VERSION ""

NS_ :

BS_:

BU_: TCM_Diesel ECM_Diesel BECMB_EPM TCM ECM Generic_BCM GWM _delete APIM BCM DCDC_VQM PAM TSTR PCM

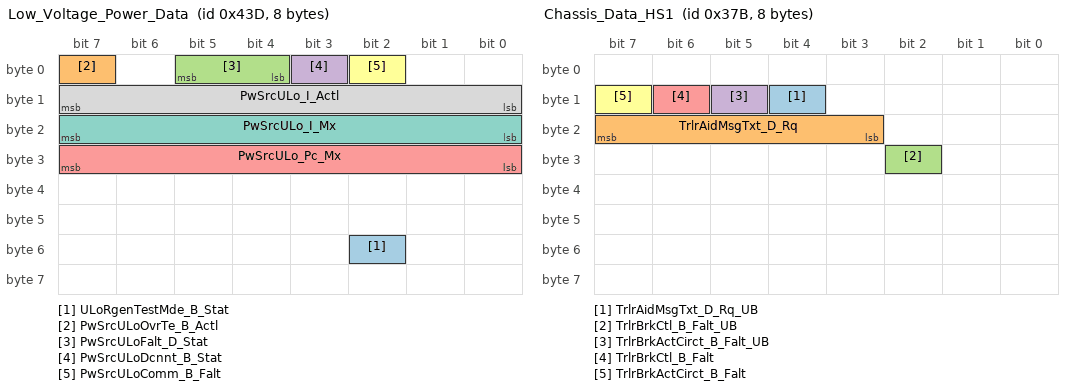
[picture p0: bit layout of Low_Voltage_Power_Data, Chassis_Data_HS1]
BO_ 1085 Low_Voltage_Power_Data: 8 PCM
 SG_ ULoRgenTestMde_B_Stat : 50|1@0+ (1,0) [0|1] "SED"  BCM
 SG_ PwSrcULoOvrTe_B_Actl : 7|1@0+ (1,0) [0|1] "SED"  BCM
 SG_ PwSrcULoFalt_D_Stat : 5|2@0+ (1,0) [0|3] "SED"  GWM,BCM
 SG_ PwSrcULoDcnnt_B_Stat : 3|1@0+ (1,0) [0|1] "SED"  BCM
 SG_ PwSrcULo_Pc_Mx : 31|8@0+ (0.4,0) [0|101.6] "%"  GWM,BCM
 SG_ PwSrcULoComm_B_Falt : 2|1@0+ (1,0) [0|1] "SED"  BCM
 SG_ PwSrcULo_I_Mx : 23|8@0+ (1,0) [0|254] "ampere"  GWM,BCM
 SG_ PwSrcULo_I_Actl : 15|8@0+ (1,0) [0|254] "ampere"  GWM,BCM

BO_ 891 Chassis_Data_HS1: 8 GWM
 SG_ TrlrAidMsgTxt_D_Rq_UB : 12|1@0+ (1,0) [0|1] "SED"  PAM
 SG_ TrlrAidMsgTxt_D_Rq : 23|5@0+ (1,0) [0|31] "SED"  PAM
 SG_ TrlrBrkCtl_B_Falt_UB : 26|1@0+ (1,0) [0|1] "SED"  PAM
 SG_ TrlrBrkActCirct_B_Falt_UB : 13|1@0+ (1,0) [0|1] "SED"  PAM
 SG_ TrlrBrkCtl_B_Falt : 14|1@0+ (1,0) [0|1] "SED"  PAM
 SG_ TrlrBrkActCirct_B_Falt : 15|1@0+ (1,0) [0|1] "SED"  PAM

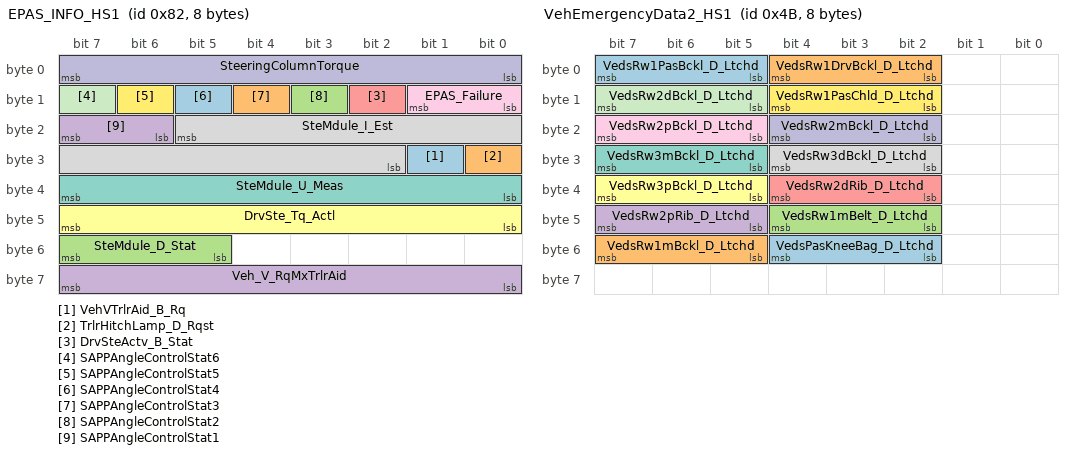
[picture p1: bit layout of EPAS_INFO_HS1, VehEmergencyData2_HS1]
BO_ 130 EPAS_INFO_HS1: 8 GWM
 SG_ VehVTrlrAid_B_Rq : 25|1@0+ (1,0) [0|1] "SED"  ECM_Diesel,ECM,PCM
 SG_ TrlrHitchLamp_D_Rqst : 24|1@0+ (1,0) [0|1] "SED"  BCM
 SG_ SteMdule_D_Stat : 55|3@0+ (1,0) [0|7] "SED" Vector__XXX
 SG_ Veh_V_RqMxTrlrAid : 63|8@0+ (0.1,0) [0|25.5] "km/h"  ECM_Diesel,ECM,PCM
 SG_ DrvSteActv_B_Stat : 10|1@0+ (1,0) [0|1] "SED" Vector__XXX
 SG_ DrvSte_Tq_Actl : 47|8@0+ (0.0625,-8) [-8|7.8125] "Nm" Vector__XXX
 SG_ SteMdule_U_Meas : 39|8@0+ (0.05,6) [6|18.7] "Volts"  BCM
 SG_ SteMdule_I_Est : 21|12@0+ (0.05,-64) [-64|140.7] "Amps"  BCM
 SG_ EPAS_Failure : 9|2@0+ (1,0) [0|3] "SED"  PAM
 SG_ SteeringColumnTorque : 7|8@0+ (0.0625,-8) [-8|7.8125] "Nm"  PAM
 SG_ SAPPAngleControlStat6 : 15|1@0+ (1,0) [0|1] "SED"  PAM
 SG_ SAPPAngleControlStat5 : 14|1@0+ (1,0) [0|1] "SED"  PAM
 SG_ SAPPAngleControlStat4 : 13|1@0+ (1,0) [0|1] "SED"  PAM
 SG_ SAPPAngleControlStat3 : 12|1@0+ (1,0) [0|1] "SED"  PAM
 SG_ SAPPAngleControlStat2 : 11|1@0+ (1,0) [0|1] "SED"  PAM
 SG_ SAPPAngleControlStat1 : 23|2@0+ (1,0) [0|3] "SED"  PAM

BO_ 75 VehEmergencyData2_HS1: 8 GWM
 SG_ VedsPasKneeBag_D_Ltchd : 52|3@0+ (1,0) [0|7] "SED"  APIM
 SG_ VedsRw1mBckl_D_Ltchd : 55|3@0+ (1,0) [0|7] "SED"  APIM
 SG_ VedsRw1mBelt_D_Ltchd : 44|3@0+ (1,0) [0|7] "SED"  APIM
 SG_ VedsRw2pRib_D_Ltchd : 47|3@0+ (1,0) [0|7] "SED"  APIM
 SG_ VedsRw2dRib_D_Ltchd : 36|3@0+ (1,0) [0|7] "SED"  APIM
 SG_ VedsRw3pBckl_D_Ltchd : 39|3@0+ (1,0) [0|7] "SED"  APIM
 SG_ VedsRw3mBckl_D_Ltchd : 31|3@0+ (1,0) [0|7] "SED"  APIM
 SG_ VedsRw3dBckl_D_Ltchd : 28|3@0+ (1,0) [0|7] "SED"  APIM
 SG_ VedsRw2pBckl_D_Ltchd : 23|3@0+ (1,0) [0|7] "SED"  APIM
 SG_ VedsRw2mBckl_D_Ltchd : 20|3@0+ (1,0) [0|7] "SED"  APIM
 SG_ VedsRw2dBckl_D_Ltchd : 15|3@0+ (1,0) [0|7] "SED"  APIM
 SG_ VedsRw1PasChld_D_Ltchd : 12|3@0+ (1,0) [0|7] "SED"  APIM
 SG_ VedsRw1PasBckl_D_Ltchd : 7|3@0+ (1,0) [0|7] "SED"  APIM
 SG_ VedsRw1DrvBckl_D_Ltchd : 4|3@0+ (1,0) [0|7] "SED"  APIM

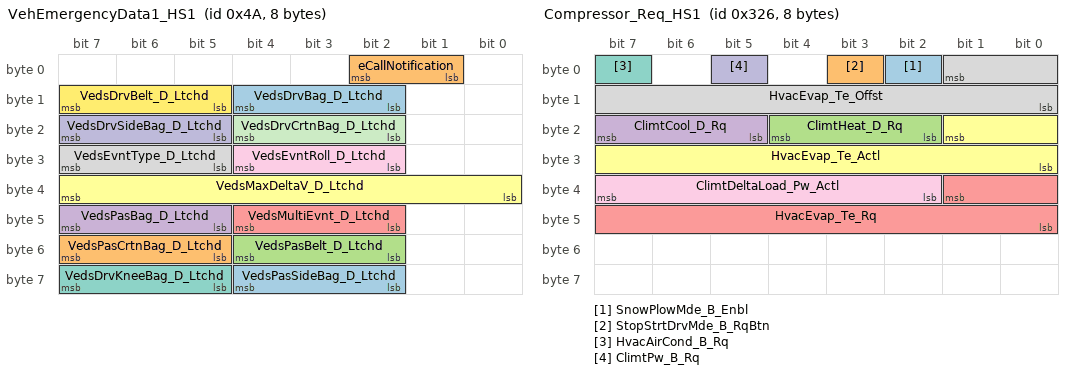
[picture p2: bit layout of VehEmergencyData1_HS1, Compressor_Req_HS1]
BO_ 74 VehEmergencyData1_HS1: 8 GWM
 SG_ VedsPasSideBag_D_Ltchd : 60|3@0+ (1,0) [0|7] "SED"  APIM
 SG_ VedsPasCrtnBag_D_Ltchd : 55|3@0+ (1,0) [0|7] "SED"  APIM
 SG_ VedsPasBelt_D_Ltchd : 52|3@0+ (1,0) [0|7] "SED"  APIM
 SG_ VedsPasBag_D_Ltchd : 47|3@0+ (1,0) [0|7] "SED"  APIM
 SG_ VedsMultiEvnt_D_Ltchd : 44|3@0+ (1,0) [0|7] "SED"  APIM
 SG_ VedsMaxDeltaV_D_Ltchd : 39|8@0+ (1,0) [0|255] "kph"  APIM
 SG_ VedsDrvKneeBag_D_Ltchd : 63|3@0+ (1,0) [0|7] "SED"  APIM
 SG_ VedsEvntType_D_Ltchd : 31|3@0+ (1,0) [0|7] "SED"  APIM
 SG_ VedsEvntRoll_D_Ltchd : 28|3@0+ (1,0) [0|7] "SED"  APIM
 SG_ VedsDrvSideBag_D_Ltchd : 23|3@0+ (1,0) [0|7] "SED"  APIM
 SG_ VedsDrvCrtnBag_D_Ltchd : 20|3@0+ (1,0) [0|7] "SED"  APIM
 SG_ VedsDrvBelt_D_Ltchd : 15|3@0+ (1,0) [0|7] "SED"  APIM
 SG_ VedsDrvBag_D_Ltchd : 12|3@0+ (1,0) [0|7] "SED"  APIM
 SG_ eCallNotification : 2|2@0+ (1,0) [0|3] "SED"  APIM

BO_ 1076 Cluster_Info3_HS1: 8 GWM
 SG_ CenterStackRing_D_Actl : 60|2@0+ (1,0) [0|3] "SED" Vector__XXX
 SG_ CenterStackRing_D_Actl_UB : 58|1@0+ (1,0) [0|1] "SED" Vector__XXX
 SG_ EngIdlShutDown_B_RqDrv_UB : 61|1@0+ (1,0) [0|1] "SED" Vector__XXX
 SG_ EngIdlShutDown_B_RqDrv : 62|1@0+ (1,0) [0|1] "SED"  ECM_Diesel,ECM,PCM
 SG_ OdoTripRx_B_Actl : 63|1@0+ (1,0) [0|1] "SED"  ECM_Diesel,ECM,PCM
 SG_ FuelLvlWarn_D_Actl : 49|2@0+ (1,0) [0|3] "SED" Vector__XXX
 SG_ TirePReset_B_Rq_UB : 18|1@0+ (1,0) [0|1] "SED"  BCM
 SG_ DrTGate_D_Rq : 51|2@0+ (1,0) [0|3] "SED"  BCM
 SG_ DrTGate_D_Rq_UB : 36|1@0+ (1,0) [0|1] "SED"  BCM
 SG_ Veh_V_CompLimMx : 35|12@0+ (0.1,0) [0|409.5] "km/h"  ECM_Diesel,ECM,PCM
 SG_ DieslFuelBio_B_ActlDrv : 3|1@0+ (1,0) [0|1] "SED"  ECM_Diesel
 SG_ FuelSecndActv_B_Actl : 7|1@0+ (1,0) [0|1] "SED"  ECM_Diesel
 SG_ FuelLvlPssvSide_No_Raw : 17|10@0+ (1,0) [0|1023] "Unitless"  ECM_Diesel,ECM,PCM
 SG_ FUEL_SENSOR_NUM : 2|1@0+ (1,0) [0|1] "SED"  ECM_Diesel,ECM,PCM
 SG_ FuelLvlActvSide_No_Raw : 1|10@0+ (1,0) [0|1023] "Unitless"  ECM_Diesel,ECM,PCM
 SG_ WndwPsngrSide_D_Stat : 53|2@0+ (1,0) [0|3] "SED"  ECM_Diesel,ECM,PCM
 SG_ WndwDrvSide_D_Stat : 55|2@0+ (1,0) [0|3] "SED"  ECM_Diesel,ECM,PCM
 SG_ WndwPsngrSide_D_Stat_UB : 56|1@0+ (1,0) [0|1] "SED"  ECM_Diesel,ECM,PCM
 SG_ DISPLAY_SPEED_SCALING : 23|4@0+ (0.5,100) [100|107.5] "%"  ECM_Diesel,ECM,PCM
 SG_ DISPLAY_SPEED_OFFSET : 6|3@0+ (0.5,0) [0|3.5] "kph"  ECM_Diesel,ECM,PCM
 SG_ WndwDrvSide_D_Stat_UB : 57|1@0+ (1,0) [0|1] "SED"  ECM_Diesel,ECM,PCM
 SG_ TirePReset_B_Rq : 19|1@0+ (1,0) [0|1] "Discrete"  BCM

BO_ 1072 Cluster_Info1_HS1: 8 GWM
 SG_ DrvPerfMde_D_Rq_UB : 56|1@0+ (1,0) [0|1] "SED" Vector__XXX
 SG_ DrvPerfMde_D_Rq : 55|2@0+ (1,0) [0|3] "SED" Vector__XXX
 SG_ ePRNDL_MODE_UB : 63|1@0+ (1,0) [0|1] "SED"  TCM_Diesel,TCM,ECM,PCM,BCM
 SG_ NtrlTowMdeEnbl_B_RqDrv_UB : 48|1@0+ (1,0) [0|1] "SED" Vector__XXX
 SG_ NtrlTowMdeEnbl_B_RqDrv : 6|1@0+ (1,0) [0|1] "SED" Vector__XXX
 SG_ Remote_Start_QuietMode_UB : 50|1@0+ (1,0) [0|1] "SED"  BCM
 SG_ Remote_Start_QuietMode : 51|1@0+ (1,0) [0|1] "SED"  BCM
 SG_ ParkDetect_Stat_UB : 52|1@0+ (1,0) [0|1] "SED"  BCM
 SG_ ParkDetect_Stat : 53|1@0+ (1,0) [0|1] "SED"  BCM
 SG_ TrlrLampCnnct_B_Actl_UB : 42|1@0+ (1,0) [0|1] "SED"  ECM_Diesel,ECM,PCM,BCM,PAM
 SG_ StopLamp_B_RqTrlrBrk_UB : 46|1@0+ (1,0) [0|1] "SED"  BCM
 SG_ StopLamp_B_RqTrlrBrk : 47|1@0+ (1,0) [0|1] "SED"  BCM
 SG_ OdometerMasterValue_UB : 1|1@0+ (1,0) [0|1] "SED"  BCM
 SG_ OdometerMasterValue : 15|24@0+ (1,0) [0|16777214] "km"  TCM_Diesel,ECM_Diesel,TCM,ECM,BCM,PCM
 SG_ MetricActv_B_Actl : 7|1@0+ (1,0) [0|1] "SED"  ECM_Diesel,ECM,PCM
 SG_ FrostWarn_D_Stat : 5|2@0+ (1,0) [0|3] "SED"  ECM_Diesel,ECM,PCM
 SG_ ReducedGuard_D_Rq_UB : 49|1@0+ (1,0) [0|1] "SED"  BCM
 SG_ ReducedGuard_D_Rq : 41|2@0+ (1,0) [0|3] "SED"  BCM
 SG_ ePRNDL_MODE : 0|1@0+ (1,0) [0|1] "SED"  TCM_Diesel,TCM,ECM,BCM,PCM
 SG_ EngOilLife_B_RqReset : 43|1@0+ (1,0) [0|1] "SED"  ECM_Diesel,ECM,PCM
 SG_ Outside_Air_Temp_Stat_UB : 2|1@0+ (1,0) [0|1] "SED"  PAM
 SG_ Outside_Air_Temp_Stat : 39|8@0+ (0.5,-40) [-40|86.5] "Degrees C"  ECM_Diesel,ECM,PCM,PAM
 SG_ KeyTypeChngMykey_D_Rq_UB : 60|1@0+ (1,0) [0|1] "SED"  BCM
 SG_ KeyTypeChngMykey_D_Rq : 62|2@0+ (1,0) [0|3] "SED"  BCM
 SG_ TrlrLampCnnct_B_Actl : 3|1@0+ (1,0) [0|1] "SED"  ECM_Diesel,ECM,BCM,PAM,PCM
 SG_ ManRgen_D_Rq : 45|2@0+ (1,0) [0|3] "SED"  ECM_Diesel

BO_ 1438 GWM_AutoSar_NetMgmt_HS1: 8 GWM
 SG_ GWM_AutoSar_NetworkMgmt_H1 : 7|64@0+ (1,0) [0|1.844674407371E+019] "unitless"  TCM_Diesel,ECM_Diesel,BECMB_EPM,TCM,ECM,BCM,PCM

BO_ 1814 TesterPhysicalReqGWM_H1: 8 TSTR
 SG_ TesterPhysicalReqGWM_H1 : 7|64@0+ (1,0) [0|1.84467E+019] "unitless"  GWM

BO_ 1822 TesterPhysicalResGWM_HS1: 8 GWM
 SG_ TesterPhysicalResGWM_H1 : 7|64@0+ (1,0) [0|1.84467E+019] "unitless"  TSTR

BO_ 806 Compressor_Req_HS1: 8 GWM
 SG_ SnowPlowMde_B_Enbl : 2|1@0+ (1,0) [0|1] "SED"  BCM
 SG_ StopStrtDrvMde_B_RqBtn : 3|1@0+ (1,0) [0|1] "SED"  ECM_Diesel,ECM,PCM
 SG_ ClimtHeat_D_Rq : 20|3@0+ (1,0) [0|7] "SED"  ECM_Diesel,ECM,PCM
 SG_ ClimtCool_D_Rq : 23|3@0+ (1,0) [0|7] "SED"  ECM_Diesel,ECM,PCM
 SG_ HvacEvap_Te_Rq : 33|10@0+ (0.125,-50) [-50|77.875] "Degrees C"  ECM_Diesel,ECM,PCM
 SG_ HvacEvap_Te_Actl : 17|10@0+ (0.125,-50) [-50|77.75] "Degrees C"  ECM_Diesel,ECM,PCM
 SG_ HvacAirCond_B_Rq : 7|1@0+ (1,0) [0|1] "SED"  ECM_Diesel,ECM,PCM
 SG_ HvacEvap_Te_Offst : 1|10@0+ (0.125,-50) [-50|77.875] "Degrees C"  ECM_Diesel,ECM,PCM
 SG_ ClimtDeltaLoad_Pw_Actl : 39|6@0+ (50,-1600) [-1600|1450] "watts" Vector__XXX
 SG_ ClimtPw_B_Rq : 5|1@0+ (1,0) [0|1] "SED"  ECM_Diesel,ECM,PCM

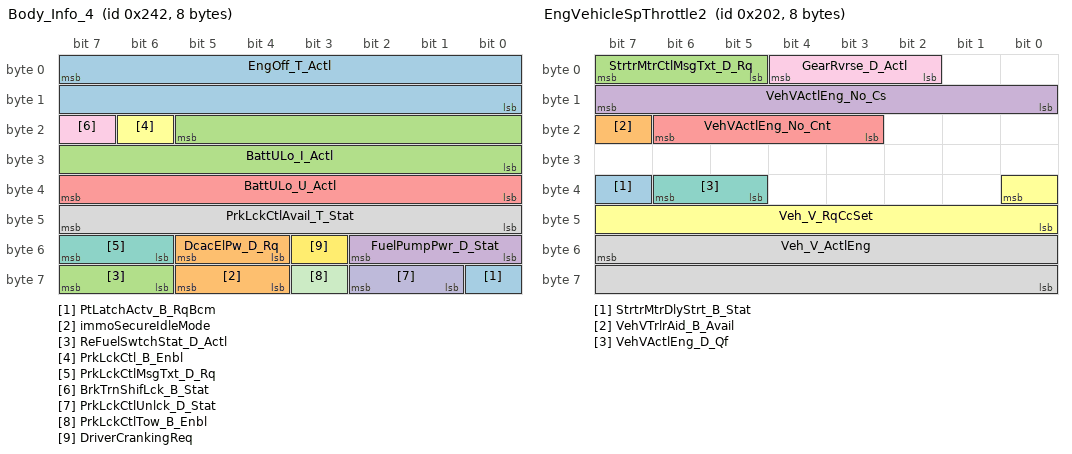
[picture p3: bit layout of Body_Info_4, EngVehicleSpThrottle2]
BO_ 578 Body_Info_4: 8 BCM
 SG_ PtLatchActv_B_RqBcm : 56|1@0+ (1,0) [0|1] "SED"  TCM_Diesel,ECM_Diesel,TCM,ECM,PCM,GWM
 SG_ immoSecureIdleMode : 61|2@0+ (1,0) [0|3] "SED"  ECM_Diesel,ECM,PCM,GWM
 SG_ ReFuelSwtchStat_D_Actl : 63|2@0+ (1,0) [0|3] "SED"  GWM
 SG_ FuelPumpPwr_D_Stat : 50|3@0+ (1,0) [0|7] "SED"  ECM_Diesel,ECM,PCM,GWM
 SG_ BattULo_U_Actl : 39|8@0+ (0.0625,0) [0|15.875] "volt"  ECM_Diesel,ECM,PCM,GWM
 SG_ PrkLckCtl_B_Enbl : 22|1@0+ (1,0) [0|1] "SED"  TCM_Diesel,TCM,GWM
 SG_ PrkLckCtlMsgTxt_D_Rq : 55|2@0+ (1,0) [0|3] "SED"  GWM
 SG_ PrkLckCtlAvail_T_Stat : 47|8@0+ (1,0) [0|255] "second"  GWM
 SG_ BrkTrnShifLck_B_Stat : 23|1@0+ (1,0) [0|1] "SED"  TCM,TCM_Diesel,GWM
 SG_ PrkLckCtlUnlck_D_Stat : 58|2@0+ (1,0) [0|3] "SED"  GWM
 SG_ PrkLckCtlTow_B_Enbl : 59|1@0+ (1,0) [0|1] "SED"  GWM
 SG_ DriverCrankingReq : 51|1@0+ (1,0) [0|1] "SED"  ECM_Diesel,ECM,GWM,PCM
 SG_ EngOff_T_Actl : 7|16@0+ (1,0) [0|65534] "second^0.5"  TCM_Diesel,ECM_Diesel,TCM,ECM,PCM,GWM
 SG_ DcacElPw_D_Rq : 53|2@0+ (1,0) [0|3] "SED"  ECM_Diesel,ECM,GWM,PCM
 SG_ BattULo_I_Actl : 21|14@0+ (0.0625,-512) [-512|511.875] "ampere"  ECM_Diesel,ECM,GWM,PCM

BO_ 514 EngVehicleSpThrottle2: 8 PCM
 SG_ StrtrMtrDlyStrt_B_Stat : 39|1@0+ (1,0) [0|1] "SED"  BCM
 SG_ VehVTrlrAid_B_Avail : 23|1@0+ (1,0) [0|1] "SED"  GWM
 SG_ StrtrMtrCtlMsgTxt_D_Rq : 7|3@0+ (1,0) [0|7] "SED"  GWM
 SG_ VehVActlEng_No_Cs : 15|8@0+ (1,0) [0|255] "Unitless"  GWM
 SG_ VehVActlEng_No_Cnt : 22|4@0+ (1,0) [0|15] "Unitless"  GWM
 SG_ Veh_V_RqCcSet : 32|9@0+ (0.5,0) [0|255.5] "kph"  TCM_Diesel,TCM,GWM
 SG_ VehVActlEng_D_Qf : 38|2@0+ (1,0) [0|3] "SED"  TCM_Diesel,TCM,PAM,BCM,GWM
 SG_ Veh_V_ActlEng : 55|16@0+ (0.01,0) [0|655.35] "kph"  TCM_Diesel,BECMB_EPM,TCM,PAM,BCM,GWM
 SG_ GearRvrse_D_Actl : 4|3@0+ (1,0) [0|7] "SED"  GWM,BCM,PAM

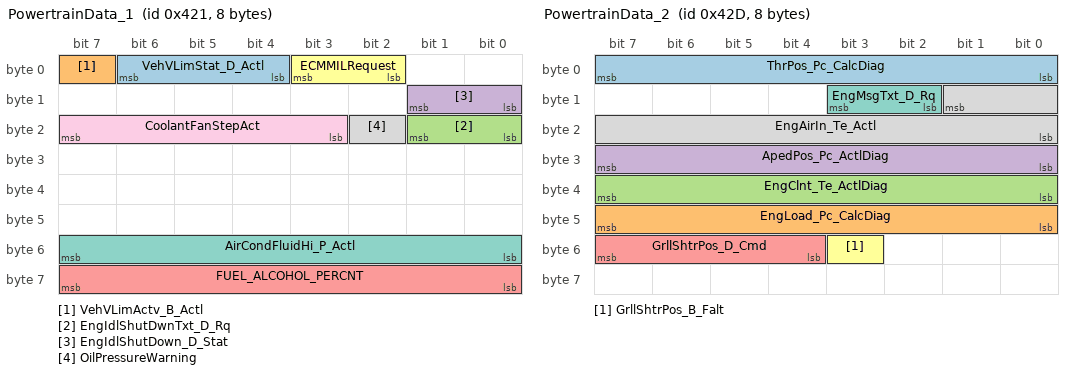
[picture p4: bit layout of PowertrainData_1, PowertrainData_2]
BO_ 1057 PowertrainData_1: 8 PCM
 SG_ VehVLimStat_D_Actl : 6|3@0+ (1,0) [0|7] "SED"  TCM_Diesel,GWM,TCM
 SG_ VehVLimActv_B_Actl : 7|1@0+ (1,0) [0|1] "SED"  TCM_Diesel,GWM,TCM
 SG_ EngIdlShutDwnTxt_D_Rq : 17|2@0+ (1,0) [0|3] "SED"  GWM
 SG_ EngIdlShutDown_D_Stat : 9|2@0+ (1,0) [0|3] "SED"  BCM,GWM
 SG_ FUEL_ALCOHOL_PERCNT : 63|8@0+ (0.393700787,0) [0|99.999899898] "Percent"  GWM
 SG_ ECMMILRequest : 3|2@0+ (1,0) [0|3] "SED"  BCM,GWM
 SG_ AirCondFluidHi_P_Actl : 55|8@0+ (0.125,0) [0|31.625] "bar"  GWM
 SG_ OilPressureWarning : 18|1@0+ (1,0) [0|1] "SED"  GWM
 SG_ CoolantFanStepAct : 23|5@0+ (1,0) [0|31] "Steps"  BCM,GWM

BO_ 1069 PowertrainData_2: 8 PCM
 SG_ ThrPos_Pc_CalcDiag : 7|8@0+ (0.392157,0) [0|100.000035] "%"  GWM
 SG_ EngLoad_Pc_CalcDiag : 47|8@0+ (0.392157,0) [0|100.000035] "%"  TCM_Diesel,GWM,TCM
 SG_ EngClnt_Te_ActlDiag : 39|8@0+ (1,-40) [-40|215] "degC"  TCM_Diesel,GWM,TCM
 SG_ ApedPos_Pc_ActlDiag : 31|8@0+ (0.392157,0) [0|100.000035] "%"  TCM_Diesel,GWM,TCM
 SG_ GrllShtrPos_D_Cmd : 55|4@0+ (1,0) [0|15] "SED"  GWM,BCM
 SG_ GrllShtrPos_B_Falt : 51|1@0+ (1,0) [0|1] "SED"  GWM,BCM
 SG_ EngMsgTxt_D_Rq : 11|2@0+ (1,0) [0|3] "SED"  GWM
 SG_ EngAirIn_Te_Actl : 9|10@0+ (0.25,-128) [-128|127.25] "degC"  TCM_Diesel,TCM,GWM,BCM

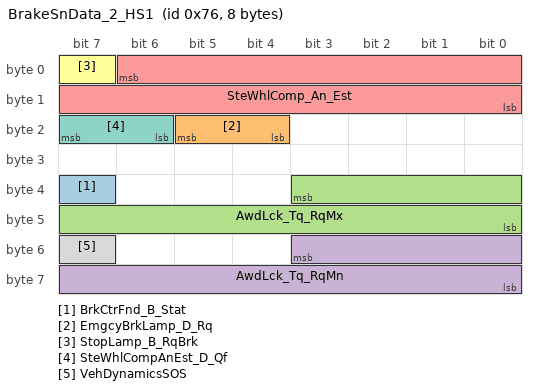
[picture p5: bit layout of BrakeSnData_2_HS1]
BO_ 118 BrakeSnData_2_HS1: 8 GWM
 SG_ BrkCtrFnd_B_Stat : 39|1@0+ (1,0) [0|1] "SED" Vector__XXX
 SG_ EmgcyBrkLamp_D_Rq : 21|2@0+ (1,0) [0|3] "SED"  BCM
 SG_ AwdLck_Tq_RqMx : 35|12@0+ (1,0) [0|4095] "Nm" Vector__XXX
 SG_ AwdLck_Tq_RqMn : 51|12@0+ (1,0) [0|4095] "Nm" Vector__XXX
 SG_ SteWhlComp_An_Est : 6|15@0+ (0.1,-1600) [-1600|1676.7] "deg"  TCM_Diesel,ECM_Diesel,TCM,ECM,BCM,PAM,PCM
 SG_ StopLamp_B_RqBrk : 7|1@0+ (1,0) [0|1] "SED"  BCM
 SG_ SteWhlCompAnEst_D_Qf : 23|2@0+ (1,0) [0|3] "SED"  TCM_Diesel,ECM_Diesel,TCM,ECM,BCM,PAM,PCM
 SG_ VehDynamicsSOS : 55|1@0+ (1,0) [0|1] "SED"  BCM

BO_TX_BU_ 1085 : ECM_Diesel,ECM,PCM;
BO_TX_BU_ 514 : ECM_Diesel,ECM,PCM;
BO_TX_BU_ 1057 : ECM_Diesel,ECM,PCM;
BO_TX_BU_ 1069 : ECM_Diesel,ECM,PCM;
CM_ SG_ 1085 ULoRgenTestMde_B_Stat "Signal not transmitted on HEV variants.";
CM_ SG_ 1085 PwSrcULoComm_B_Falt "Signal not transmitted on HEV variants.";
CM_ BO_ 130 "Added 5/13/05 for Mazda J61A/2007MY, T.Yamashita.";
CM_ SG_ 130 VehVTrlrAid_B_Rq "VR session start- req. limit blower speed no more than X volts.  CC restriction on time msg. will be honored.Double Event msg1st event to request limit, 2nd event to release limit, No msg. CC Grammar v7.xls";
CM_ BO_ 74 "Reserve eCallNotification message";
CM_ SG_ 1076 CenterStackRing_D_Actl "The Center Stack sends the CPLR a signal to turn On or Off the light Ring, This is a customer selectable preference switch";
CM_ SG_ 1072 StopLamp_B_RqTrlrBrk "Signal not transmitted on all variants.";
CM_ SG_ 1072 MetricActv_B_Actl "0 =Inactive(English), 1=Active(Metric)";
CM_ SG_ 1072 Outside_Air_Temp_Stat "Filtered value, i.e. same as disply for customer";
CM_ SG_ 1072 TrlrLampCnnct_B_Actl "Not supported on CD4 M1";
CM_ SG_ 514 GearRvrse_D_Actl "Do not implement GearRvrse_D_Actl  until eTracker 8804151 is approved, 11/24/09";
CM_ SG_ 1057 VehVLimStat_D_Actl "ECM_D and ECM_G Tx only on P552";
CM_ SG_ 1057 VehVLimActv_B_Actl "ECM_G and ECM_D Tx only on P552";
CM_ SG_ 1057 EngIdlShutDown_D_Stat "Signal not transmitted on diesel variants.";
CM_ SG_ 1057 FUEL_ALCOHOL_PERCNT "signal not transmitted on diesel and HEV variants.";
CM_ SG_ 1069 ThrPos_Pc_CalcDiag "ECM_D Tx only on P552";
CM_ SG_ 1069 EngLoad_Pc_CalcDiag "Tx by ECM_G and ECM_D";
CM_ SG_ 1069 EngClnt_Te_ActlDiag "Signal transmitted by ECM_D and ECM_G on P552 not PCM
";
CM_ SG_ 1069 ApedPos_Pc_ActlDiag "Signal not transmitted on gas variants.";
CM_ SG_ 1069 EngMsgTxt_D_Rq "Signal not transmitted on diesel variants.";
BA_DEF_ SG_  "U_U55x_MY18_Gas_Rx" ENUM  "No","Yes";
BA_DEF_ SG_  "U_U55x_MY18_Gas_Tx" ENUM  "No","Yes";
BA_DEF_ BO_  "FrameGatewayNetwork" STRING ;
BA_DEF_ SG_  "U_C489_MY17_Gas_Rx" ENUM  "No","Yes";
BA_DEF_ SG_  "U_CD43_MY17_Gas_Rx" ENUM  "No","Yes";
BA_DEF_ SG_  "U_P552_MY17_Gas_Rx" ENUM  "No","Yes";
BA_DEF_ SG_  "U_B515_MCA_MY17_Diesel_Rx" ENUM  "No","Yes";
BA_DEF_ SG_  "U_B515_MCA_MY17_Gas_Rx" ENUM  "No","Yes";
BA_DEF_ SG_  "U_C489_MY17_Gas_Tx" ENUM  "No","Yes";
BA_DEF_ SG_  "U_CD43_MY17_Gas_Tx" ENUM  "No","Yes";
BA_DEF_ SG_  "U_P552_MY17_Gas_Tx" ENUM  "No","Yes";
BA_DEF_ SG_  "U_B515_MCA_MY17_Diesel_Tx" ENUM  "No","Yes";
BA_DEF_ SG_  "U_B515_MCA_MY17_Gas_Tx" ENUM  "No","Yes";
BA_DEF_ SG_  "U_CD4_MY17_Diesel_Rx" ENUM  "No","Yes";
BA_DEF_ SG_  "U_CD4_MY17_Gas_Rx" ENUM  "No","Yes";
BA_DEF_ SG_  "U_CD4_MY17_Hev_Rx" ENUM  "No","Yes";
BA_DEF_ SG_  "U_CD4_MY17_Phev_Rx" ENUM  "No","Yes";
BA_DEF_ SG_  "U_CD42_MY16_Diesel_Rx" ENUM  "No","Yes";
BA_DEF_ SG_  "U_CD42_MY16_Gas_Rx" ENUM  "No","Yes";
BA_DEF_ SG_  "U_CD4_MY17_Diesel_Tx" ENUM  "No","Yes";
BA_DEF_ SG_  "U_CD4_MY17_Gas_Tx" ENUM  "No","Yes";
BA_DEF_ SG_  "U_CD4_MY17_Hev_Tx" ENUM  "No","Yes";
BA_DEF_ SG_  "U_CD4_MY17_Phev_Tx" ENUM  "No","Yes";
BA_DEF_ SG_  "U_CD42_MY16_Diesel_Tx" ENUM  "No","Yes";
BA_DEF_ SG_  "U_CD42_MY16_Gas_Tx" ENUM  "No","Yes";
BA_DEF_ SG_  "U_CD42_MY15_Diesel_Rx" ENUM  "No","Yes";
BA_DEF_ SG_  "U_CD42_MY15_Gas_Rx" ENUM  "No","Yes";
BA_DEF_ SG_  "U_U502_MY16_Gas_Rx" ENUM  "No","Yes";
BA_DEF_ SG_  "U_P558_MY17_Gas_Rx" ENUM  "No","Yes";
BA_DEF_ SG_  "U_P558_MY17_Diesel_Rx" ENUM  "No","Yes";
BA_DEF_ SG_  "U_V36X_MY16_5_Diesel_Rx" ENUM  "No","Yes";
BA_DEF_ SG_  "U_U502_MY16_Gas_Tx" ENUM  "No","Yes";
BA_DEF_ SG_  "U_P558_MY17_Gas_Tx" ENUM  "No","Yes";
BA_DEF_ SG_  "U_P558_MY17_Diesel_Tx" ENUM  "No","Yes";
BA_DEF_ SG_  "U_V36X_MY16_5_Diesel_Tx" ENUM  "No","Yes";
BA_DEF_ SG_  "GenSigTimeoutTime_TCM" INT 0 100000;
BA_DEF_ SG_  "Gateway_ID" INT 0 0;
BA_DEF_ BO_  "FrameGatewayMS1" HEX 0 1407;
BA_DEF_ BO_  "FrameGatewayHS2" HEX 0 1407;
BA_DEF_ BO_  "NetworkInitialization" ENUM  "No","Yes";
BA_DEF_ BO_  "FrameGatewayId" HEX 0 1407;
BA_DEF_ BO_  "GenMsgDelayTime" INT 0 1000;
BA_DEF_ BO_  "GenMsgCycleTime" INT 0 100000;
BA_DEF_ BO_  "GenMsgSendType" ENUM  "FixedPeriodic","Event","EnabledPeriodic","NotUsed","NotUsed","EventPeriodic","NotUsed","NotUsed","NoMsgSendType";
BA_DEF_ SG_  "U_CD4_MY14_Phev_Tx" ENUM  "No","Yes";
BA_DEF_ SG_  "U_CD4_MY14_Hev_Tx" ENUM  "No","Yes";
BA_DEF_ SG_  "U_CD4_MY14_Gas_Tx" ENUM  "No","Yes";
BA_DEF_ SG_  "U_CD4_MY14_Diesel_Tx" ENUM  "No","Yes";
BA_DEF_ SG_  "U_CD43_MY16_Gas_Tx" ENUM  "No","Yes";
BA_DEF_ SG_  "U_UP375_MY15_Diesel_Tx" ENUM  "No","Yes";
BA_DEF_ SG_  "U_UP375_MY15_Gas_Tx" ENUM  "No","Yes";
BA_DEF_ SG_  "U_U502_MY15_Gas_Tx" ENUM  "No","Yes";
BA_DEF_ SG_  "U_C489_MY14_Gas_Tx" ENUM  "No","Yes";
BA_DEF_ SG_  "U_S550_MY15_Gas_Tx" ENUM  "No","Yes";
BA_DEF_ SG_  "U_P552_MY15_Gas_Tx" ENUM  "No","Yes";
BA_DEF_ SG_  "U_CD42_MY14_Gas_Tx" ENUM  "No","Yes";
BA_DEF_ SG_  "U_CD42_MY14_Diesel_Tx" ENUM  "No","Yes";
BA_DEF_ SG_  "U_CD4_MY13_Phev_Tx" ENUM  "No","Yes";
BA_DEF_ SG_  "U_CD4_MY13_Hev_Tx" ENUM  "No","Yes";
BA_DEF_ SG_  "U_CD4_MY13_Gas_Tx" ENUM  "No","Yes";
BA_DEF_ SG_  "U_CD4_MY13_Diesel_Tx" ENUM  "No","Yes";
BA_DEF_ SG_  "U_CD4_MY14_Phev_Rx" ENUM  "No","Yes";
BA_DEF_ SG_  "U_CD4_MY14_Hev_Rx" ENUM  "No","Yes";
BA_DEF_ SG_  "U_CD4_MY14_Gas_Rx" ENUM  "No","Yes";
BA_DEF_ SG_  "U_CD4_MY14_Diesel_Rx" ENUM  "No","Yes";
BA_DEF_ SG_  "U_CD43_MY16_Gas_Rx" ENUM  "No","Yes";
BA_DEF_ SG_  "U_UP375_MY15_Diesel_Rx" ENUM  "No","Yes";
BA_DEF_ SG_  "U_UP375_MY15_Gas_Rx" ENUM  "No","Yes";
BA_DEF_ SG_  "U_B479_MY15_Gas_Rx" ENUM  "No","Yes";
BA_DEF_ SG_  "U_U502_MY15_Gas_Rx" ENUM  "No","Yes";
BA_DEF_ SG_  "U_C489_MY14_Gas_Rx" ENUM  "No","Yes";
BA_DEF_ SG_  "U_S550_MY15_Gas_Rx" ENUM  "No","Yes";
BA_DEF_ SG_  "U_P552_MY15_Gas_Rx" ENUM  "No","Yes";
BA_DEF_ SG_  "U_CD42_MY14_Gas_Rx" ENUM  "No","Yes";
BA_DEF_ SG_  "U_CD42_MY14_Diesel_Rx" ENUM  "No","Yes";
BA_DEF_ SG_  "U_CD4_MY13_Phev_Rx" ENUM  "No","Yes";
BA_DEF_ SG_  "U_CD4_MY13_Hev_Rx" ENUM  "No","Yes";
BA_DEF_ SG_  "U_CD4_MY13_Gas_Rx" ENUM  "No","Yes";
BA_DEF_ SG_  "U_CD4_MY13_Diesel_Rx" ENUM  "No","Yes";
BA_DEF_ SG_  "ContentDependant" ENUM  "No","Yes";
BA_DEF_ SG_  "GenSigStartValue" INT 0 1000000000;
BA_DEF_ SG_  "CrossOver_LIN" ENUM  "No","Yes";
BA_DEF_ SG_  "CrossOver_InfoCAN" ENUM  "No","Yes";
BA_DEF_ SG_  "WakeupSignal" ENUM  "No","Yes";
BA_DEF_ SG_  "GenSigMissingSourceValue" INT 0 1000000000;
BA_DEF_ SG_  "GenSigSendType" ENUM  "Cyclic","OnWrite","vector_leerstring","OnChange","vector_leerstring","IfActive","vector_leerstring","NoSigSendType";
BA_DEF_ BO_  "NmAsrMessage" ENUM  "No","Yes";
BA_DEF_ BO_  "DiagRequest" ENUM  "No","Yes";
BA_DEF_ BO_  "DiagResponse" ENUM  "No","Yes";
BA_DEF_ BO_  "GenMsgILSupport" ENUM  "No","Yes";
BA_DEF_DEF_  "U_U55x_MY18_Gas_Rx" "No";
BA_DEF_DEF_  "U_U55x_MY18_Gas_Tx" "No";
BA_DEF_DEF_  "FrameGatewayNetwork" "NONE";
BA_DEF_DEF_  "U_C489_MY17_Gas_Rx" "No";
BA_DEF_DEF_  "U_CD43_MY17_Gas_Rx" "No";
BA_DEF_DEF_  "U_P552_MY17_Gas_Rx" "No";
BA_DEF_DEF_  "U_B515_MCA_MY17_Diesel_Rx" "No";
BA_DEF_DEF_  "U_B515_MCA_MY17_Gas_Rx" "No";
BA_DEF_DEF_  "U_C489_MY17_Gas_Tx" "No";
BA_DEF_DEF_  "U_CD43_MY17_Gas_Tx" "No";
BA_DEF_DEF_  "U_P552_MY17_Gas_Tx" "No";
BA_DEF_DEF_  "U_B515_MCA_MY17_Diesel_Tx" "No";
BA_DEF_DEF_  "U_B515_MCA_MY17_Gas_Tx" "No";
BA_DEF_DEF_  "U_CD4_MY17_Diesel_Rx" "No";
BA_DEF_DEF_  "U_CD4_MY17_Gas_Rx" "No";
BA_DEF_DEF_  "U_CD4_MY17_Hev_Rx" "No";
BA_DEF_DEF_  "U_CD4_MY17_Phev_Rx" "No";
BA_DEF_DEF_  "U_CD42_MY16_Diesel_Rx" "No";
BA_DEF_DEF_  "U_CD42_MY16_Gas_Rx" "No";
BA_DEF_DEF_  "U_CD4_MY17_Diesel_Tx" "No";
BA_DEF_DEF_  "U_CD4_MY17_Gas_Tx" "No";
BA_DEF_DEF_  "U_CD4_MY17_Hev_Tx" "No";
BA_DEF_DEF_  "U_CD4_MY17_Phev_Tx" "No";
BA_DEF_DEF_  "U_CD42_MY16_Diesel_Tx" "No";
BA_DEF_DEF_  "U_CD42_MY16_Gas_Tx" "No";
BA_DEF_DEF_  "U_CD42_MY15_Diesel_Rx" "No";
BA_DEF_DEF_  "U_CD42_MY15_Gas_Rx" "No";
BA_DEF_DEF_  "U_U502_MY16_Gas_Rx" "No";
BA_DEF_DEF_  "U_P558_MY17_Gas_Rx" "No";
BA_DEF_DEF_  "U_P558_MY17_Diesel_Rx" "No";
BA_DEF_DEF_  "U_V36X_MY16_5_Diesel_Rx" "No";
BA_DEF_DEF_  "U_U502_MY16_Gas_Tx" "No";
BA_DEF_DEF_  "U_P558_MY17_Gas_Tx" "No";
BA_DEF_DEF_  "U_P558_MY17_Diesel_Tx" "No";
BA_DEF_DEF_  "U_V36X_MY16_5_Diesel_Tx" "No";
BA_DEF_DEF_  "GenSigTimeoutTime_TCM" 5000;
BA_DEF_DEF_  "Gateway_ID" 0;
BA_DEF_DEF_  "FrameGatewayMS1" 0;
BA_DEF_DEF_  "FrameGatewayHS2" 0;
BA_DEF_DEF_  "NetworkInitialization" "No";
BA_DEF_DEF_  "FrameGatewayId" 0;
BA_DEF_DEF_  "GenMsgDelayTime" 20;
BA_DEF_DEF_  "GenMsgCycleTime" 0;
BA_DEF_DEF_  "GenMsgSendType" "NoMsgSendType";
BA_DEF_DEF_  "U_CD4_MY14_Phev_Tx" "No";
BA_DEF_DEF_  "U_CD4_MY14_Hev_Tx" "No";
BA_DEF_DEF_  "U_CD4_MY14_Gas_Tx" "No";
BA_DEF_DEF_  "U_CD4_MY14_Diesel_Tx" "No";
BA_DEF_DEF_  "U_CD43_MY16_Gas_Tx" "No";
BA_DEF_DEF_  "U_UP375_MY15_Diesel_Tx" "No";
BA_DEF_DEF_  "U_UP375_MY15_Gas_Tx" "No";
BA_DEF_DEF_  "U_U502_MY15_Gas_Tx" "No";
BA_DEF_DEF_  "U_C489_MY14_Gas_Tx" "No";
BA_DEF_DEF_  "U_S550_MY15_Gas_Tx" "No";
BA_DEF_DEF_  "U_P552_MY15_Gas_Tx" "No";
BA_DEF_DEF_  "U_CD42_MY14_Gas_Tx" "No";
BA_DEF_DEF_  "U_CD42_MY14_Diesel_Tx" "No";
BA_DEF_DEF_  "U_CD4_MY13_Phev_Tx" "No";
BA_DEF_DEF_  "U_CD4_MY13_Hev_Tx" "No";
BA_DEF_DEF_  "U_CD4_MY13_Gas_Tx" "No";
BA_DEF_DEF_  "U_CD4_MY13_Diesel_Tx" "No";
BA_DEF_DEF_  "U_CD4_MY14_Phev_Rx" "No";
BA_DEF_DEF_  "U_CD4_MY14_Hev_Rx" "No";
BA_DEF_DEF_  "U_CD4_MY14_Gas_Rx" "No";
BA_DEF_DEF_  "U_CD4_MY14_Diesel_Rx" "No";
BA_DEF_DEF_  "U_CD43_MY16_Gas_Rx" "No";
BA_DEF_DEF_  "U_UP375_MY15_Diesel_Rx" "No";
BA_DEF_DEF_  "U_UP375_MY15_Gas_Rx" "No";
BA_DEF_DEF_  "U_B479_MY15_Gas_Rx" "No";
BA_DEF_DEF_  "U_U502_MY15_Gas_Rx" "No";
BA_DEF_DEF_  "U_C489_MY14_Gas_Rx" "No";
BA_DEF_DEF_  "U_S550_MY15_Gas_Rx" "No";
BA_DEF_DEF_  "U_P552_MY15_Gas_Rx" "No";
BA_DEF_DEF_  "U_CD42_MY14_Gas_Rx" "No";
BA_DEF_DEF_  "U_CD42_MY14_Diesel_Rx" "No";
BA_DEF_DEF_  "U_CD4_MY13_Phev_Rx" "No";
BA_DEF_DEF_  "U_CD4_MY13_Hev_Rx" "No";
BA_DEF_DEF_  "U_CD4_MY13_Gas_Rx" "No";
BA_DEF_DEF_  "U_CD4_MY13_Diesel_Rx" "No";
BA_DEF_DEF_  "ContentDependant" "No";
BA_DEF_DEF_  "GenSigStartValue" 0;
BA_DEF_DEF_  "CrossOver_LIN" "No";
BA_DEF_DEF_  "CrossOver_InfoCAN" "No";
BA_DEF_DEF_  "WakeupSignal" "No";
BA_DEF_DEF_  "GenSigMissingSourceValue" 0;
BA_DEF_DEF_  "GenSigSendType" "NoSigSendType";
BA_DEF_DEF_  "NmAsrMessage" "No";
BA_DEF_DEF_  "DiagRequest" "No";
BA_DEF_DEF_  "DiagResponse" "No";
BA_DEF_DEF_  "GenMsgILSupport" "Yes";
BA_ "GenMsgSendType" BO_ 1085 0;
BA_ "GenMsgCycleTime" BO_ 1085 50;
BA_ "GenMsgSendType" BO_ 891 0;
BA_ "GenMsgCycleTime" BO_ 891 100;
BA_ "FrameGatewayNetwork" BO_ 130 "HS2_CAN";
BA_ "GenMsgDelayTime" BO_ 130 10;
BA_ "FrameGatewayId" BO_ 130 130;
BA_ "FrameGatewayHS2" BO_ 130 130;
BA_ "FrameGatewayNetwork" BO_ 75 "HS2_CAN";
BA_ "FrameGatewayId" BO_ 75 75;
BA_ "FrameGatewayHS2" BO_ 75 75;
BA_ "FrameGatewayNetwork" BO_ 74 "HS2_CAN";
BA_ "FrameGatewayId" BO_ 74 74;
BA_ "FrameGatewayHS2" BO_ 74 74;
BA_ "GenMsgSendType" BO_ 1076 5;
BA_ "GenMsgCycleTime" BO_ 1076 100;
BA_ "GenMsgSendType" BO_ 1072 5;
BA_ "GenMsgCycleTime" BO_ 1072 100;
BA_ "GenMsgILSupport" BO_ 1438 0;
BA_ "NmAsrMessage" BO_ 1438 1;
BA_ "GenMsgSendType" BO_ 1438 1;
BA_ "GenMsgILSupport" BO_ 1814 0;
BA_ "DiagRequest" BO_ 1814 1;
BA_ "GenMsgSendType" BO_ 1814 1;
BA_ "GenMsgDelayTime" BO_ 1814 0;
BA_ "GenMsgILSupport" BO_ 1822 0;
BA_ "DiagResponse" BO_ 1822 1;
BA_ "GenMsgSendType" BO_ 1822 1;
BA_ "GenMsgDelayTime" BO_ 1822 0;
BA_ "FrameGatewayNetwork" BO_ 806 "MS1_CAN";
BA_ "FrameGatewayId" BO_ 806 806;
BA_ "FrameGatewayMS1" BO_ 806 806;
BA_ "GenMsgSendType" BO_ 578 0;
BA_ "GenMsgCycleTime" BO_ 578 40;
BA_ "GenMsgSendType" BO_ 514 0;
BA_ "GenMsgCycleTime" BO_ 514 20;
BA_ "GenMsgDelayTime" BO_ 514 10;
BA_ "GenMsgSendType" BO_ 1057 0;
BA_ "GenMsgCycleTime" BO_ 1057 100;
BA_ "NetworkInitialization" BO_ 1057 1;
BA_ "GenMsgSendType" BO_ 1069 0;
BA_ "GenMsgCycleTime" BO_ 1069 100;
BA_ "NetworkInitialization" BO_ 1069 1;
BA_ "FrameGatewayNetwork" BO_ 118 "HS2_CAN";
BA_ "GenMsgDelayTime" BO_ 118 10;
BA_ "FrameGatewayId" BO_ 118 118;
BA_ "FrameGatewayHS2" BO_ 118 118;
BA_ "NetworkInitialization" BO_ 118 1;
BA_ "ContentDependant" SG_ 1085 ULoRgenTestMde_B_Stat 1;
BA_ "U_CD4_MY13_Diesel_Rx" SG_ 1085 ULoRgenTestMde_B_Stat 1;
BA_ "U_CD4_MY13_Gas_Rx" SG_ 1085 ULoRgenTestMde_B_Stat 1;
BA_ "U_CD4_MY13_Hev_Rx" SG_ 1085 ULoRgenTestMde_B_Stat 1;
BA_ "U_CD4_MY13_Phev_Rx" SG_ 1085 ULoRgenTestMde_B_Stat 1;
BA_ "U_CD42_MY14_Diesel_Rx" SG_ 1085 ULoRgenTestMde_B_Stat 1;
BA_ "U_CD42_MY14_Gas_Rx" SG_ 1085 ULoRgenTestMde_B_Stat 1;
BA_ "U_P552_MY15_Gas_Rx" SG_ 1085 ULoRgenTestMde_B_Stat 1;
BA_ "U_S550_MY15_Gas_Rx" SG_ 1085 ULoRgenTestMde_B_Stat 1;
BA_ "U_C489_MY14_Gas_Rx" SG_ 1085 ULoRgenTestMde_B_Stat 1;
BA_ "U_U502_MY15_Gas_Rx" SG_ 1085 ULoRgenTestMde_B_Stat 1;
BA_ "U_UP375_MY15_Gas_Rx" SG_ 1085 ULoRgenTestMde_B_Stat 1;
BA_ "U_UP375_MY15_Diesel_Rx" SG_ 1085 ULoRgenTestMde_B_Stat 1;
BA_ "U_CD43_MY16_Gas_Rx" SG_ 1085 ULoRgenTestMde_B_Stat 1;
BA_ "U_CD4_MY14_Diesel_Rx" SG_ 1085 ULoRgenTestMde_B_Stat 1;
BA_ "U_CD4_MY14_Gas_Rx" SG_ 1085 ULoRgenTestMde_B_Stat 1;
BA_ "U_CD4_MY14_Hev_Rx" SG_ 1085 ULoRgenTestMde_B_Stat 1;
BA_ "U_CD4_MY14_Phev_Rx" SG_ 1085 ULoRgenTestMde_B_Stat 1;
BA_ "U_CD4_MY13_Gas_Tx" SG_ 1085 ULoRgenTestMde_B_Stat 1;
BA_ "U_CD42_MY14_Gas_Tx" SG_ 1085 ULoRgenTestMde_B_Stat 1;
BA_ "U_P552_MY15_Gas_Tx" SG_ 1085 ULoRgenTestMde_B_Stat 1;
BA_ "U_S550_MY15_Gas_Tx" SG_ 1085 ULoRgenTestMde_B_Stat 1;
BA_ "U_C489_MY14_Gas_Tx" SG_ 1085 ULoRgenTestMde_B_Stat 1;
BA_ "U_U502_MY15_Gas_Tx" SG_ 1085 ULoRgenTestMde_B_Stat 1;
BA_ "U_UP375_MY15_Gas_Tx" SG_ 1085 ULoRgenTestMde_B_Stat 1;
BA_ "U_CD43_MY16_Gas_Tx" SG_ 1085 ULoRgenTestMde_B_Stat 1;
BA_ "U_CD4_MY14_Gas_Tx" SG_ 1085 ULoRgenTestMde_B_Stat 1;
BA_ "U_CD4_MY13_Diesel_Rx" SG_ 1085 PwSrcULoOvrTe_B_Actl 1;
BA_ "U_CD4_MY13_Gas_Rx" SG_ 1085 PwSrcULoOvrTe_B_Actl 1;
BA_ "U_CD4_MY13_Hev_Rx" SG_ 1085 PwSrcULoOvrTe_B_Actl 1;
BA_ "U_CD4_MY13_Phev_Rx" SG_ 1085 PwSrcULoOvrTe_B_Actl 1;
BA_ "U_CD42_MY14_Diesel_Rx" SG_ 1085 PwSrcULoOvrTe_B_Actl 1;
BA_ "U_CD42_MY14_Gas_Rx" SG_ 1085 PwSrcULoOvrTe_B_Actl 1;
BA_ "U_P552_MY15_Gas_Rx" SG_ 1085 PwSrcULoOvrTe_B_Actl 1;
BA_ "U_S550_MY15_Gas_Rx" SG_ 1085 PwSrcULoOvrTe_B_Actl 1;
BA_ "U_C489_MY14_Gas_Rx" SG_ 1085 PwSrcULoOvrTe_B_Actl 1;
BA_ "U_U502_MY15_Gas_Rx" SG_ 1085 PwSrcULoOvrTe_B_Actl 1;
BA_ "U_UP375_MY15_Gas_Rx" SG_ 1085 PwSrcULoOvrTe_B_Actl 1;
BA_ "U_UP375_MY15_Diesel_Rx" SG_ 1085 PwSrcULoOvrTe_B_Actl 1;
BA_ "U_CD43_MY16_Gas_Rx" SG_ 1085 PwSrcULoOvrTe_B_Actl 1;
BA_ "U_CD4_MY14_Diesel_Rx" SG_ 1085 PwSrcULoOvrTe_B_Actl 1;
BA_ "U_CD4_MY14_Gas_Rx" SG_ 1085 PwSrcULoOvrTe_B_Actl 1;
BA_ "U_CD4_MY14_Hev_Rx" SG_ 1085 PwSrcULoOvrTe_B_Actl 1;
BA_ "U_CD4_MY14_Phev_Rx" SG_ 1085 PwSrcULoOvrTe_B_Actl 1;
BA_ "U_CD4_MY13_Gas_Tx" SG_ 1085 PwSrcULoOvrTe_B_Actl 1;
BA_ "U_CD42_MY14_Gas_Tx" SG_ 1085 PwSrcULoOvrTe_B_Actl 1;
BA_ "U_P552_MY15_Gas_Tx" SG_ 1085 PwSrcULoOvrTe_B_Actl 1;
BA_ "U_S550_MY15_Gas_Tx" SG_ 1085 PwSrcULoOvrTe_B_Actl 1;
BA_ "U_C489_MY14_Gas_Tx" SG_ 1085 PwSrcULoOvrTe_B_Actl 1;
BA_ "U_U502_MY15_Gas_Tx" SG_ 1085 PwSrcULoOvrTe_B_Actl 1;
BA_ "U_UP375_MY15_Gas_Tx" SG_ 1085 PwSrcULoOvrTe_B_Actl 1;
BA_ "U_CD43_MY16_Gas_Tx" SG_ 1085 PwSrcULoOvrTe_B_Actl 1;
BA_ "U_CD4_MY14_Gas_Tx" SG_ 1085 PwSrcULoOvrTe_B_Actl 1;
BA_ "U_CD4_MY13_Phev_Rx" SG_ 1085 PwSrcULoFalt_D_Stat 1;
BA_ "U_CD42_MY14_Diesel_Rx" SG_ 1085 PwSrcULoFalt_D_Stat 1;
BA_ "U_CD42_MY14_Gas_Rx" SG_ 1085 PwSrcULoFalt_D_Stat 1;
BA_ "U_P552_MY15_Gas_Rx" SG_ 1085 PwSrcULoFalt_D_Stat 1;
BA_ "U_S550_MY15_Gas_Rx" SG_ 1085 PwSrcULoFalt_D_Stat 1;
BA_ "U_C489_MY14_Gas_Rx" SG_ 1085 PwSrcULoFalt_D_Stat 1;
BA_ "U_U502_MY15_Gas_Rx" SG_ 1085 PwSrcULoFalt_D_Stat 1;
BA_ "U_UP375_MY15_Gas_Rx" SG_ 1085 PwSrcULoFalt_D_Stat 1;
BA_ "U_UP375_MY15_Diesel_Rx" SG_ 1085 PwSrcULoFalt_D_Stat 1;
BA_ "U_CD43_MY16_Gas_Rx" SG_ 1085 PwSrcULoFalt_D_Stat 1;
BA_ "U_CD4_MY14_Diesel_Rx" SG_ 1085 PwSrcULoFalt_D_Stat 1;
BA_ "U_CD4_MY14_Gas_Rx" SG_ 1085 PwSrcULoFalt_D_Stat 1;
BA_ "U_CD4_MY14_Hev_Rx" SG_ 1085 PwSrcULoFalt_D_Stat 1;
BA_ "U_CD4_MY14_Phev_Rx" SG_ 1085 PwSrcULoFalt_D_Stat 1;
BA_ "U_CD4_MY13_Gas_Tx" SG_ 1085 PwSrcULoFalt_D_Stat 1;
BA_ "U_CD42_MY14_Gas_Tx" SG_ 1085 PwSrcULoFalt_D_Stat 1;
BA_ "U_P552_MY15_Gas_Tx" SG_ 1085 PwSrcULoFalt_D_Stat 1;
BA_ "U_S550_MY15_Gas_Tx" SG_ 1085 PwSrcULoFalt_D_Stat 1;
BA_ "U_C489_MY14_Gas_Tx" SG_ 1085 PwSrcULoFalt_D_Stat 1;
BA_ "U_U502_MY15_Gas_Tx" SG_ 1085 PwSrcULoFalt_D_Stat 1;
BA_ "U_UP375_MY15_Gas_Tx" SG_ 1085 PwSrcULoFalt_D_Stat 1;
BA_ "U_CD43_MY16_Gas_Tx" SG_ 1085 PwSrcULoFalt_D_Stat 1;
BA_ "U_CD4_MY14_Gas_Tx" SG_ 1085 PwSrcULoFalt_D_Stat 1;
BA_ "U_CD4_MY13_Diesel_Rx" SG_ 1085 PwSrcULoDcnnt_B_Stat 1;
BA_ "U_CD4_MY13_Gas_Rx" SG_ 1085 PwSrcULoDcnnt_B_Stat 1;
BA_ "U_CD4_MY13_Hev_Rx" SG_ 1085 PwSrcULoDcnnt_B_Stat 1;
BA_ "U_CD4_MY13_Phev_Rx" SG_ 1085 PwSrcULoDcnnt_B_Stat 1;
BA_ "U_CD42_MY14_Diesel_Rx" SG_ 1085 PwSrcULoDcnnt_B_Stat 1;
BA_ "U_CD42_MY14_Gas_Rx" SG_ 1085 PwSrcULoDcnnt_B_Stat 1;
BA_ "U_P552_MY15_Gas_Rx" SG_ 1085 PwSrcULoDcnnt_B_Stat 1;
BA_ "U_S550_MY15_Gas_Rx" SG_ 1085 PwSrcULoDcnnt_B_Stat 1;
BA_ "U_C489_MY14_Gas_Rx" SG_ 1085 PwSrcULoDcnnt_B_Stat 1;
BA_ "U_U502_MY15_Gas_Rx" SG_ 1085 PwSrcULoDcnnt_B_Stat 1;
BA_ "U_UP375_MY15_Gas_Rx" SG_ 1085 PwSrcULoDcnnt_B_Stat 1;
BA_ "U_UP375_MY15_Diesel_Rx" SG_ 1085 PwSrcULoDcnnt_B_Stat 1;
BA_ "U_CD43_MY16_Gas_Rx" SG_ 1085 PwSrcULoDcnnt_B_Stat 1;
BA_ "U_CD4_MY14_Diesel_Rx" SG_ 1085 PwSrcULoDcnnt_B_Stat 1;
BA_ "U_CD4_MY14_Gas_Rx" SG_ 1085 PwSrcULoDcnnt_B_Stat 1;
BA_ "U_CD4_MY14_Hev_Rx" SG_ 1085 PwSrcULoDcnnt_B_Stat 1;
BA_ "U_CD4_MY14_Phev_Rx" SG_ 1085 PwSrcULoDcnnt_B_Stat 1;
BA_ "U_CD4_MY13_Gas_Tx" SG_ 1085 PwSrcULoDcnnt_B_Stat 1;
BA_ "U_CD42_MY14_Gas_Tx" SG_ 1085 PwSrcULoDcnnt_B_Stat 1;
BA_ "U_P552_MY15_Gas_Tx" SG_ 1085 PwSrcULoDcnnt_B_Stat 1;
BA_ "U_S550_MY15_Gas_Tx" SG_ 1085 PwSrcULoDcnnt_B_Stat 1;
BA_ "U_C489_MY14_Gas_Tx" SG_ 1085 PwSrcULoDcnnt_B_Stat 1;
BA_ "U_U502_MY15_Gas_Tx" SG_ 1085 PwSrcULoDcnnt_B_Stat 1;
BA_ "U_UP375_MY15_Gas_Tx" SG_ 1085 PwSrcULoDcnnt_B_Stat 1;
BA_ "U_CD43_MY16_Gas_Tx" SG_ 1085 PwSrcULoDcnnt_B_Stat 1;
BA_ "U_CD4_MY14_Gas_Tx" SG_ 1085 PwSrcULoDcnnt_B_Stat 1;
BA_ "U_CD4_MY13_Phev_Rx" SG_ 1085 PwSrcULo_Pc_Mx 1;
BA_ "U_CD42_MY14_Diesel_Rx" SG_ 1085 PwSrcULo_Pc_Mx 1;
BA_ "U_CD42_MY14_Gas_Rx" SG_ 1085 PwSrcULo_Pc_Mx 1;
BA_ "U_P552_MY15_Gas_Rx" SG_ 1085 PwSrcULo_Pc_Mx 1;
BA_ "U_S550_MY15_Gas_Rx" SG_ 1085 PwSrcULo_Pc_Mx 1;
BA_ "U_C489_MY14_Gas_Rx" SG_ 1085 PwSrcULo_Pc_Mx 1;
BA_ "U_U502_MY15_Gas_Rx" SG_ 1085 PwSrcULo_Pc_Mx 1;
BA_ "U_UP375_MY15_Gas_Rx" SG_ 1085 PwSrcULo_Pc_Mx 1;
BA_ "U_UP375_MY15_Diesel_Rx" SG_ 1085 PwSrcULo_Pc_Mx 1;
BA_ "U_CD43_MY16_Gas_Rx" SG_ 1085 PwSrcULo_Pc_Mx 1;
BA_ "U_CD4_MY14_Diesel_Rx" SG_ 1085 PwSrcULo_Pc_Mx 1;
BA_ "U_CD4_MY14_Gas_Rx" SG_ 1085 PwSrcULo_Pc_Mx 1;
BA_ "U_CD4_MY14_Hev_Rx" SG_ 1085 PwSrcULo_Pc_Mx 1;
BA_ "U_CD4_MY14_Phev_Rx" SG_ 1085 PwSrcULo_Pc_Mx 1;
BA_ "U_CD4_MY13_Gas_Tx" SG_ 1085 PwSrcULo_Pc_Mx 1;
BA_ "U_CD42_MY14_Gas_Tx" SG_ 1085 PwSrcULo_Pc_Mx 1;
BA_ "U_P552_MY15_Gas_Tx" SG_ 1085 PwSrcULo_Pc_Mx 1;
BA_ "U_S550_MY15_Gas_Tx" SG_ 1085 PwSrcULo_Pc_Mx 1;
BA_ "U_C489_MY14_Gas_Tx" SG_ 1085 PwSrcULo_Pc_Mx 1;
BA_ "U_U502_MY15_Gas_Tx" SG_ 1085 PwSrcULo_Pc_Mx 1;
BA_ "U_UP375_MY15_Gas_Tx" SG_ 1085 PwSrcULo_Pc_Mx 1;
BA_ "U_CD43_MY16_Gas_Tx" SG_ 1085 PwSrcULo_Pc_Mx 1;
BA_ "U_CD4_MY14_Gas_Tx" SG_ 1085 PwSrcULo_Pc_Mx 1;
BA_ "ContentDependant" SG_ 1085 PwSrcULoComm_B_Falt 1;
BA_ "U_CD4_MY13_Diesel_Rx" SG_ 1085 PwSrcULoComm_B_Falt 1;
BA_ "U_CD4_MY13_Gas_Rx" SG_ 1085 PwSrcULoComm_B_Falt 1;
BA_ "U_CD4_MY13_Hev_Rx" SG_ 1085 PwSrcULoComm_B_Falt 1;
BA_ "U_CD4_MY13_Phev_Rx" SG_ 1085 PwSrcULoComm_B_Falt 1;
BA_ "U_CD42_MY14_Diesel_Rx" SG_ 1085 PwSrcULoComm_B_Falt 1;
BA_ "U_CD42_MY14_Gas_Rx" SG_ 1085 PwSrcULoComm_B_Falt 1;
BA_ "U_P552_MY15_Gas_Rx" SG_ 1085 PwSrcULoComm_B_Falt 1;
BA_ "U_S550_MY15_Gas_Rx" SG_ 1085 PwSrcULoComm_B_Falt 1;
BA_ "U_C489_MY14_Gas_Rx" SG_ 1085 PwSrcULoComm_B_Falt 1;
BA_ "U_U502_MY15_Gas_Rx" SG_ 1085 PwSrcULoComm_B_Falt 1;
BA_ "U_UP375_MY15_Gas_Rx" SG_ 1085 PwSrcULoComm_B_Falt 1;
BA_ "U_UP375_MY15_Diesel_Rx" SG_ 1085 PwSrcULoComm_B_Falt 1;
BA_ "U_CD43_MY16_Gas_Rx" SG_ 1085 PwSrcULoComm_B_Falt 1;
BA_ "U_CD4_MY14_Diesel_Rx" SG_ 1085 PwSrcULoComm_B_Falt 1;
BA_ "U_CD4_MY14_Gas_Rx" SG_ 1085 PwSrcULoComm_B_Falt 1;
BA_ "U_CD4_MY14_Hev_Rx" SG_ 1085 PwSrcULoComm_B_Falt 1;
BA_ "U_CD4_MY14_Phev_Rx" SG_ 1085 PwSrcULoComm_B_Falt 1;
BA_ "U_CD4_MY13_Gas_Tx" SG_ 1085 PwSrcULoComm_B_Falt 1;
BA_ "U_CD42_MY14_Gas_Tx" SG_ 1085 PwSrcULoComm_B_Falt 1;
BA_ "U_P552_MY15_Gas_Tx" SG_ 1085 PwSrcULoComm_B_Falt 1;
BA_ "U_S550_MY15_Gas_Tx" SG_ 1085 PwSrcULoComm_B_Falt 1;
BA_ "U_C489_MY14_Gas_Tx" SG_ 1085 PwSrcULoComm_B_Falt 1;
BA_ "U_U502_MY15_Gas_Tx" SG_ 1085 PwSrcULoComm_B_Falt 1;
BA_ "U_UP375_MY15_Gas_Tx" SG_ 1085 PwSrcULoComm_B_Falt 1;
BA_ "U_CD43_MY16_Gas_Tx" SG_ 1085 PwSrcULoComm_B_Falt 1;
BA_ "U_CD4_MY14_Gas_Tx" SG_ 1085 PwSrcULoComm_B_Falt 1;
BA_ "U_CD4_MY13_Diesel_Rx" SG_ 1085 PwSrcULo_I_Mx 1;
BA_ "U_CD4_MY13_Gas_Rx" SG_ 1085 PwSrcULo_I_Mx 1;
BA_ "U_CD4_MY13_Hev_Rx" SG_ 1085 PwSrcULo_I_Mx 1;
BA_ "U_CD4_MY13_Phev_Rx" SG_ 1085 PwSrcULo_I_Mx 1;
BA_ "U_CD42_MY14_Diesel_Rx" SG_ 1085 PwSrcULo_I_Mx 1;
BA_ "U_CD42_MY14_Gas_Rx" SG_ 1085 PwSrcULo_I_Mx 1;
BA_ "U_P552_MY15_Gas_Rx" SG_ 1085 PwSrcULo_I_Mx 1;
BA_ "U_S550_MY15_Gas_Rx" SG_ 1085 PwSrcULo_I_Mx 1;
BA_ "U_C489_MY14_Gas_Rx" SG_ 1085 PwSrcULo_I_Mx 1;
BA_ "U_U502_MY15_Gas_Rx" SG_ 1085 PwSrcULo_I_Mx 1;
BA_ "U_UP375_MY15_Gas_Rx" SG_ 1085 PwSrcULo_I_Mx 1;
BA_ "U_UP375_MY15_Diesel_Rx" SG_ 1085 PwSrcULo_I_Mx 1;
BA_ "U_CD43_MY16_Gas_Rx" SG_ 1085 PwSrcULo_I_Mx 1;
BA_ "U_CD4_MY14_Diesel_Rx" SG_ 1085 PwSrcULo_I_Mx 1;
BA_ "U_CD4_MY14_Gas_Rx" SG_ 1085 PwSrcULo_I_Mx 1;
BA_ "U_CD4_MY14_Hev_Rx" SG_ 1085 PwSrcULo_I_Mx 1;
BA_ "U_CD4_MY14_Phev_Rx" SG_ 1085 PwSrcULo_I_Mx 1;
BA_ "U_CD4_MY13_Gas_Tx" SG_ 1085 PwSrcULo_I_Mx 1;
BA_ "U_CD42_MY14_Gas_Tx" SG_ 1085 PwSrcULo_I_Mx 1;
BA_ "U_P552_MY15_Gas_Tx" SG_ 1085 PwSrcULo_I_Mx 1;
BA_ "U_S550_MY15_Gas_Tx" SG_ 1085 PwSrcULo_I_Mx 1;
BA_ "U_C489_MY14_Gas_Tx" SG_ 1085 PwSrcULo_I_Mx 1;
BA_ "U_U502_MY15_Gas_Tx" SG_ 1085 PwSrcULo_I_Mx 1;
BA_ "U_UP375_MY15_Gas_Tx" SG_ 1085 PwSrcULo_I_Mx 1;
BA_ "U_CD43_MY16_Gas_Tx" SG_ 1085 PwSrcULo_I_Mx 1;
BA_ "U_CD4_MY14_Gas_Tx" SG_ 1085 PwSrcULo_I_Mx 1;
BA_ "U_CD4_MY13_Diesel_Rx" SG_ 1085 PwSrcULo_I_Actl 1;
BA_ "U_CD4_MY13_Gas_Rx" SG_ 1085 PwSrcULo_I_Actl 1;
BA_ "U_CD4_MY13_Hev_Rx" SG_ 1085 PwSrcULo_I_Actl 1;
BA_ "U_CD4_MY13_Phev_Rx" SG_ 1085 PwSrcULo_I_Actl 1;
BA_ "U_CD42_MY14_Diesel_Rx" SG_ 1085 PwSrcULo_I_Actl 1;
BA_ "U_CD42_MY14_Gas_Rx" SG_ 1085 PwSrcULo_I_Actl 1;
BA_ "U_P552_MY15_Gas_Rx" SG_ 1085 PwSrcULo_I_Actl 1;
BA_ "U_S550_MY15_Gas_Rx" SG_ 1085 PwSrcULo_I_Actl 1;
BA_ "U_C489_MY14_Gas_Rx" SG_ 1085 PwSrcULo_I_Actl 1;
BA_ "U_U502_MY15_Gas_Rx" SG_ 1085 PwSrcULo_I_Actl 1;
BA_ "U_UP375_MY15_Gas_Rx" SG_ 1085 PwSrcULo_I_Actl 1;
BA_ "U_UP375_MY15_Diesel_Rx" SG_ 1085 PwSrcULo_I_Actl 1;
BA_ "U_CD43_MY16_Gas_Rx" SG_ 1085 PwSrcULo_I_Actl 1;
BA_ "U_CD4_MY14_Diesel_Rx" SG_ 1085 PwSrcULo_I_Actl 1;
BA_ "U_CD4_MY14_Gas_Rx" SG_ 1085 PwSrcULo_I_Actl 1;
BA_ "U_CD4_MY14_Hev_Rx" SG_ 1085 PwSrcULo_I_Actl 1;
BA_ "U_CD4_MY14_Phev_Rx" SG_ 1085 PwSrcULo_I_Actl 1;
BA_ "U_CD4_MY13_Gas_Tx" SG_ 1085 PwSrcULo_I_Actl 1;
BA_ "U_CD42_MY14_Gas_Tx" SG_ 1085 PwSrcULo_I_Actl 1;
BA_ "U_P552_MY15_Gas_Tx" SG_ 1085 PwSrcULo_I_Actl 1;
BA_ "U_S550_MY15_Gas_Tx" SG_ 1085 PwSrcULo_I_Actl 1;
BA_ "U_C489_MY14_Gas_Tx" SG_ 1085 PwSrcULo_I_Actl 1;
BA_ "U_U502_MY15_Gas_Tx" SG_ 1085 PwSrcULo_I_Actl 1;
BA_ "U_UP375_MY15_Gas_Tx" SG_ 1085 PwSrcULo_I_Actl 1;
BA_ "U_CD43_MY16_Gas_Tx" SG_ 1085 PwSrcULo_I_Actl 1;
BA_ "U_CD4_MY14_Gas_Tx" SG_ 1085 PwSrcULo_I_Actl 1;
BA_ "U_P552_MY15_Gas_Rx" SG_ 891 TrlrBrkCtl_B_Falt_UB 1;
BA_ "U_P552_MY15_Gas_Rx" SG_ 891 TrlrBrkActCirct_B_Falt_UB 1;
BA_ "U_P552_MY15_Gas_Rx" SG_ 891 TrlrBrkCtl_B_Falt 1;
BA_ "U_P552_MY15_Gas_Rx" SG_ 891 TrlrBrkActCirct_B_Falt 1;
BA_ "Gateway_ID" SG_ 130 VehVTrlrAid_B_Rq 27629;
BA_ "CrossOver_InfoCAN" SG_ 130 VehVTrlrAid_B_Rq 1;
BA_ "Gateway_ID" SG_ 130 TrlrHitchLamp_D_Rqst 27642;
BA_ "U_UP375_MY15_Diesel_Rx" SG_ 130 TrlrHitchLamp_D_Rqst 1;
BA_ "U_UP375_MY15_Gas_Rx" SG_ 130 TrlrHitchLamp_D_Rqst 1;
BA_ "CrossOver_LIN" SG_ 130 TrlrHitchLamp_D_Rqst 1;
BA_ "CrossOver_InfoCAN" SG_ 130 TrlrHitchLamp_D_Rqst 1;
BA_ "GenSigStartValue" SG_ 130 Veh_V_RqMxTrlrAid 255;
BA_ "U_P552_MY15_Gas_Rx" SG_ 130 Veh_V_RqMxTrlrAid 1;
BA_ "GenSigStartValue" SG_ 130 DrvSte_Tq_Actl 128;
BA_ "GenSigStartValue" SG_ 130 SteMdule_U_Meas 255;
BA_ "U_CD4_MY13_Diesel_Rx" SG_ 130 SteMdule_U_Meas 1;
BA_ "U_CD4_MY13_Gas_Rx" SG_ 130 SteMdule_U_Meas 1;
BA_ "U_CD4_MY13_Hev_Rx" SG_ 130 SteMdule_U_Meas 1;
BA_ "U_CD4_MY13_Phev_Rx" SG_ 130 SteMdule_U_Meas 1;
BA_ "U_CD42_MY14_Diesel_Rx" SG_ 130 SteMdule_U_Meas 1;
BA_ "U_CD42_MY14_Gas_Rx" SG_ 130 SteMdule_U_Meas 1;
BA_ "U_P552_MY15_Gas_Rx" SG_ 130 SteMdule_U_Meas 1;
BA_ "U_S550_MY15_Gas_Rx" SG_ 130 SteMdule_U_Meas 1;
BA_ "U_C489_MY14_Gas_Rx" SG_ 130 SteMdule_U_Meas 1;
BA_ "U_U502_MY15_Gas_Rx" SG_ 130 SteMdule_U_Meas 1;
BA_ "U_UP375_MY15_Gas_Rx" SG_ 130 SteMdule_U_Meas 1;
BA_ "U_UP375_MY15_Diesel_Rx" SG_ 130 SteMdule_U_Meas 1;
BA_ "U_CD43_MY16_Gas_Rx" SG_ 130 SteMdule_U_Meas 1;
BA_ "U_CD4_MY14_Diesel_Rx" SG_ 130 SteMdule_U_Meas 1;
BA_ "U_CD4_MY14_Gas_Rx" SG_ 130 SteMdule_U_Meas 1;
BA_ "U_CD4_MY14_Hev_Rx" SG_ 130 SteMdule_U_Meas 1;
BA_ "U_CD4_MY14_Phev_Rx" SG_ 130 SteMdule_U_Meas 1;
BA_ "GenSigStartValue" SG_ 130 SteMdule_I_Est 4095;
BA_ "U_CD4_MY13_Diesel_Rx" SG_ 130 SteMdule_I_Est 1;
BA_ "U_CD4_MY13_Gas_Rx" SG_ 130 SteMdule_I_Est 1;
BA_ "U_CD4_MY13_Hev_Rx" SG_ 130 SteMdule_I_Est 1;
BA_ "U_CD4_MY13_Phev_Rx" SG_ 130 SteMdule_I_Est 1;
BA_ "U_CD42_MY14_Diesel_Rx" SG_ 130 SteMdule_I_Est 1;
BA_ "U_CD42_MY14_Gas_Rx" SG_ 130 SteMdule_I_Est 1;
BA_ "U_P552_MY15_Gas_Rx" SG_ 130 SteMdule_I_Est 1;
BA_ "U_S550_MY15_Gas_Rx" SG_ 130 SteMdule_I_Est 1;
BA_ "U_C489_MY14_Gas_Rx" SG_ 130 SteMdule_I_Est 1;
BA_ "U_U502_MY15_Gas_Rx" SG_ 130 SteMdule_I_Est 1;
BA_ "U_UP375_MY15_Gas_Rx" SG_ 130 SteMdule_I_Est 1;
BA_ "U_UP375_MY15_Diesel_Rx" SG_ 130 SteMdule_I_Est 1;
BA_ "U_CD43_MY16_Gas_Rx" SG_ 130 SteMdule_I_Est 1;
BA_ "U_CD4_MY14_Diesel_Rx" SG_ 130 SteMdule_I_Est 1;
BA_ "U_CD4_MY14_Gas_Rx" SG_ 130 SteMdule_I_Est 1;
BA_ "U_CD4_MY14_Hev_Rx" SG_ 130 SteMdule_I_Est 1;
BA_ "U_CD4_MY14_Phev_Rx" SG_ 130 SteMdule_I_Est 1;
BA_ "CrossOver_InfoCAN" SG_ 130 EPAS_Failure 1;
BA_ "U_CD4_MY13_Diesel_Rx" SG_ 130 EPAS_Failure 1;
BA_ "U_CD4_MY13_Gas_Rx" SG_ 130 EPAS_Failure 1;
BA_ "U_CD4_MY13_Hev_Rx" SG_ 130 EPAS_Failure 1;
BA_ "U_CD4_MY13_Phev_Rx" SG_ 130 EPAS_Failure 1;
BA_ "U_CD42_MY14_Diesel_Rx" SG_ 130 EPAS_Failure 1;
BA_ "U_CD42_MY14_Gas_Rx" SG_ 130 EPAS_Failure 1;
BA_ "U_P552_MY15_Gas_Rx" SG_ 130 EPAS_Failure 1;
BA_ "U_C489_MY14_Gas_Rx" SG_ 130 EPAS_Failure 1;
BA_ "U_U502_MY15_Gas_Rx" SG_ 130 EPAS_Failure 1;
BA_ "U_UP375_MY15_Gas_Rx" SG_ 130 EPAS_Failure 1;
BA_ "U_UP375_MY15_Diesel_Rx" SG_ 130 EPAS_Failure 1;
BA_ "U_CD43_MY16_Gas_Rx" SG_ 130 EPAS_Failure 1;
BA_ "U_CD4_MY14_Diesel_Rx" SG_ 130 EPAS_Failure 1;
BA_ "U_CD4_MY14_Gas_Rx" SG_ 130 EPAS_Failure 1;
BA_ "U_CD4_MY14_Hev_Rx" SG_ 130 EPAS_Failure 1;
BA_ "U_CD4_MY14_Phev_Rx" SG_ 130 EPAS_Failure 1;
BA_ "GenSigStartValue" SG_ 130 SteeringColumnTorque 254;
BA_ "U_CD4_MY13_Diesel_Rx" SG_ 130 SteeringColumnTorque 1;
BA_ "U_CD4_MY13_Gas_Rx" SG_ 130 SteeringColumnTorque 1;
BA_ "U_CD4_MY13_Hev_Rx" SG_ 130 SteeringColumnTorque 1;
BA_ "U_CD4_MY13_Phev_Rx" SG_ 130 SteeringColumnTorque 1;
BA_ "U_CD42_MY14_Diesel_Rx" SG_ 130 SteeringColumnTorque 1;
BA_ "U_CD42_MY14_Gas_Rx" SG_ 130 SteeringColumnTorque 1;
BA_ "U_P552_MY15_Gas_Rx" SG_ 130 SteeringColumnTorque 1;
BA_ "U_C489_MY14_Gas_Rx" SG_ 130 SteeringColumnTorque 1;
BA_ "U_U502_MY15_Gas_Rx" SG_ 130 SteeringColumnTorque 1;
BA_ "U_UP375_MY15_Gas_Rx" SG_ 130 SteeringColumnTorque 1;
BA_ "U_UP375_MY15_Diesel_Rx" SG_ 130 SteeringColumnTorque 1;
BA_ "U_CD43_MY16_Gas_Rx" SG_ 130 SteeringColumnTorque 1;
BA_ "U_CD4_MY14_Diesel_Rx" SG_ 130 SteeringColumnTorque 1;
BA_ "U_CD4_MY14_Gas_Rx" SG_ 130 SteeringColumnTorque 1;
BA_ "U_CD4_MY14_Hev_Rx" SG_ 130 SteeringColumnTorque 1;
BA_ "U_CD4_MY14_Phev_Rx" SG_ 130 SteeringColumnTorque 1;
BA_ "U_CD4_MY13_Diesel_Rx" SG_ 130 SAPPAngleControlStat6 1;
BA_ "U_CD4_MY13_Gas_Rx" SG_ 130 SAPPAngleControlStat6 1;
BA_ "U_CD4_MY13_Hev_Rx" SG_ 130 SAPPAngleControlStat6 1;
BA_ "U_CD4_MY13_Phev_Rx" SG_ 130 SAPPAngleControlStat6 1;
BA_ "U_CD42_MY14_Diesel_Rx" SG_ 130 SAPPAngleControlStat6 1;
BA_ "U_CD42_MY14_Gas_Rx" SG_ 130 SAPPAngleControlStat6 1;
BA_ "U_P552_MY15_Gas_Rx" SG_ 130 SAPPAngleControlStat6 1;
BA_ "U_C489_MY14_Gas_Rx" SG_ 130 SAPPAngleControlStat6 1;
BA_ "U_U502_MY15_Gas_Rx" SG_ 130 SAPPAngleControlStat6 1;
BA_ "U_UP375_MY15_Gas_Rx" SG_ 130 SAPPAngleControlStat6 1;
BA_ "U_UP375_MY15_Diesel_Rx" SG_ 130 SAPPAngleControlStat6 1;
BA_ "U_CD43_MY16_Gas_Rx" SG_ 130 SAPPAngleControlStat6 1;
BA_ "U_CD4_MY14_Diesel_Rx" SG_ 130 SAPPAngleControlStat6 1;
BA_ "U_CD4_MY14_Gas_Rx" SG_ 130 SAPPAngleControlStat6 1;
BA_ "U_CD4_MY14_Hev_Rx" SG_ 130 SAPPAngleControlStat6 1;
BA_ "U_CD4_MY14_Phev_Rx" SG_ 130 SAPPAngleControlStat6 1;
BA_ "U_CD4_MY13_Diesel_Rx" SG_ 130 SAPPAngleControlStat5 1;
BA_ "U_CD4_MY13_Gas_Rx" SG_ 130 SAPPAngleControlStat5 1;
BA_ "U_CD4_MY13_Hev_Rx" SG_ 130 SAPPAngleControlStat5 1;
BA_ "U_CD4_MY13_Phev_Rx" SG_ 130 SAPPAngleControlStat5 1;
BA_ "U_CD42_MY14_Diesel_Rx" SG_ 130 SAPPAngleControlStat5 1;
BA_ "U_CD42_MY14_Gas_Rx" SG_ 130 SAPPAngleControlStat5 1;
BA_ "U_P552_MY15_Gas_Rx" SG_ 130 SAPPAngleControlStat5 1;
BA_ "U_C489_MY14_Gas_Rx" SG_ 130 SAPPAngleControlStat5 1;
BA_ "U_U502_MY15_Gas_Rx" SG_ 130 SAPPAngleControlStat5 1;
BA_ "U_UP375_MY15_Gas_Rx" SG_ 130 SAPPAngleControlStat5 1;
BA_ "U_UP375_MY15_Diesel_Rx" SG_ 130 SAPPAngleControlStat5 1;
BA_ "U_CD43_MY16_Gas_Rx" SG_ 130 SAPPAngleControlStat5 1;
BA_ "U_CD4_MY14_Diesel_Rx" SG_ 130 SAPPAngleControlStat5 1;
BA_ "U_CD4_MY14_Gas_Rx" SG_ 130 SAPPAngleControlStat5 1;
BA_ "U_CD4_MY14_Hev_Rx" SG_ 130 SAPPAngleControlStat5 1;
BA_ "U_CD4_MY14_Phev_Rx" SG_ 130 SAPPAngleControlStat5 1;
BA_ "U_CD4_MY13_Diesel_Rx" SG_ 130 SAPPAngleControlStat4 1;
BA_ "U_CD4_MY13_Gas_Rx" SG_ 130 SAPPAngleControlStat4 1;
BA_ "U_CD4_MY13_Hev_Rx" SG_ 130 SAPPAngleControlStat4 1;
BA_ "U_CD4_MY13_Phev_Rx" SG_ 130 SAPPAngleControlStat4 1;
BA_ "U_CD42_MY14_Diesel_Rx" SG_ 130 SAPPAngleControlStat4 1;
BA_ "U_CD42_MY14_Gas_Rx" SG_ 130 SAPPAngleControlStat4 1;
BA_ "U_P552_MY15_Gas_Rx" SG_ 130 SAPPAngleControlStat4 1;
BA_ "U_C489_MY14_Gas_Rx" SG_ 130 SAPPAngleControlStat4 1;
BA_ "U_U502_MY15_Gas_Rx" SG_ 130 SAPPAngleControlStat4 1;
BA_ "U_UP375_MY15_Gas_Rx" SG_ 130 SAPPAngleControlStat4 1;
BA_ "U_UP375_MY15_Diesel_Rx" SG_ 130 SAPPAngleControlStat4 1;
BA_ "U_CD43_MY16_Gas_Rx" SG_ 130 SAPPAngleControlStat4 1;
BA_ "U_CD4_MY14_Diesel_Rx" SG_ 130 SAPPAngleControlStat4 1;
BA_ "U_CD4_MY14_Gas_Rx" SG_ 130 SAPPAngleControlStat4 1;
BA_ "U_CD4_MY14_Hev_Rx" SG_ 130 SAPPAngleControlStat4 1;
BA_ "U_CD4_MY14_Phev_Rx" SG_ 130 SAPPAngleControlStat4 1;
BA_ "U_CD4_MY13_Diesel_Rx" SG_ 130 SAPPAngleControlStat3 1;
BA_ "U_CD4_MY13_Gas_Rx" SG_ 130 SAPPAngleControlStat3 1;
BA_ "U_CD4_MY13_Hev_Rx" SG_ 130 SAPPAngleControlStat3 1;
BA_ "U_CD4_MY13_Phev_Rx" SG_ 130 SAPPAngleControlStat3 1;
BA_ "U_CD42_MY14_Diesel_Rx" SG_ 130 SAPPAngleControlStat3 1;
BA_ "U_CD42_MY14_Gas_Rx" SG_ 130 SAPPAngleControlStat3 1;
BA_ "U_P552_MY15_Gas_Rx" SG_ 130 SAPPAngleControlStat3 1;
BA_ "U_C489_MY14_Gas_Rx" SG_ 130 SAPPAngleControlStat3 1;
BA_ "U_U502_MY15_Gas_Rx" SG_ 130 SAPPAngleControlStat3 1;
BA_ "U_UP375_MY15_Gas_Rx" SG_ 130 SAPPAngleControlStat3 1;
BA_ "U_UP375_MY15_Diesel_Rx" SG_ 130 SAPPAngleControlStat3 1;
BA_ "U_CD43_MY16_Gas_Rx" SG_ 130 SAPPAngleControlStat3 1;
BA_ "U_CD4_MY14_Diesel_Rx" SG_ 130 SAPPAngleControlStat3 1;
BA_ "U_CD4_MY14_Gas_Rx" SG_ 130 SAPPAngleControlStat3 1;
BA_ "U_CD4_MY14_Hev_Rx" SG_ 130 SAPPAngleControlStat3 1;
BA_ "U_CD4_MY14_Phev_Rx" SG_ 130 SAPPAngleControlStat3 1;
BA_ "U_CD4_MY13_Diesel_Rx" SG_ 130 SAPPAngleControlStat2 1;
BA_ "U_CD4_MY13_Gas_Rx" SG_ 130 SAPPAngleControlStat2 1;
BA_ "U_CD4_MY13_Hev_Rx" SG_ 130 SAPPAngleControlStat2 1;
BA_ "U_CD4_MY13_Phev_Rx" SG_ 130 SAPPAngleControlStat2 1;
BA_ "U_CD42_MY14_Diesel_Rx" SG_ 130 SAPPAngleControlStat2 1;
BA_ "U_CD42_MY14_Gas_Rx" SG_ 130 SAPPAngleControlStat2 1;
BA_ "U_P552_MY15_Gas_Rx" SG_ 130 SAPPAngleControlStat2 1;
BA_ "U_C489_MY14_Gas_Rx" SG_ 130 SAPPAngleControlStat2 1;
BA_ "U_U502_MY15_Gas_Rx" SG_ 130 SAPPAngleControlStat2 1;
BA_ "U_UP375_MY15_Gas_Rx" SG_ 130 SAPPAngleControlStat2 1;
BA_ "U_UP375_MY15_Diesel_Rx" SG_ 130 SAPPAngleControlStat2 1;
BA_ "U_CD43_MY16_Gas_Rx" SG_ 130 SAPPAngleControlStat2 1;
BA_ "U_CD4_MY14_Diesel_Rx" SG_ 130 SAPPAngleControlStat2 1;
BA_ "U_CD4_MY14_Gas_Rx" SG_ 130 SAPPAngleControlStat2 1;
BA_ "U_CD4_MY14_Hev_Rx" SG_ 130 SAPPAngleControlStat2 1;
BA_ "U_CD4_MY14_Phev_Rx" SG_ 130 SAPPAngleControlStat2 1;
BA_ "U_CD4_MY13_Diesel_Rx" SG_ 130 SAPPAngleControlStat1 1;
BA_ "U_CD4_MY13_Gas_Rx" SG_ 130 SAPPAngleControlStat1 1;
BA_ "U_CD4_MY13_Hev_Rx" SG_ 130 SAPPAngleControlStat1 1;
BA_ "U_CD4_MY13_Phev_Rx" SG_ 130 SAPPAngleControlStat1 1;
BA_ "U_CD42_MY14_Diesel_Rx" SG_ 130 SAPPAngleControlStat1 1;
BA_ "U_CD42_MY14_Gas_Rx" SG_ 130 SAPPAngleControlStat1 1;
BA_ "U_P552_MY15_Gas_Rx" SG_ 130 SAPPAngleControlStat1 1;
BA_ "U_C489_MY14_Gas_Rx" SG_ 130 SAPPAngleControlStat1 1;
BA_ "U_U502_MY15_Gas_Rx" SG_ 130 SAPPAngleControlStat1 1;
BA_ "U_UP375_MY15_Gas_Rx" SG_ 130 SAPPAngleControlStat1 1;
BA_ "U_UP375_MY15_Diesel_Rx" SG_ 130 SAPPAngleControlStat1 1;
BA_ "U_CD43_MY16_Gas_Rx" SG_ 130 SAPPAngleControlStat1 1;
BA_ "U_CD4_MY14_Diesel_Rx" SG_ 130 SAPPAngleControlStat1 1;
BA_ "U_CD4_MY14_Gas_Rx" SG_ 130 SAPPAngleControlStat1 1;
BA_ "U_CD4_MY14_Hev_Rx" SG_ 130 SAPPAngleControlStat1 1;
BA_ "U_CD4_MY14_Phev_Rx" SG_ 130 SAPPAngleControlStat1 1;
BA_ "U_CD4_MY13_Diesel_Rx" SG_ 75 VedsPasKneeBag_D_Ltchd 1;
BA_ "U_CD4_MY13_Gas_Rx" SG_ 75 VedsPasKneeBag_D_Ltchd 1;
BA_ "U_CD4_MY13_Hev_Rx" SG_ 75 VedsPasKneeBag_D_Ltchd 1;
BA_ "U_CD4_MY13_Phev_Rx" SG_ 75 VedsPasKneeBag_D_Ltchd 1;
BA_ "U_CD42_MY14_Diesel_Rx" SG_ 75 VedsPasKneeBag_D_Ltchd 1;
BA_ "U_CD42_MY14_Gas_Rx" SG_ 75 VedsPasKneeBag_D_Ltchd 1;
BA_ "U_P552_MY15_Gas_Rx" SG_ 75 VedsPasKneeBag_D_Ltchd 1;
BA_ "U_S550_MY15_Gas_Rx" SG_ 75 VedsPasKneeBag_D_Ltchd 1;
BA_ "U_C489_MY14_Gas_Rx" SG_ 75 VedsPasKneeBag_D_Ltchd 1;
BA_ "U_U502_MY15_Gas_Rx" SG_ 75 VedsPasKneeBag_D_Ltchd 1;
BA_ "U_CD43_MY16_Gas_Rx" SG_ 75 VedsPasKneeBag_D_Ltchd 1;
BA_ "U_CD4_MY14_Diesel_Rx" SG_ 75 VedsPasKneeBag_D_Ltchd 1;
BA_ "U_CD4_MY14_Gas_Rx" SG_ 75 VedsPasKneeBag_D_Ltchd 1;
BA_ "U_CD4_MY14_Hev_Rx" SG_ 75 VedsPasKneeBag_D_Ltchd 1;
BA_ "U_CD4_MY14_Phev_Rx" SG_ 75 VedsPasKneeBag_D_Ltchd 1;
BA_ "U_CD4_MY13_Diesel_Tx" SG_ 75 VedsPasKneeBag_D_Ltchd 1;
BA_ "U_CD4_MY13_Gas_Tx" SG_ 75 VedsPasKneeBag_D_Ltchd 1;
BA_ "U_CD4_MY13_Hev_Tx" SG_ 75 VedsPasKneeBag_D_Ltchd 1;
BA_ "U_CD4_MY13_Diesel_Rx" SG_ 75 VedsRw1mBckl_D_Ltchd 1;
BA_ "U_CD4_MY13_Gas_Rx" SG_ 75 VedsRw1mBckl_D_Ltchd 1;
BA_ "U_CD4_MY13_Hev_Rx" SG_ 75 VedsRw1mBckl_D_Ltchd 1;
BA_ "U_CD4_MY13_Phev_Rx" SG_ 75 VedsRw1mBckl_D_Ltchd 1;
BA_ "U_CD42_MY14_Diesel_Rx" SG_ 75 VedsRw1mBckl_D_Ltchd 1;
BA_ "U_CD42_MY14_Gas_Rx" SG_ 75 VedsRw1mBckl_D_Ltchd 1;
BA_ "U_P552_MY15_Gas_Rx" SG_ 75 VedsRw1mBckl_D_Ltchd 1;
BA_ "U_S550_MY15_Gas_Rx" SG_ 75 VedsRw1mBckl_D_Ltchd 1;
BA_ "U_C489_MY14_Gas_Rx" SG_ 75 VedsRw1mBckl_D_Ltchd 1;
BA_ "U_U502_MY15_Gas_Rx" SG_ 75 VedsRw1mBckl_D_Ltchd 1;
BA_ "U_CD43_MY16_Gas_Rx" SG_ 75 VedsRw1mBckl_D_Ltchd 1;
BA_ "U_CD4_MY14_Diesel_Rx" SG_ 75 VedsRw1mBckl_D_Ltchd 1;
BA_ "U_CD4_MY14_Gas_Rx" SG_ 75 VedsRw1mBckl_D_Ltchd 1;
BA_ "U_CD4_MY14_Hev_Rx" SG_ 75 VedsRw1mBckl_D_Ltchd 1;
BA_ "U_CD4_MY14_Phev_Rx" SG_ 75 VedsRw1mBckl_D_Ltchd 1;
BA_ "U_CD4_MY13_Diesel_Tx" SG_ 75 VedsRw1mBckl_D_Ltchd 1;
BA_ "U_CD4_MY13_Gas_Tx" SG_ 75 VedsRw1mBckl_D_Ltchd 1;
BA_ "U_CD4_MY13_Hev_Tx" SG_ 75 VedsRw1mBckl_D_Ltchd 1;
BA_ "U_CD4_MY13_Diesel_Rx" SG_ 75 VedsRw1mBelt_D_Ltchd 1;
BA_ "U_CD4_MY13_Gas_Rx" SG_ 75 VedsRw1mBelt_D_Ltchd 1;
BA_ "U_CD4_MY13_Hev_Rx" SG_ 75 VedsRw1mBelt_D_Ltchd 1;
BA_ "U_CD4_MY13_Phev_Rx" SG_ 75 VedsRw1mBelt_D_Ltchd 1;
BA_ "U_CD42_MY14_Diesel_Rx" SG_ 75 VedsRw1mBelt_D_Ltchd 1;
BA_ "U_CD42_MY14_Gas_Rx" SG_ 75 VedsRw1mBelt_D_Ltchd 1;
BA_ "U_P552_MY15_Gas_Rx" SG_ 75 VedsRw1mBelt_D_Ltchd 1;
BA_ "U_S550_MY15_Gas_Rx" SG_ 75 VedsRw1mBelt_D_Ltchd 1;
BA_ "U_C489_MY14_Gas_Rx" SG_ 75 VedsRw1mBelt_D_Ltchd 1;
BA_ "U_U502_MY15_Gas_Rx" SG_ 75 VedsRw1mBelt_D_Ltchd 1;
BA_ "U_CD43_MY16_Gas_Rx" SG_ 75 VedsRw1mBelt_D_Ltchd 1;
BA_ "U_CD4_MY14_Diesel_Rx" SG_ 75 VedsRw1mBelt_D_Ltchd 1;
BA_ "U_CD4_MY14_Gas_Rx" SG_ 75 VedsRw1mBelt_D_Ltchd 1;
BA_ "U_CD4_MY14_Hev_Rx" SG_ 75 VedsRw1mBelt_D_Ltchd 1;
BA_ "U_CD4_MY14_Phev_Rx" SG_ 75 VedsRw1mBelt_D_Ltchd 1;
BA_ "U_CD4_MY13_Diesel_Tx" SG_ 75 VedsRw1mBelt_D_Ltchd 1;
BA_ "U_CD4_MY13_Gas_Tx" SG_ 75 VedsRw1mBelt_D_Ltchd 1;
BA_ "U_CD4_MY13_Hev_Tx" SG_ 75 VedsRw1mBelt_D_Ltchd 1;
BA_ "U_CD4_MY13_Diesel_Rx" SG_ 75 VedsRw2pRib_D_Ltchd 1;
BA_ "U_CD4_MY13_Gas_Rx" SG_ 75 VedsRw2pRib_D_Ltchd 1;
BA_ "U_CD4_MY13_Hev_Rx" SG_ 75 VedsRw2pRib_D_Ltchd 1;
BA_ "U_CD4_MY13_Phev_Rx" SG_ 75 VedsRw2pRib_D_Ltchd 1;
BA_ "U_CD42_MY14_Diesel_Rx" SG_ 75 VedsRw2pRib_D_Ltchd 1;
BA_ "U_CD42_MY14_Gas_Rx" SG_ 75 VedsRw2pRib_D_Ltchd 1;
BA_ "U_P552_MY15_Gas_Rx" SG_ 75 VedsRw2pRib_D_Ltchd 1;
BA_ "U_S550_MY15_Gas_Rx" SG_ 75 VedsRw2pRib_D_Ltchd 1;
BA_ "U_C489_MY14_Gas_Rx" SG_ 75 VedsRw2pRib_D_Ltchd 1;
BA_ "U_U502_MY15_Gas_Rx" SG_ 75 VedsRw2pRib_D_Ltchd 1;
BA_ "U_CD43_MY16_Gas_Rx" SG_ 75 VedsRw2pRib_D_Ltchd 1;
BA_ "U_CD4_MY14_Diesel_Rx" SG_ 75 VedsRw2pRib_D_Ltchd 1;
BA_ "U_CD4_MY14_Gas_Rx" SG_ 75 VedsRw2pRib_D_Ltchd 1;
BA_ "U_CD4_MY14_Hev_Rx" SG_ 75 VedsRw2pRib_D_Ltchd 1;
BA_ "U_CD4_MY14_Phev_Rx" SG_ 75 VedsRw2pRib_D_Ltchd 1;
BA_ "U_CD4_MY13_Diesel_Tx" SG_ 75 VedsRw2pRib_D_Ltchd 1;
BA_ "U_CD4_MY13_Gas_Tx" SG_ 75 VedsRw2pRib_D_Ltchd 1;
BA_ "U_CD4_MY13_Hev_Tx" SG_ 75 VedsRw2pRib_D_Ltchd 1;
BA_ "U_CD4_MY13_Diesel_Rx" SG_ 75 VedsRw2dRib_D_Ltchd 1;
BA_ "U_CD4_MY13_Gas_Rx" SG_ 75 VedsRw2dRib_D_Ltchd 1;
BA_ "U_CD4_MY13_Hev_Rx" SG_ 75 VedsRw2dRib_D_Ltchd 1;
BA_ "U_CD4_MY13_Phev_Rx" SG_ 75 VedsRw2dRib_D_Ltchd 1;
BA_ "U_CD42_MY14_Diesel_Rx" SG_ 75 VedsRw2dRib_D_Ltchd 1;
BA_ "U_CD42_MY14_Gas_Rx" SG_ 75 VedsRw2dRib_D_Ltchd 1;
BA_ "U_P552_MY15_Gas_Rx" SG_ 75 VedsRw2dRib_D_Ltchd 1;
BA_ "U_S550_MY15_Gas_Rx" SG_ 75 VedsRw2dRib_D_Ltchd 1;
BA_ "U_C489_MY14_Gas_Rx" SG_ 75 VedsRw2dRib_D_Ltchd 1;
BA_ "U_U502_MY15_Gas_Rx" SG_ 75 VedsRw2dRib_D_Ltchd 1;
BA_ "U_CD43_MY16_Gas_Rx" SG_ 75 VedsRw2dRib_D_Ltchd 1;
BA_ "U_CD4_MY14_Diesel_Rx" SG_ 75 VedsRw2dRib_D_Ltchd 1;
BA_ "U_CD4_MY14_Gas_Rx" SG_ 75 VedsRw2dRib_D_Ltchd 1;
BA_ "U_CD4_MY14_Hev_Rx" SG_ 75 VedsRw2dRib_D_Ltchd 1;
BA_ "U_CD4_MY14_Phev_Rx" SG_ 75 VedsRw2dRib_D_Ltchd 1;
BA_ "U_CD4_MY13_Diesel_Tx" SG_ 75 VedsRw2dRib_D_Ltchd 1;
BA_ "U_CD4_MY13_Gas_Tx" SG_ 75 VedsRw2dRib_D_Ltchd 1;
BA_ "U_CD4_MY13_Hev_Tx" SG_ 75 VedsRw2dRib_D_Ltchd 1;
BA_ "U_CD4_MY13_Diesel_Rx" SG_ 75 VedsRw3pBckl_D_Ltchd 1;
BA_ "U_CD4_MY13_Gas_Rx" SG_ 75 VedsRw3pBckl_D_Ltchd 1;
BA_ "U_CD4_MY13_Hev_Rx" SG_ 75 VedsRw3pBckl_D_Ltchd 1;
BA_ "U_CD4_MY13_Phev_Rx" SG_ 75 VedsRw3pBckl_D_Ltchd 1;
BA_ "U_CD42_MY14_Diesel_Rx" SG_ 75 VedsRw3pBckl_D_Ltchd 1;
BA_ "U_CD42_MY14_Gas_Rx" SG_ 75 VedsRw3pBckl_D_Ltchd 1;
BA_ "U_P552_MY15_Gas_Rx" SG_ 75 VedsRw3pBckl_D_Ltchd 1;
BA_ "U_S550_MY15_Gas_Rx" SG_ 75 VedsRw3pBckl_D_Ltchd 1;
BA_ "U_C489_MY14_Gas_Rx" SG_ 75 VedsRw3pBckl_D_Ltchd 1;
BA_ "U_U502_MY15_Gas_Rx" SG_ 75 VedsRw3pBckl_D_Ltchd 1;
BA_ "U_CD43_MY16_Gas_Rx" SG_ 75 VedsRw3pBckl_D_Ltchd 1;
BA_ "U_CD4_MY14_Diesel_Rx" SG_ 75 VedsRw3pBckl_D_Ltchd 1;
BA_ "U_CD4_MY14_Gas_Rx" SG_ 75 VedsRw3pBckl_D_Ltchd 1;
BA_ "U_CD4_MY14_Hev_Rx" SG_ 75 VedsRw3pBckl_D_Ltchd 1;
BA_ "U_CD4_MY14_Phev_Rx" SG_ 75 VedsRw3pBckl_D_Ltchd 1;
BA_ "U_CD4_MY13_Diesel_Tx" SG_ 75 VedsRw3pBckl_D_Ltchd 1;
BA_ "U_CD4_MY13_Gas_Tx" SG_ 75 VedsRw3pBckl_D_Ltchd 1;
BA_ "U_CD4_MY13_Hev_Tx" SG_ 75 VedsRw3pBckl_D_Ltchd 1;
BA_ "U_CD4_MY13_Diesel_Rx" SG_ 75 VedsRw3mBckl_D_Ltchd 1;
BA_ "U_CD4_MY13_Gas_Rx" SG_ 75 VedsRw3mBckl_D_Ltchd 1;
BA_ "U_CD4_MY13_Hev_Rx" SG_ 75 VedsRw3mBckl_D_Ltchd 1;
BA_ "U_CD4_MY13_Phev_Rx" SG_ 75 VedsRw3mBckl_D_Ltchd 1;
BA_ "U_CD42_MY14_Diesel_Rx" SG_ 75 VedsRw3mBckl_D_Ltchd 1;
BA_ "U_CD42_MY14_Gas_Rx" SG_ 75 VedsRw3mBckl_D_Ltchd 1;
BA_ "U_P552_MY15_Gas_Rx" SG_ 75 VedsRw3mBckl_D_Ltchd 1;
BA_ "U_S550_MY15_Gas_Rx" SG_ 75 VedsRw3mBckl_D_Ltchd 1;
BA_ "U_C489_MY14_Gas_Rx" SG_ 75 VedsRw3mBckl_D_Ltchd 1;
BA_ "U_U502_MY15_Gas_Rx" SG_ 75 VedsRw3mBckl_D_Ltchd 1;
BA_ "U_CD43_MY16_Gas_Rx" SG_ 75 VedsRw3mBckl_D_Ltchd 1;
BA_ "U_CD4_MY14_Diesel_Rx" SG_ 75 VedsRw3mBckl_D_Ltchd 1;
BA_ "U_CD4_MY14_Gas_Rx" SG_ 75 VedsRw3mBckl_D_Ltchd 1;
BA_ "U_CD4_MY14_Hev_Rx" SG_ 75 VedsRw3mBckl_D_Ltchd 1;
BA_ "U_CD4_MY14_Phev_Rx" SG_ 75 VedsRw3mBckl_D_Ltchd 1;
BA_ "U_CD4_MY13_Diesel_Tx" SG_ 75 VedsRw3mBckl_D_Ltchd 1;
BA_ "U_CD4_MY13_Gas_Tx" SG_ 75 VedsRw3mBckl_D_Ltchd 1;
BA_ "U_CD4_MY13_Hev_Tx" SG_ 75 VedsRw3mBckl_D_Ltchd 1;
BA_ "U_CD4_MY13_Diesel_Rx" SG_ 75 VedsRw3dBckl_D_Ltchd 1;
BA_ "U_CD4_MY13_Gas_Rx" SG_ 75 VedsRw3dBckl_D_Ltchd 1;
BA_ "U_CD4_MY13_Hev_Rx" SG_ 75 VedsRw3dBckl_D_Ltchd 1;
BA_ "U_CD4_MY13_Phev_Rx" SG_ 75 VedsRw3dBckl_D_Ltchd 1;
BA_ "U_CD42_MY14_Diesel_Rx" SG_ 75 VedsRw3dBckl_D_Ltchd 1;
BA_ "U_CD42_MY14_Gas_Rx" SG_ 75 VedsRw3dBckl_D_Ltchd 1;
BA_ "U_P552_MY15_Gas_Rx" SG_ 75 VedsRw3dBckl_D_Ltchd 1;
BA_ "U_S550_MY15_Gas_Rx" SG_ 75 VedsRw3dBckl_D_Ltchd 1;
BA_ "U_C489_MY14_Gas_Rx" SG_ 75 VedsRw3dBckl_D_Ltchd 1;
BA_ "U_U502_MY15_Gas_Rx" SG_ 75 VedsRw3dBckl_D_Ltchd 1;
BA_ "U_CD43_MY16_Gas_Rx" SG_ 75 VedsRw3dBckl_D_Ltchd 1;
BA_ "U_CD4_MY14_Diesel_Rx" SG_ 75 VedsRw3dBckl_D_Ltchd 1;
BA_ "U_CD4_MY14_Gas_Rx" SG_ 75 VedsRw3dBckl_D_Ltchd 1;
BA_ "U_CD4_MY14_Hev_Rx" SG_ 75 VedsRw3dBckl_D_Ltchd 1;
BA_ "U_CD4_MY14_Phev_Rx" SG_ 75 VedsRw3dBckl_D_Ltchd 1;
BA_ "U_CD4_MY13_Diesel_Tx" SG_ 75 VedsRw3dBckl_D_Ltchd 1;
BA_ "U_CD4_MY13_Gas_Tx" SG_ 75 VedsRw3dBckl_D_Ltchd 1;
BA_ "U_CD4_MY13_Hev_Tx" SG_ 75 VedsRw3dBckl_D_Ltchd 1;
BA_ "U_CD4_MY13_Diesel_Rx" SG_ 75 VedsRw2pBckl_D_Ltchd 1;
BA_ "U_CD4_MY13_Gas_Rx" SG_ 75 VedsRw2pBckl_D_Ltchd 1;
BA_ "U_CD4_MY13_Hev_Rx" SG_ 75 VedsRw2pBckl_D_Ltchd 1;
BA_ "U_CD4_MY13_Phev_Rx" SG_ 75 VedsRw2pBckl_D_Ltchd 1;
BA_ "U_CD42_MY14_Diesel_Rx" SG_ 75 VedsRw2pBckl_D_Ltchd 1;
BA_ "U_CD42_MY14_Gas_Rx" SG_ 75 VedsRw2pBckl_D_Ltchd 1;
BA_ "U_P552_MY15_Gas_Rx" SG_ 75 VedsRw2pBckl_D_Ltchd 1;
BA_ "U_S550_MY15_Gas_Rx" SG_ 75 VedsRw2pBckl_D_Ltchd 1;
BA_ "U_C489_MY14_Gas_Rx" SG_ 75 VedsRw2pBckl_D_Ltchd 1;
BA_ "U_U502_MY15_Gas_Rx" SG_ 75 VedsRw2pBckl_D_Ltchd 1;
BA_ "U_CD43_MY16_Gas_Rx" SG_ 75 VedsRw2pBckl_D_Ltchd 1;
BA_ "U_CD4_MY14_Diesel_Rx" SG_ 75 VedsRw2pBckl_D_Ltchd 1;
BA_ "U_CD4_MY14_Gas_Rx" SG_ 75 VedsRw2pBckl_D_Ltchd 1;
BA_ "U_CD4_MY14_Hev_Rx" SG_ 75 VedsRw2pBckl_D_Ltchd 1;
BA_ "U_CD4_MY14_Phev_Rx" SG_ 75 VedsRw2pBckl_D_Ltchd 1;
BA_ "U_CD4_MY13_Diesel_Tx" SG_ 75 VedsRw2pBckl_D_Ltchd 1;
BA_ "U_CD4_MY13_Gas_Tx" SG_ 75 VedsRw2pBckl_D_Ltchd 1;
BA_ "U_CD4_MY13_Hev_Tx" SG_ 75 VedsRw2pBckl_D_Ltchd 1;
BA_ "U_CD4_MY13_Diesel_Rx" SG_ 75 VedsRw2mBckl_D_Ltchd 1;
BA_ "U_CD4_MY13_Gas_Rx" SG_ 75 VedsRw2mBckl_D_Ltchd 1;
BA_ "U_CD4_MY13_Hev_Rx" SG_ 75 VedsRw2mBckl_D_Ltchd 1;
BA_ "U_CD4_MY13_Phev_Rx" SG_ 75 VedsRw2mBckl_D_Ltchd 1;
BA_ "U_CD42_MY14_Diesel_Rx" SG_ 75 VedsRw2mBckl_D_Ltchd 1;
BA_ "U_CD42_MY14_Gas_Rx" SG_ 75 VedsRw2mBckl_D_Ltchd 1;
BA_ "U_P552_MY15_Gas_Rx" SG_ 75 VedsRw2mBckl_D_Ltchd 1;
BA_ "U_S550_MY15_Gas_Rx" SG_ 75 VedsRw2mBckl_D_Ltchd 1;
BA_ "U_C489_MY14_Gas_Rx" SG_ 75 VedsRw2mBckl_D_Ltchd 1;
BA_ "U_U502_MY15_Gas_Rx" SG_ 75 VedsRw2mBckl_D_Ltchd 1;
BA_ "U_CD43_MY16_Gas_Rx" SG_ 75 VedsRw2mBckl_D_Ltchd 1;
BA_ "U_CD4_MY14_Diesel_Rx" SG_ 75 VedsRw2mBckl_D_Ltchd 1;
BA_ "U_CD4_MY14_Gas_Rx" SG_ 75 VedsRw2mBckl_D_Ltchd 1;
BA_ "U_CD4_MY14_Hev_Rx" SG_ 75 VedsRw2mBckl_D_Ltchd 1;
BA_ "U_CD4_MY14_Phev_Rx" SG_ 75 VedsRw2mBckl_D_Ltchd 1;
BA_ "U_CD4_MY13_Diesel_Tx" SG_ 75 VedsRw2mBckl_D_Ltchd 1;
BA_ "U_CD4_MY13_Gas_Tx" SG_ 75 VedsRw2mBckl_D_Ltchd 1;
BA_ "U_CD4_MY13_Hev_Tx" SG_ 75 VedsRw2mBckl_D_Ltchd 1;
BA_ "U_CD4_MY13_Diesel_Rx" SG_ 75 VedsRw2dBckl_D_Ltchd 1;
BA_ "U_CD4_MY13_Gas_Rx" SG_ 75 VedsRw2dBckl_D_Ltchd 1;
BA_ "U_CD4_MY13_Hev_Rx" SG_ 75 VedsRw2dBckl_D_Ltchd 1;
BA_ "U_CD4_MY13_Phev_Rx" SG_ 75 VedsRw2dBckl_D_Ltchd 1;
BA_ "U_CD42_MY14_Diesel_Rx" SG_ 75 VedsRw2dBckl_D_Ltchd 1;
BA_ "U_CD42_MY14_Gas_Rx" SG_ 75 VedsRw2dBckl_D_Ltchd 1;
BA_ "U_P552_MY15_Gas_Rx" SG_ 75 VedsRw2dBckl_D_Ltchd 1;
BA_ "U_S550_MY15_Gas_Rx" SG_ 75 VedsRw2dBckl_D_Ltchd 1;
BA_ "U_C489_MY14_Gas_Rx" SG_ 75 VedsRw2dBckl_D_Ltchd 1;
BA_ "U_U502_MY15_Gas_Rx" SG_ 75 VedsRw2dBckl_D_Ltchd 1;
BA_ "U_CD43_MY16_Gas_Rx" SG_ 75 VedsRw2dBckl_D_Ltchd 1;
BA_ "U_CD4_MY14_Diesel_Rx" SG_ 75 VedsRw2dBckl_D_Ltchd 1;
BA_ "U_CD4_MY14_Gas_Rx" SG_ 75 VedsRw2dBckl_D_Ltchd 1;
BA_ "U_CD4_MY14_Hev_Rx" SG_ 75 VedsRw2dBckl_D_Ltchd 1;
BA_ "U_CD4_MY14_Phev_Rx" SG_ 75 VedsRw2dBckl_D_Ltchd 1;
BA_ "U_CD4_MY13_Diesel_Tx" SG_ 75 VedsRw2dBckl_D_Ltchd 1;
BA_ "U_CD4_MY13_Gas_Tx" SG_ 75 VedsRw2dBckl_D_Ltchd 1;
BA_ "U_CD4_MY13_Hev_Tx" SG_ 75 VedsRw2dBckl_D_Ltchd 1;
BA_ "U_CD4_MY13_Diesel_Rx" SG_ 75 VedsRw1PasChld_D_Ltchd 1;
BA_ "U_CD4_MY13_Gas_Rx" SG_ 75 VedsRw1PasChld_D_Ltchd 1;
BA_ "U_CD4_MY13_Hev_Rx" SG_ 75 VedsRw1PasChld_D_Ltchd 1;
BA_ "U_CD4_MY13_Phev_Rx" SG_ 75 VedsRw1PasChld_D_Ltchd 1;
BA_ "U_CD42_MY14_Diesel_Rx" SG_ 75 VedsRw1PasChld_D_Ltchd 1;
BA_ "U_CD42_MY14_Gas_Rx" SG_ 75 VedsRw1PasChld_D_Ltchd 1;
BA_ "U_P552_MY15_Gas_Rx" SG_ 75 VedsRw1PasChld_D_Ltchd 1;
BA_ "U_S550_MY15_Gas_Rx" SG_ 75 VedsRw1PasChld_D_Ltchd 1;
BA_ "U_C489_MY14_Gas_Rx" SG_ 75 VedsRw1PasChld_D_Ltchd 1;
BA_ "U_U502_MY15_Gas_Rx" SG_ 75 VedsRw1PasChld_D_Ltchd 1;
BA_ "U_CD43_MY16_Gas_Rx" SG_ 75 VedsRw1PasChld_D_Ltchd 1;
BA_ "U_CD4_MY14_Diesel_Rx" SG_ 75 VedsRw1PasChld_D_Ltchd 1;
BA_ "U_CD4_MY14_Gas_Rx" SG_ 75 VedsRw1PasChld_D_Ltchd 1;
BA_ "U_CD4_MY14_Hev_Rx" SG_ 75 VedsRw1PasChld_D_Ltchd 1;
BA_ "U_CD4_MY14_Phev_Rx" SG_ 75 VedsRw1PasChld_D_Ltchd 1;
BA_ "U_CD4_MY13_Diesel_Tx" SG_ 75 VedsRw1PasChld_D_Ltchd 1;
BA_ "U_CD4_MY13_Gas_Tx" SG_ 75 VedsRw1PasChld_D_Ltchd 1;
BA_ "U_CD4_MY13_Hev_Tx" SG_ 75 VedsRw1PasChld_D_Ltchd 1;
BA_ "U_CD4_MY13_Diesel_Rx" SG_ 75 VedsRw1PasBckl_D_Ltchd 1;
BA_ "U_CD4_MY13_Gas_Rx" SG_ 75 VedsRw1PasBckl_D_Ltchd 1;
BA_ "U_CD4_MY13_Hev_Rx" SG_ 75 VedsRw1PasBckl_D_Ltchd 1;
BA_ "U_CD4_MY13_Phev_Rx" SG_ 75 VedsRw1PasBckl_D_Ltchd 1;
BA_ "U_CD42_MY14_Diesel_Rx" SG_ 75 VedsRw1PasBckl_D_Ltchd 1;
BA_ "U_CD42_MY14_Gas_Rx" SG_ 75 VedsRw1PasBckl_D_Ltchd 1;
BA_ "U_P552_MY15_Gas_Rx" SG_ 75 VedsRw1PasBckl_D_Ltchd 1;
BA_ "U_S550_MY15_Gas_Rx" SG_ 75 VedsRw1PasBckl_D_Ltchd 1;
BA_ "U_C489_MY14_Gas_Rx" SG_ 75 VedsRw1PasBckl_D_Ltchd 1;
BA_ "U_U502_MY15_Gas_Rx" SG_ 75 VedsRw1PasBckl_D_Ltchd 1;
BA_ "U_CD43_MY16_Gas_Rx" SG_ 75 VedsRw1PasBckl_D_Ltchd 1;
BA_ "U_CD4_MY14_Diesel_Rx" SG_ 75 VedsRw1PasBckl_D_Ltchd 1;
BA_ "U_CD4_MY14_Gas_Rx" SG_ 75 VedsRw1PasBckl_D_Ltchd 1;
BA_ "U_CD4_MY14_Hev_Rx" SG_ 75 VedsRw1PasBckl_D_Ltchd 1;
BA_ "U_CD4_MY14_Phev_Rx" SG_ 75 VedsRw1PasBckl_D_Ltchd 1;
BA_ "U_CD4_MY13_Diesel_Tx" SG_ 75 VedsRw1PasBckl_D_Ltchd 1;
BA_ "U_CD4_MY13_Gas_Tx" SG_ 75 VedsRw1PasBckl_D_Ltchd 1;
BA_ "U_CD4_MY13_Hev_Tx" SG_ 75 VedsRw1PasBckl_D_Ltchd 1;
BA_ "U_CD4_MY13_Diesel_Rx" SG_ 75 VedsRw1DrvBckl_D_Ltchd 1;
BA_ "U_CD4_MY13_Gas_Rx" SG_ 75 VedsRw1DrvBckl_D_Ltchd 1;
BA_ "U_CD4_MY13_Hev_Rx" SG_ 75 VedsRw1DrvBckl_D_Ltchd 1;
BA_ "U_CD4_MY13_Phev_Rx" SG_ 75 VedsRw1DrvBckl_D_Ltchd 1;
BA_ "U_CD42_MY14_Diesel_Rx" SG_ 75 VedsRw1DrvBckl_D_Ltchd 1;
BA_ "U_CD42_MY14_Gas_Rx" SG_ 75 VedsRw1DrvBckl_D_Ltchd 1;
BA_ "U_P552_MY15_Gas_Rx" SG_ 75 VedsRw1DrvBckl_D_Ltchd 1;
BA_ "U_S550_MY15_Gas_Rx" SG_ 75 VedsRw1DrvBckl_D_Ltchd 1;
BA_ "U_C489_MY14_Gas_Rx" SG_ 75 VedsRw1DrvBckl_D_Ltchd 1;
BA_ "U_U502_MY15_Gas_Rx" SG_ 75 VedsRw1DrvBckl_D_Ltchd 1;
BA_ "U_CD43_MY16_Gas_Rx" SG_ 75 VedsRw1DrvBckl_D_Ltchd 1;
BA_ "U_CD4_MY14_Diesel_Rx" SG_ 75 VedsRw1DrvBckl_D_Ltchd 1;
BA_ "U_CD4_MY14_Gas_Rx" SG_ 75 VedsRw1DrvBckl_D_Ltchd 1;
BA_ "U_CD4_MY14_Hev_Rx" SG_ 75 VedsRw1DrvBckl_D_Ltchd 1;
BA_ "U_CD4_MY14_Phev_Rx" SG_ 75 VedsRw1DrvBckl_D_Ltchd 1;
BA_ "U_CD4_MY13_Diesel_Tx" SG_ 75 VedsRw1DrvBckl_D_Ltchd 1;
BA_ "U_CD4_MY13_Gas_Tx" SG_ 75 VedsRw1DrvBckl_D_Ltchd 1;
BA_ "U_CD4_MY13_Hev_Tx" SG_ 75 VedsRw1DrvBckl_D_Ltchd 1;
BA_ "U_CD4_MY13_Diesel_Rx" SG_ 74 VedsPasSideBag_D_Ltchd 1;
BA_ "U_CD4_MY13_Gas_Rx" SG_ 74 VedsPasSideBag_D_Ltchd 1;
BA_ "U_CD4_MY13_Hev_Rx" SG_ 74 VedsPasSideBag_D_Ltchd 1;
BA_ "U_CD4_MY13_Phev_Rx" SG_ 74 VedsPasSideBag_D_Ltchd 1;
BA_ "U_CD42_MY14_Diesel_Rx" SG_ 74 VedsPasSideBag_D_Ltchd 1;
BA_ "U_CD42_MY14_Gas_Rx" SG_ 74 VedsPasSideBag_D_Ltchd 1;
BA_ "U_P552_MY15_Gas_Rx" SG_ 74 VedsPasSideBag_D_Ltchd 1;
BA_ "U_S550_MY15_Gas_Rx" SG_ 74 VedsPasSideBag_D_Ltchd 1;
BA_ "U_C489_MY14_Gas_Rx" SG_ 74 VedsPasSideBag_D_Ltchd 1;
BA_ "U_U502_MY15_Gas_Rx" SG_ 74 VedsPasSideBag_D_Ltchd 1;
BA_ "U_CD43_MY16_Gas_Rx" SG_ 74 VedsPasSideBag_D_Ltchd 1;
BA_ "U_CD4_MY14_Diesel_Rx" SG_ 74 VedsPasSideBag_D_Ltchd 1;
BA_ "U_CD4_MY14_Gas_Rx" SG_ 74 VedsPasSideBag_D_Ltchd 1;
BA_ "U_CD4_MY14_Hev_Rx" SG_ 74 VedsPasSideBag_D_Ltchd 1;
BA_ "U_CD4_MY14_Phev_Rx" SG_ 74 VedsPasSideBag_D_Ltchd 1;
BA_ "U_CD4_MY13_Diesel_Tx" SG_ 74 VedsPasSideBag_D_Ltchd 1;
BA_ "U_CD4_MY13_Gas_Tx" SG_ 74 VedsPasSideBag_D_Ltchd 1;
BA_ "U_CD4_MY13_Hev_Tx" SG_ 74 VedsPasSideBag_D_Ltchd 1;
BA_ "U_CD4_MY13_Diesel_Rx" SG_ 74 VedsPasCrtnBag_D_Ltchd 1;
BA_ "U_CD4_MY13_Gas_Rx" SG_ 74 VedsPasCrtnBag_D_Ltchd 1;
BA_ "U_CD4_MY13_Hev_Rx" SG_ 74 VedsPasCrtnBag_D_Ltchd 1;
BA_ "U_CD4_MY13_Phev_Rx" SG_ 74 VedsPasCrtnBag_D_Ltchd 1;
BA_ "U_CD42_MY14_Diesel_Rx" SG_ 74 VedsPasCrtnBag_D_Ltchd 1;
BA_ "U_CD42_MY14_Gas_Rx" SG_ 74 VedsPasCrtnBag_D_Ltchd 1;
BA_ "U_P552_MY15_Gas_Rx" SG_ 74 VedsPasCrtnBag_D_Ltchd 1;
BA_ "U_S550_MY15_Gas_Rx" SG_ 74 VedsPasCrtnBag_D_Ltchd 1;
BA_ "U_C489_MY14_Gas_Rx" SG_ 74 VedsPasCrtnBag_D_Ltchd 1;
BA_ "U_U502_MY15_Gas_Rx" SG_ 74 VedsPasCrtnBag_D_Ltchd 1;
BA_ "U_CD43_MY16_Gas_Rx" SG_ 74 VedsPasCrtnBag_D_Ltchd 1;
BA_ "U_CD4_MY14_Diesel_Rx" SG_ 74 VedsPasCrtnBag_D_Ltchd 1;
BA_ "U_CD4_MY14_Gas_Rx" SG_ 74 VedsPasCrtnBag_D_Ltchd 1;
BA_ "U_CD4_MY14_Hev_Rx" SG_ 74 VedsPasCrtnBag_D_Ltchd 1;
BA_ "U_CD4_MY14_Phev_Rx" SG_ 74 VedsPasCrtnBag_D_Ltchd 1;
BA_ "U_CD4_MY13_Diesel_Tx" SG_ 74 VedsPasCrtnBag_D_Ltchd 1;
BA_ "U_CD4_MY13_Gas_Tx" SG_ 74 VedsPasCrtnBag_D_Ltchd 1;
BA_ "U_CD4_MY13_Hev_Tx" SG_ 74 VedsPasCrtnBag_D_Ltchd 1;
BA_ "U_CD4_MY13_Diesel_Rx" SG_ 74 VedsPasBelt_D_Ltchd 1;
BA_ "U_CD4_MY13_Gas_Rx" SG_ 74 VedsPasBelt_D_Ltchd 1;
BA_ "U_CD4_MY13_Hev_Rx" SG_ 74 VedsPasBelt_D_Ltchd 1;
BA_ "U_CD4_MY13_Phev_Rx" SG_ 74 VedsPasBelt_D_Ltchd 1;
BA_ "U_CD42_MY14_Diesel_Rx" SG_ 74 VedsPasBelt_D_Ltchd 1;
BA_ "U_CD42_MY14_Gas_Rx" SG_ 74 VedsPasBelt_D_Ltchd 1;
BA_ "U_P552_MY15_Gas_Rx" SG_ 74 VedsPasBelt_D_Ltchd 1;
BA_ "U_S550_MY15_Gas_Rx" SG_ 74 VedsPasBelt_D_Ltchd 1;
BA_ "U_C489_MY14_Gas_Rx" SG_ 74 VedsPasBelt_D_Ltchd 1;
BA_ "U_U502_MY15_Gas_Rx" SG_ 74 VedsPasBelt_D_Ltchd 1;
BA_ "U_CD43_MY16_Gas_Rx" SG_ 74 VedsPasBelt_D_Ltchd 1;
BA_ "U_CD4_MY14_Diesel_Rx" SG_ 74 VedsPasBelt_D_Ltchd 1;
BA_ "U_CD4_MY14_Gas_Rx" SG_ 74 VedsPasBelt_D_Ltchd 1;
BA_ "U_CD4_MY14_Hev_Rx" SG_ 74 VedsPasBelt_D_Ltchd 1;
BA_ "U_CD4_MY14_Phev_Rx" SG_ 74 VedsPasBelt_D_Ltchd 1;
BA_ "U_CD4_MY13_Diesel_Tx" SG_ 74 VedsPasBelt_D_Ltchd 1;
BA_ "U_CD4_MY13_Gas_Tx" SG_ 74 VedsPasBelt_D_Ltchd 1;
BA_ "U_CD4_MY13_Hev_Tx" SG_ 74 VedsPasBelt_D_Ltchd 1;
BA_ "U_CD4_MY13_Diesel_Rx" SG_ 74 VedsPasBag_D_Ltchd 1;
BA_ "U_CD4_MY13_Gas_Rx" SG_ 74 VedsPasBag_D_Ltchd 1;
BA_ "U_CD4_MY13_Hev_Rx" SG_ 74 VedsPasBag_D_Ltchd 1;
BA_ "U_CD4_MY13_Phev_Rx" SG_ 74 VedsPasBag_D_Ltchd 1;
BA_ "U_CD42_MY14_Diesel_Rx" SG_ 74 VedsPasBag_D_Ltchd 1;
BA_ "U_CD42_MY14_Gas_Rx" SG_ 74 VedsPasBag_D_Ltchd 1;
BA_ "U_P552_MY15_Gas_Rx" SG_ 74 VedsPasBag_D_Ltchd 1;
BA_ "U_S550_MY15_Gas_Rx" SG_ 74 VedsPasBag_D_Ltchd 1;
BA_ "U_C489_MY14_Gas_Rx" SG_ 74 VedsPasBag_D_Ltchd 1;
BA_ "U_U502_MY15_Gas_Rx" SG_ 74 VedsPasBag_D_Ltchd 1;
BA_ "U_CD43_MY16_Gas_Rx" SG_ 74 VedsPasBag_D_Ltchd 1;
BA_ "U_CD4_MY14_Diesel_Rx" SG_ 74 VedsPasBag_D_Ltchd 1;
BA_ "U_CD4_MY14_Gas_Rx" SG_ 74 VedsPasBag_D_Ltchd 1;
BA_ "U_CD4_MY14_Hev_Rx" SG_ 74 VedsPasBag_D_Ltchd 1;
BA_ "U_CD4_MY14_Phev_Rx" SG_ 74 VedsPasBag_D_Ltchd 1;
BA_ "U_CD4_MY13_Diesel_Tx" SG_ 74 VedsPasBag_D_Ltchd 1;
BA_ "U_CD4_MY13_Gas_Tx" SG_ 74 VedsPasBag_D_Ltchd 1;
BA_ "U_CD4_MY13_Hev_Tx" SG_ 74 VedsPasBag_D_Ltchd 1;
BA_ "U_CD4_MY13_Diesel_Rx" SG_ 74 VedsMultiEvnt_D_Ltchd 1;
BA_ "U_CD4_MY13_Gas_Rx" SG_ 74 VedsMultiEvnt_D_Ltchd 1;
BA_ "U_CD4_MY13_Hev_Rx" SG_ 74 VedsMultiEvnt_D_Ltchd 1;
BA_ "U_CD4_MY13_Phev_Rx" SG_ 74 VedsMultiEvnt_D_Ltchd 1;
BA_ "U_CD42_MY14_Diesel_Rx" SG_ 74 VedsMultiEvnt_D_Ltchd 1;
BA_ "U_CD42_MY14_Gas_Rx" SG_ 74 VedsMultiEvnt_D_Ltchd 1;
BA_ "U_P552_MY15_Gas_Rx" SG_ 74 VedsMultiEvnt_D_Ltchd 1;
BA_ "U_S550_MY15_Gas_Rx" SG_ 74 VedsMultiEvnt_D_Ltchd 1;
BA_ "U_C489_MY14_Gas_Rx" SG_ 74 VedsMultiEvnt_D_Ltchd 1;
BA_ "U_U502_MY15_Gas_Rx" SG_ 74 VedsMultiEvnt_D_Ltchd 1;
BA_ "U_CD43_MY16_Gas_Rx" SG_ 74 VedsMultiEvnt_D_Ltchd 1;
BA_ "U_CD4_MY14_Diesel_Rx" SG_ 74 VedsMultiEvnt_D_Ltchd 1;
BA_ "U_CD4_MY14_Gas_Rx" SG_ 74 VedsMultiEvnt_D_Ltchd 1;
BA_ "U_CD4_MY14_Hev_Rx" SG_ 74 VedsMultiEvnt_D_Ltchd 1;
BA_ "U_CD4_MY14_Phev_Rx" SG_ 74 VedsMultiEvnt_D_Ltchd 1;
BA_ "U_CD4_MY13_Diesel_Tx" SG_ 74 VedsMultiEvnt_D_Ltchd 1;
BA_ "U_CD4_MY13_Gas_Tx" SG_ 74 VedsMultiEvnt_D_Ltchd 1;
BA_ "U_CD4_MY13_Hev_Tx" SG_ 74 VedsMultiEvnt_D_Ltchd 1;
BA_ "U_CD4_MY13_Diesel_Rx" SG_ 74 VedsMaxDeltaV_D_Ltchd 1;
BA_ "U_CD4_MY13_Gas_Rx" SG_ 74 VedsMaxDeltaV_D_Ltchd 1;
BA_ "U_CD4_MY13_Hev_Rx" SG_ 74 VedsMaxDeltaV_D_Ltchd 1;
BA_ "U_CD4_MY13_Phev_Rx" SG_ 74 VedsMaxDeltaV_D_Ltchd 1;
BA_ "U_CD42_MY14_Diesel_Rx" SG_ 74 VedsMaxDeltaV_D_Ltchd 1;
BA_ "U_CD42_MY14_Gas_Rx" SG_ 74 VedsMaxDeltaV_D_Ltchd 1;
BA_ "U_P552_MY15_Gas_Rx" SG_ 74 VedsMaxDeltaV_D_Ltchd 1;
BA_ "U_S550_MY15_Gas_Rx" SG_ 74 VedsMaxDeltaV_D_Ltchd 1;
BA_ "U_C489_MY14_Gas_Rx" SG_ 74 VedsMaxDeltaV_D_Ltchd 1;
BA_ "U_U502_MY15_Gas_Rx" SG_ 74 VedsMaxDeltaV_D_Ltchd 1;
BA_ "U_CD43_MY16_Gas_Rx" SG_ 74 VedsMaxDeltaV_D_Ltchd 1;
BA_ "U_CD4_MY14_Diesel_Rx" SG_ 74 VedsMaxDeltaV_D_Ltchd 1;
BA_ "U_CD4_MY14_Gas_Rx" SG_ 74 VedsMaxDeltaV_D_Ltchd 1;
BA_ "U_CD4_MY14_Hev_Rx" SG_ 74 VedsMaxDeltaV_D_Ltchd 1;
BA_ "U_CD4_MY14_Phev_Rx" SG_ 74 VedsMaxDeltaV_D_Ltchd 1;
BA_ "U_CD4_MY13_Diesel_Tx" SG_ 74 VedsMaxDeltaV_D_Ltchd 1;
BA_ "U_CD4_MY13_Gas_Tx" SG_ 74 VedsMaxDeltaV_D_Ltchd 1;
BA_ "U_CD4_MY13_Hev_Tx" SG_ 74 VedsMaxDeltaV_D_Ltchd 1;
BA_ "U_CD4_MY13_Diesel_Rx" SG_ 74 VedsDrvKneeBag_D_Ltchd 1;
BA_ "U_CD4_MY13_Gas_Rx" SG_ 74 VedsDrvKneeBag_D_Ltchd 1;
BA_ "U_CD4_MY13_Hev_Rx" SG_ 74 VedsDrvKneeBag_D_Ltchd 1;
BA_ "U_CD4_MY13_Phev_Rx" SG_ 74 VedsDrvKneeBag_D_Ltchd 1;
BA_ "U_CD42_MY14_Diesel_Rx" SG_ 74 VedsDrvKneeBag_D_Ltchd 1;
BA_ "U_CD42_MY14_Gas_Rx" SG_ 74 VedsDrvKneeBag_D_Ltchd 1;
BA_ "U_P552_MY15_Gas_Rx" SG_ 74 VedsDrvKneeBag_D_Ltchd 1;
BA_ "U_S550_MY15_Gas_Rx" SG_ 74 VedsDrvKneeBag_D_Ltchd 1;
BA_ "U_C489_MY14_Gas_Rx" SG_ 74 VedsDrvKneeBag_D_Ltchd 1;
BA_ "U_U502_MY15_Gas_Rx" SG_ 74 VedsDrvKneeBag_D_Ltchd 1;
BA_ "U_CD43_MY16_Gas_Rx" SG_ 74 VedsDrvKneeBag_D_Ltchd 1;
BA_ "U_CD4_MY14_Diesel_Rx" SG_ 74 VedsDrvKneeBag_D_Ltchd 1;
BA_ "U_CD4_MY14_Gas_Rx" SG_ 74 VedsDrvKneeBag_D_Ltchd 1;
BA_ "U_CD4_MY14_Hev_Rx" SG_ 74 VedsDrvKneeBag_D_Ltchd 1;
BA_ "U_CD4_MY14_Phev_Rx" SG_ 74 VedsDrvKneeBag_D_Ltchd 1;
BA_ "U_CD4_MY13_Diesel_Tx" SG_ 74 VedsDrvKneeBag_D_Ltchd 1;
BA_ "U_CD4_MY13_Gas_Tx" SG_ 74 VedsDrvKneeBag_D_Ltchd 1;
BA_ "U_CD4_MY13_Hev_Tx" SG_ 74 VedsDrvKneeBag_D_Ltchd 1;
BA_ "U_CD4_MY13_Diesel_Rx" SG_ 74 VedsEvntType_D_Ltchd 1;
BA_ "U_CD4_MY13_Gas_Rx" SG_ 74 VedsEvntType_D_Ltchd 1;
BA_ "U_CD4_MY13_Hev_Rx" SG_ 74 VedsEvntType_D_Ltchd 1;
BA_ "U_CD4_MY13_Phev_Rx" SG_ 74 VedsEvntType_D_Ltchd 1;
BA_ "U_CD42_MY14_Diesel_Rx" SG_ 74 VedsEvntType_D_Ltchd 1;
BA_ "U_CD42_MY14_Gas_Rx" SG_ 74 VedsEvntType_D_Ltchd 1;
BA_ "U_P552_MY15_Gas_Rx" SG_ 74 VedsEvntType_D_Ltchd 1;
BA_ "U_S550_MY15_Gas_Rx" SG_ 74 VedsEvntType_D_Ltchd 1;
BA_ "U_C489_MY14_Gas_Rx" SG_ 74 VedsEvntType_D_Ltchd 1;
BA_ "U_U502_MY15_Gas_Rx" SG_ 74 VedsEvntType_D_Ltchd 1;
BA_ "U_CD43_MY16_Gas_Rx" SG_ 74 VedsEvntType_D_Ltchd 1;
BA_ "U_CD4_MY14_Diesel_Rx" SG_ 74 VedsEvntType_D_Ltchd 1;
BA_ "U_CD4_MY14_Gas_Rx" SG_ 74 VedsEvntType_D_Ltchd 1;
BA_ "U_CD4_MY14_Hev_Rx" SG_ 74 VedsEvntType_D_Ltchd 1;
BA_ "U_CD4_MY14_Phev_Rx" SG_ 74 VedsEvntType_D_Ltchd 1;
BA_ "U_CD4_MY13_Diesel_Tx" SG_ 74 VedsEvntType_D_Ltchd 1;
BA_ "U_CD4_MY13_Gas_Tx" SG_ 74 VedsEvntType_D_Ltchd 1;
BA_ "U_CD4_MY13_Hev_Tx" SG_ 74 VedsEvntType_D_Ltchd 1;
BA_ "U_CD4_MY13_Diesel_Rx" SG_ 74 VedsEvntRoll_D_Ltchd 1;
BA_ "U_CD4_MY13_Gas_Rx" SG_ 74 VedsEvntRoll_D_Ltchd 1;
BA_ "U_CD4_MY13_Hev_Rx" SG_ 74 VedsEvntRoll_D_Ltchd 1;
BA_ "U_CD4_MY13_Phev_Rx" SG_ 74 VedsEvntRoll_D_Ltchd 1;
BA_ "U_CD42_MY14_Diesel_Rx" SG_ 74 VedsEvntRoll_D_Ltchd 1;
BA_ "U_CD42_MY14_Gas_Rx" SG_ 74 VedsEvntRoll_D_Ltchd 1;
BA_ "U_P552_MY15_Gas_Rx" SG_ 74 VedsEvntRoll_D_Ltchd 1;
BA_ "U_S550_MY15_Gas_Rx" SG_ 74 VedsEvntRoll_D_Ltchd 1;
BA_ "U_C489_MY14_Gas_Rx" SG_ 74 VedsEvntRoll_D_Ltchd 1;
BA_ "U_U502_MY15_Gas_Rx" SG_ 74 VedsEvntRoll_D_Ltchd 1;
BA_ "U_CD43_MY16_Gas_Rx" SG_ 74 VedsEvntRoll_D_Ltchd 1;
BA_ "U_CD4_MY14_Diesel_Rx" SG_ 74 VedsEvntRoll_D_Ltchd 1;
BA_ "U_CD4_MY14_Gas_Rx" SG_ 74 VedsEvntRoll_D_Ltchd 1;
BA_ "U_CD4_MY14_Hev_Rx" SG_ 74 VedsEvntRoll_D_Ltchd 1;
BA_ "U_CD4_MY14_Phev_Rx" SG_ 74 VedsEvntRoll_D_Ltchd 1;
BA_ "U_CD4_MY13_Diesel_Tx" SG_ 74 VedsEvntRoll_D_Ltchd 1;
BA_ "U_CD4_MY13_Gas_Tx" SG_ 74 VedsEvntRoll_D_Ltchd 1;
BA_ "U_CD4_MY13_Hev_Tx" SG_ 74 VedsEvntRoll_D_Ltchd 1;
BA_ "U_CD4_MY13_Diesel_Rx" SG_ 74 VedsDrvSideBag_D_Ltchd 1;
BA_ "U_CD4_MY13_Gas_Rx" SG_ 74 VedsDrvSideBag_D_Ltchd 1;
BA_ "U_CD4_MY13_Hev_Rx" SG_ 74 VedsDrvSideBag_D_Ltchd 1;
BA_ "U_CD4_MY13_Phev_Rx" SG_ 74 VedsDrvSideBag_D_Ltchd 1;
BA_ "U_CD42_MY14_Diesel_Rx" SG_ 74 VedsDrvSideBag_D_Ltchd 1;
BA_ "U_CD42_MY14_Gas_Rx" SG_ 74 VedsDrvSideBag_D_Ltchd 1;
BA_ "U_P552_MY15_Gas_Rx" SG_ 74 VedsDrvSideBag_D_Ltchd 1;
BA_ "U_S550_MY15_Gas_Rx" SG_ 74 VedsDrvSideBag_D_Ltchd 1;
BA_ "U_C489_MY14_Gas_Rx" SG_ 74 VedsDrvSideBag_D_Ltchd 1;
BA_ "U_U502_MY15_Gas_Rx" SG_ 74 VedsDrvSideBag_D_Ltchd 1;
BA_ "U_CD43_MY16_Gas_Rx" SG_ 74 VedsDrvSideBag_D_Ltchd 1;
BA_ "U_CD4_MY14_Diesel_Rx" SG_ 74 VedsDrvSideBag_D_Ltchd 1;
BA_ "U_CD4_MY14_Gas_Rx" SG_ 74 VedsDrvSideBag_D_Ltchd 1;
BA_ "U_CD4_MY14_Hev_Rx" SG_ 74 VedsDrvSideBag_D_Ltchd 1;
BA_ "U_CD4_MY14_Phev_Rx" SG_ 74 VedsDrvSideBag_D_Ltchd 1;
BA_ "U_CD4_MY13_Diesel_Tx" SG_ 74 VedsDrvSideBag_D_Ltchd 1;
BA_ "U_CD4_MY13_Gas_Tx" SG_ 74 VedsDrvSideBag_D_Ltchd 1;
BA_ "U_CD4_MY13_Hev_Tx" SG_ 74 VedsDrvSideBag_D_Ltchd 1;
BA_ "U_CD4_MY13_Diesel_Rx" SG_ 74 VedsDrvCrtnBag_D_Ltchd 1;
BA_ "U_CD4_MY13_Gas_Rx" SG_ 74 VedsDrvCrtnBag_D_Ltchd 1;
BA_ "U_CD4_MY13_Hev_Rx" SG_ 74 VedsDrvCrtnBag_D_Ltchd 1;
BA_ "U_CD4_MY13_Phev_Rx" SG_ 74 VedsDrvCrtnBag_D_Ltchd 1;
BA_ "U_CD42_MY14_Diesel_Rx" SG_ 74 VedsDrvCrtnBag_D_Ltchd 1;
BA_ "U_CD42_MY14_Gas_Rx" SG_ 74 VedsDrvCrtnBag_D_Ltchd 1;
BA_ "U_P552_MY15_Gas_Rx" SG_ 74 VedsDrvCrtnBag_D_Ltchd 1;
BA_ "U_S550_MY15_Gas_Rx" SG_ 74 VedsDrvCrtnBag_D_Ltchd 1;
BA_ "U_C489_MY14_Gas_Rx" SG_ 74 VedsDrvCrtnBag_D_Ltchd 1;
BA_ "U_U502_MY15_Gas_Rx" SG_ 74 VedsDrvCrtnBag_D_Ltchd 1;
BA_ "U_CD43_MY16_Gas_Rx" SG_ 74 VedsDrvCrtnBag_D_Ltchd 1;
BA_ "U_CD4_MY14_Diesel_Rx" SG_ 74 VedsDrvCrtnBag_D_Ltchd 1;
BA_ "U_CD4_MY14_Gas_Rx" SG_ 74 VedsDrvCrtnBag_D_Ltchd 1;
BA_ "U_CD4_MY14_Hev_Rx" SG_ 74 VedsDrvCrtnBag_D_Ltchd 1;
BA_ "U_CD4_MY14_Phev_Rx" SG_ 74 VedsDrvCrtnBag_D_Ltchd 1;
BA_ "U_CD4_MY13_Diesel_Tx" SG_ 74 VedsDrvCrtnBag_D_Ltchd 1;
BA_ "U_CD4_MY13_Gas_Tx" SG_ 74 VedsDrvCrtnBag_D_Ltchd 1;
BA_ "U_CD4_MY13_Hev_Tx" SG_ 74 VedsDrvCrtnBag_D_Ltchd 1;
BA_ "U_CD4_MY13_Diesel_Rx" SG_ 74 VedsDrvBelt_D_Ltchd 1;
BA_ "U_CD4_MY13_Gas_Rx" SG_ 74 VedsDrvBelt_D_Ltchd 1;
BA_ "U_CD4_MY13_Hev_Rx" SG_ 74 VedsDrvBelt_D_Ltchd 1;
BA_ "U_CD4_MY13_Phev_Rx" SG_ 74 VedsDrvBelt_D_Ltchd 1;
BA_ "U_CD42_MY14_Diesel_Rx" SG_ 74 VedsDrvBelt_D_Ltchd 1;
BA_ "U_CD42_MY14_Gas_Rx" SG_ 74 VedsDrvBelt_D_Ltchd 1;
BA_ "U_P552_MY15_Gas_Rx" SG_ 74 VedsDrvBelt_D_Ltchd 1;
BA_ "U_S550_MY15_Gas_Rx" SG_ 74 VedsDrvBelt_D_Ltchd 1;
BA_ "U_C489_MY14_Gas_Rx" SG_ 74 VedsDrvBelt_D_Ltchd 1;
BA_ "U_U502_MY15_Gas_Rx" SG_ 74 VedsDrvBelt_D_Ltchd 1;
BA_ "U_CD43_MY16_Gas_Rx" SG_ 74 VedsDrvBelt_D_Ltchd 1;
BA_ "U_CD4_MY14_Diesel_Rx" SG_ 74 VedsDrvBelt_D_Ltchd 1;
BA_ "U_CD4_MY14_Gas_Rx" SG_ 74 VedsDrvBelt_D_Ltchd 1;
BA_ "U_CD4_MY14_Hev_Rx" SG_ 74 VedsDrvBelt_D_Ltchd 1;
BA_ "U_CD4_MY14_Phev_Rx" SG_ 74 VedsDrvBelt_D_Ltchd 1;
BA_ "U_CD4_MY13_Diesel_Tx" SG_ 74 VedsDrvBelt_D_Ltchd 1;
BA_ "U_CD4_MY13_Gas_Tx" SG_ 74 VedsDrvBelt_D_Ltchd 1;
BA_ "U_CD4_MY13_Hev_Tx" SG_ 74 VedsDrvBelt_D_Ltchd 1;
BA_ "U_CD4_MY13_Diesel_Rx" SG_ 74 VedsDrvBag_D_Ltchd 1;
BA_ "U_CD4_MY13_Gas_Rx" SG_ 74 VedsDrvBag_D_Ltchd 1;
BA_ "U_CD4_MY13_Hev_Rx" SG_ 74 VedsDrvBag_D_Ltchd 1;
BA_ "U_CD4_MY13_Phev_Rx" SG_ 74 VedsDrvBag_D_Ltchd 1;
BA_ "U_CD42_MY14_Diesel_Rx" SG_ 74 VedsDrvBag_D_Ltchd 1;
BA_ "U_CD42_MY14_Gas_Rx" SG_ 74 VedsDrvBag_D_Ltchd 1;
BA_ "U_P552_MY15_Gas_Rx" SG_ 74 VedsDrvBag_D_Ltchd 1;
BA_ "U_S550_MY15_Gas_Rx" SG_ 74 VedsDrvBag_D_Ltchd 1;
BA_ "U_C489_MY14_Gas_Rx" SG_ 74 VedsDrvBag_D_Ltchd 1;
BA_ "U_U502_MY15_Gas_Rx" SG_ 74 VedsDrvBag_D_Ltchd 1;
BA_ "U_CD43_MY16_Gas_Rx" SG_ 74 VedsDrvBag_D_Ltchd 1;
BA_ "U_CD4_MY14_Diesel_Rx" SG_ 74 VedsDrvBag_D_Ltchd 1;
BA_ "U_CD4_MY14_Gas_Rx" SG_ 74 VedsDrvBag_D_Ltchd 1;
BA_ "U_CD4_MY14_Hev_Rx" SG_ 74 VedsDrvBag_D_Ltchd 1;
BA_ "U_CD4_MY14_Phev_Rx" SG_ 74 VedsDrvBag_D_Ltchd 1;
BA_ "U_CD4_MY13_Diesel_Tx" SG_ 74 VedsDrvBag_D_Ltchd 1;
BA_ "U_CD4_MY13_Gas_Tx" SG_ 74 VedsDrvBag_D_Ltchd 1;
BA_ "U_CD4_MY13_Hev_Tx" SG_ 74 VedsDrvBag_D_Ltchd 1;
BA_ "GenSigStartValue" SG_ 74 eCallNotification 1;
BA_ "U_CD4_MY13_Diesel_Rx" SG_ 74 eCallNotification 1;
BA_ "U_CD4_MY13_Gas_Rx" SG_ 74 eCallNotification 1;
BA_ "U_CD4_MY13_Hev_Rx" SG_ 74 eCallNotification 1;
BA_ "U_CD4_MY13_Phev_Rx" SG_ 74 eCallNotification 1;
BA_ "U_CD42_MY14_Diesel_Rx" SG_ 74 eCallNotification 1;
BA_ "U_CD42_MY14_Gas_Rx" SG_ 74 eCallNotification 1;
BA_ "U_P552_MY15_Gas_Rx" SG_ 74 eCallNotification 1;
BA_ "U_S550_MY15_Gas_Rx" SG_ 74 eCallNotification 1;
BA_ "U_C489_MY14_Gas_Rx" SG_ 74 eCallNotification 1;
BA_ "U_U502_MY15_Gas_Rx" SG_ 74 eCallNotification 1;
BA_ "U_CD43_MY16_Gas_Rx" SG_ 74 eCallNotification 1;
BA_ "U_CD4_MY14_Diesel_Rx" SG_ 74 eCallNotification 1;
BA_ "U_CD4_MY14_Gas_Rx" SG_ 74 eCallNotification 1;
BA_ "U_CD4_MY14_Hev_Rx" SG_ 74 eCallNotification 1;
BA_ "U_CD4_MY14_Phev_Rx" SG_ 74 eCallNotification 1;
BA_ "U_CD4_MY13_Diesel_Tx" SG_ 74 eCallNotification 1;
BA_ "U_CD4_MY13_Gas_Tx" SG_ 74 eCallNotification 1;
BA_ "U_CD4_MY13_Hev_Tx" SG_ 74 eCallNotification 1;
BA_ "GenSigStartValue" SG_ 1076 CenterStackRing_D_Actl 2;
BA_ "GenSigSendType" SG_ 1076 CenterStackRing_D_Actl 3;
BA_ "U_CD4_MY13_Diesel_Tx" SG_ 1076 EngIdlShutDown_B_RqDrv_UB 1;
BA_ "U_CD4_MY13_Gas_Tx" SG_ 1076 EngIdlShutDown_B_RqDrv_UB 1;
BA_ "U_CD4_MY13_Hev_Tx" SG_ 1076 EngIdlShutDown_B_RqDrv_UB 1;
BA_ "GenSigSendType" SG_ 1076 EngIdlShutDown_B_RqDrv 3;
BA_ "U_CD4_MY13_Gas_Rx" SG_ 1076 EngIdlShutDown_B_RqDrv 1;
BA_ "U_CD42_MY14_Gas_Rx" SG_ 1076 EngIdlShutDown_B_RqDrv 1;
BA_ "U_P552_MY15_Gas_Rx" SG_ 1076 EngIdlShutDown_B_RqDrv 1;
BA_ "U_S550_MY15_Gas_Rx" SG_ 1076 EngIdlShutDown_B_RqDrv 1;
BA_ "U_C489_MY14_Gas_Rx" SG_ 1076 EngIdlShutDown_B_RqDrv 1;
BA_ "U_U502_MY15_Gas_Rx" SG_ 1076 EngIdlShutDown_B_RqDrv 1;
BA_ "U_CD43_MY16_Gas_Rx" SG_ 1076 EngIdlShutDown_B_RqDrv 1;
BA_ "U_CD4_MY14_Gas_Rx" SG_ 1076 EngIdlShutDown_B_RqDrv 1;
BA_ "U_CD4_MY13_Diesel_Tx" SG_ 1076 EngIdlShutDown_B_RqDrv 1;
BA_ "U_CD4_MY13_Gas_Tx" SG_ 1076 EngIdlShutDown_B_RqDrv 1;
BA_ "U_CD4_MY13_Hev_Tx" SG_ 1076 EngIdlShutDown_B_RqDrv 1;
BA_ "CrossOver_InfoCAN" SG_ 1076 OdoTripRx_B_Actl 1;
BA_ "GenSigSendType" SG_ 1076 OdoTripRx_B_Actl 3;
BA_ "U_CD4_MY13_Gas_Rx" SG_ 1076 OdoTripRx_B_Actl 1;
BA_ "U_CD42_MY14_Gas_Rx" SG_ 1076 OdoTripRx_B_Actl 1;
BA_ "U_P552_MY15_Gas_Rx" SG_ 1076 OdoTripRx_B_Actl 1;
BA_ "U_S550_MY15_Gas_Rx" SG_ 1076 OdoTripRx_B_Actl 1;
BA_ "U_C489_MY14_Gas_Rx" SG_ 1076 OdoTripRx_B_Actl 1;
BA_ "U_U502_MY15_Gas_Rx" SG_ 1076 OdoTripRx_B_Actl 1;
BA_ "U_CD43_MY16_Gas_Rx" SG_ 1076 OdoTripRx_B_Actl 1;
BA_ "U_CD4_MY14_Gas_Rx" SG_ 1076 OdoTripRx_B_Actl 1;
BA_ "CrossOver_InfoCAN" SG_ 1076 FuelLvlWarn_D_Actl 1;
BA_ "GenSigSendType" SG_ 1076 FuelLvlWarn_D_Actl 3;
BA_ "U_CD4_MY13_Diesel_Rx" SG_ 1076 TirePReset_B_Rq_UB 1;
BA_ "U_CD4_MY13_Gas_Rx" SG_ 1076 TirePReset_B_Rq_UB 1;
BA_ "U_CD4_MY13_Hev_Rx" SG_ 1076 TirePReset_B_Rq_UB 1;
BA_ "U_CD4_MY13_Phev_Rx" SG_ 1076 TirePReset_B_Rq_UB 1;
BA_ "U_CD42_MY14_Diesel_Rx" SG_ 1076 TirePReset_B_Rq_UB 1;
BA_ "U_CD42_MY14_Gas_Rx" SG_ 1076 TirePReset_B_Rq_UB 1;
BA_ "U_P552_MY15_Gas_Rx" SG_ 1076 TirePReset_B_Rq_UB 1;
BA_ "U_S550_MY15_Gas_Rx" SG_ 1076 TirePReset_B_Rq_UB 1;
BA_ "U_C489_MY14_Gas_Rx" SG_ 1076 TirePReset_B_Rq_UB 1;
BA_ "U_U502_MY15_Gas_Rx" SG_ 1076 TirePReset_B_Rq_UB 1;
BA_ "U_UP375_MY15_Gas_Rx" SG_ 1076 TirePReset_B_Rq_UB 1;
BA_ "U_UP375_MY15_Diesel_Rx" SG_ 1076 TirePReset_B_Rq_UB 1;
BA_ "U_CD43_MY16_Gas_Rx" SG_ 1076 TirePReset_B_Rq_UB 1;
BA_ "U_CD4_MY14_Diesel_Rx" SG_ 1076 TirePReset_B_Rq_UB 1;
BA_ "U_CD4_MY14_Gas_Rx" SG_ 1076 TirePReset_B_Rq_UB 1;
BA_ "U_CD4_MY14_Hev_Rx" SG_ 1076 TirePReset_B_Rq_UB 1;
BA_ "U_CD4_MY14_Phev_Rx" SG_ 1076 TirePReset_B_Rq_UB 1;
BA_ "GenSigSendType" SG_ 1076 DrTGate_D_Rq 3;
BA_ "U_CD4_MY13_Diesel_Rx" SG_ 1076 DrTGate_D_Rq 1;
BA_ "U_CD4_MY13_Gas_Rx" SG_ 1076 DrTGate_D_Rq 1;
BA_ "U_CD4_MY13_Hev_Rx" SG_ 1076 DrTGate_D_Rq 1;
BA_ "U_CD4_MY13_Phev_Rx" SG_ 1076 DrTGate_D_Rq 1;
BA_ "U_CD42_MY14_Diesel_Rx" SG_ 1076 DrTGate_D_Rq 1;
BA_ "U_CD42_MY14_Gas_Rx" SG_ 1076 DrTGate_D_Rq 1;
BA_ "U_P552_MY15_Gas_Rx" SG_ 1076 DrTGate_D_Rq 1;
BA_ "U_S550_MY15_Gas_Rx" SG_ 1076 DrTGate_D_Rq 1;
BA_ "U_U502_MY15_Gas_Rx" SG_ 1076 DrTGate_D_Rq 1;
BA_ "U_CD43_MY16_Gas_Rx" SG_ 1076 DrTGate_D_Rq 1;
BA_ "U_CD4_MY14_Gas_Rx" SG_ 1076 DrTGate_D_Rq 1;
BA_ "U_C489_MY14_Gas_Rx" SG_ 1076 DrTGate_D_Rq 1;
BA_ "U_UP375_MY15_Gas_Rx" SG_ 1076 DrTGate_D_Rq 1;
BA_ "U_UP375_MY15_Diesel_Rx" SG_ 1076 DrTGate_D_Rq 1;
BA_ "U_CD4_MY14_Diesel_Rx" SG_ 1076 DrTGate_D_Rq 1;
BA_ "U_CD4_MY14_Hev_Rx" SG_ 1076 DrTGate_D_Rq 1;
BA_ "U_CD4_MY14_Phev_Rx" SG_ 1076 DrTGate_D_Rq 1;
BA_ "U_CD4_MY13_Diesel_Rx" SG_ 1076 DrTGate_D_Rq_UB 1;
BA_ "U_CD4_MY13_Gas_Rx" SG_ 1076 DrTGate_D_Rq_UB 1;
BA_ "U_CD4_MY13_Hev_Rx" SG_ 1076 DrTGate_D_Rq_UB 1;
BA_ "U_CD4_MY13_Phev_Rx" SG_ 1076 DrTGate_D_Rq_UB 1;
BA_ "U_CD42_MY14_Diesel_Rx" SG_ 1076 DrTGate_D_Rq_UB 1;
BA_ "U_CD42_MY14_Gas_Rx" SG_ 1076 DrTGate_D_Rq_UB 1;
BA_ "U_P552_MY15_Gas_Rx" SG_ 1076 DrTGate_D_Rq_UB 1;
BA_ "U_S550_MY15_Gas_Rx" SG_ 1076 DrTGate_D_Rq_UB 1;
BA_ "U_C489_MY14_Gas_Rx" SG_ 1076 DrTGate_D_Rq_UB 1;
BA_ "U_U502_MY15_Gas_Rx" SG_ 1076 DrTGate_D_Rq_UB 1;
BA_ "U_UP375_MY15_Gas_Rx" SG_ 1076 DrTGate_D_Rq_UB 1;
BA_ "U_UP375_MY15_Diesel_Rx" SG_ 1076 DrTGate_D_Rq_UB 1;
BA_ "U_CD43_MY16_Gas_Rx" SG_ 1076 DrTGate_D_Rq_UB 1;
BA_ "U_CD4_MY14_Diesel_Rx" SG_ 1076 DrTGate_D_Rq_UB 1;
BA_ "U_CD4_MY14_Gas_Rx" SG_ 1076 DrTGate_D_Rq_UB 1;
BA_ "U_CD4_MY14_Hev_Rx" SG_ 1076 DrTGate_D_Rq_UB 1;
BA_ "U_CD4_MY14_Phev_Rx" SG_ 1076 DrTGate_D_Rq_UB 1;
BA_ "CrossOver_InfoCAN" SG_ 1076 Veh_V_CompLimMx 1;
BA_ "GenSigStartValue" SG_ 1076 Veh_V_CompLimMx 4095;
BA_ "U_CD4_MY13_Gas_Rx" SG_ 1076 Veh_V_CompLimMx 1;
BA_ "U_CD42_MY14_Gas_Rx" SG_ 1076 Veh_V_CompLimMx 1;
BA_ "U_P552_MY15_Gas_Rx" SG_ 1076 Veh_V_CompLimMx 1;
BA_ "U_S550_MY15_Gas_Rx" SG_ 1076 Veh_V_CompLimMx 1;
BA_ "U_C489_MY14_Gas_Rx" SG_ 1076 Veh_V_CompLimMx 1;
BA_ "U_U502_MY15_Gas_Rx" SG_ 1076 Veh_V_CompLimMx 1;
BA_ "U_CD43_MY16_Gas_Rx" SG_ 1076 Veh_V_CompLimMx 1;
BA_ "U_CD4_MY14_Gas_Rx" SG_ 1076 Veh_V_CompLimMx 1;
BA_ "CrossOver_InfoCAN" SG_ 1076 DieslFuelBio_B_ActlDrv 1;
BA_ "GenSigSendType" SG_ 1076 DieslFuelBio_B_ActlDrv 3;
BA_ "CrossOver_InfoCAN" SG_ 1076 FuelSecndActv_B_Actl 1;
BA_ "GenSigSendType" SG_ 1076 FuelSecndActv_B_Actl 3;
BA_ "CrossOver_InfoCAN" SG_ 1076 FuelLvlPssvSide_No_Raw 1;
BA_ "U_CD4_MY13_Gas_Rx" SG_ 1076 FuelLvlPssvSide_No_Raw 1;
BA_ "U_CD42_MY14_Gas_Rx" SG_ 1076 FuelLvlPssvSide_No_Raw 1;
BA_ "U_P552_MY15_Gas_Rx" SG_ 1076 FuelLvlPssvSide_No_Raw 1;
BA_ "U_S550_MY15_Gas_Rx" SG_ 1076 FuelLvlPssvSide_No_Raw 1;
BA_ "U_C489_MY14_Gas_Rx" SG_ 1076 FuelLvlPssvSide_No_Raw 1;
BA_ "U_U502_MY15_Gas_Rx" SG_ 1076 FuelLvlPssvSide_No_Raw 1;
BA_ "U_CD43_MY16_Gas_Rx" SG_ 1076 FuelLvlPssvSide_No_Raw 1;
BA_ "U_CD4_MY14_Gas_Rx" SG_ 1076 FuelLvlPssvSide_No_Raw 1;
BA_ "CrossOver_InfoCAN" SG_ 1076 FUEL_SENSOR_NUM 1;
BA_ "GenSigSendType" SG_ 1076 FUEL_SENSOR_NUM 3;
BA_ "U_CD4_MY13_Gas_Rx" SG_ 1076 FUEL_SENSOR_NUM 1;
BA_ "U_CD42_MY14_Gas_Rx" SG_ 1076 FUEL_SENSOR_NUM 1;
BA_ "U_P552_MY15_Gas_Rx" SG_ 1076 FUEL_SENSOR_NUM 1;
BA_ "U_S550_MY15_Gas_Rx" SG_ 1076 FUEL_SENSOR_NUM 1;
BA_ "U_C489_MY14_Gas_Rx" SG_ 1076 FUEL_SENSOR_NUM 1;
BA_ "U_U502_MY15_Gas_Rx" SG_ 1076 FUEL_SENSOR_NUM 1;
BA_ "U_CD43_MY16_Gas_Rx" SG_ 1076 FUEL_SENSOR_NUM 1;
BA_ "U_CD4_MY14_Gas_Rx" SG_ 1076 FUEL_SENSOR_NUM 1;
BA_ "CrossOver_InfoCAN" SG_ 1076 FuelLvlActvSide_No_Raw 1;
BA_ "U_CD4_MY13_Gas_Rx" SG_ 1076 FuelLvlActvSide_No_Raw 1;
BA_ "U_CD42_MY14_Gas_Rx" SG_ 1076 FuelLvlActvSide_No_Raw 1;
BA_ "U_P552_MY15_Gas_Rx" SG_ 1076 FuelLvlActvSide_No_Raw 1;
BA_ "U_S550_MY15_Gas_Rx" SG_ 1076 FuelLvlActvSide_No_Raw 1;
BA_ "U_C489_MY14_Gas_Rx" SG_ 1076 FuelLvlActvSide_No_Raw 1;
BA_ "U_U502_MY15_Gas_Rx" SG_ 1076 FuelLvlActvSide_No_Raw 1;
BA_ "U_CD43_MY16_Gas_Rx" SG_ 1076 FuelLvlActvSide_No_Raw 1;
BA_ "U_CD4_MY14_Gas_Rx" SG_ 1076 FuelLvlActvSide_No_Raw 1;
BA_ "GenSigSendType" SG_ 1076 WndwPsngrSide_D_Stat 3;
BA_ "U_CD4_MY13_Gas_Rx" SG_ 1076 WndwPsngrSide_D_Stat 1;
BA_ "U_CD42_MY14_Gas_Rx" SG_ 1076 WndwPsngrSide_D_Stat 1;
BA_ "U_P552_MY15_Gas_Rx" SG_ 1076 WndwPsngrSide_D_Stat 1;
BA_ "U_U502_MY15_Gas_Rx" SG_ 1076 WndwPsngrSide_D_Stat 1;
BA_ "U_CD43_MY16_Gas_Rx" SG_ 1076 WndwPsngrSide_D_Stat 1;
BA_ "U_CD4_MY14_Gas_Rx" SG_ 1076 WndwPsngrSide_D_Stat 1;
BA_ "GenSigSendType" SG_ 1076 WndwDrvSide_D_Stat 3;
BA_ "U_CD4_MY13_Gas_Rx" SG_ 1076 WndwDrvSide_D_Stat 1;
BA_ "U_CD42_MY14_Gas_Rx" SG_ 1076 WndwDrvSide_D_Stat 1;
BA_ "U_P552_MY15_Gas_Rx" SG_ 1076 WndwDrvSide_D_Stat 1;
BA_ "U_U502_MY15_Gas_Rx" SG_ 1076 WndwDrvSide_D_Stat 1;
BA_ "U_CD43_MY16_Gas_Rx" SG_ 1076 WndwDrvSide_D_Stat 1;
BA_ "U_CD4_MY14_Gas_Rx" SG_ 1076 WndwDrvSide_D_Stat 1;
BA_ "U_CD4_MY13_Gas_Rx" SG_ 1076 WndwPsngrSide_D_Stat_UB 1;
BA_ "U_CD42_MY14_Gas_Rx" SG_ 1076 WndwPsngrSide_D_Stat_UB 1;
BA_ "U_P552_MY15_Gas_Rx" SG_ 1076 WndwPsngrSide_D_Stat_UB 1;
BA_ "U_U502_MY15_Gas_Rx" SG_ 1076 WndwPsngrSide_D_Stat_UB 1;
BA_ "U_CD43_MY16_Gas_Rx" SG_ 1076 WndwPsngrSide_D_Stat_UB 1;
BA_ "U_CD4_MY14_Gas_Rx" SG_ 1076 WndwPsngrSide_D_Stat_UB 1;
BA_ "CrossOver_InfoCAN" SG_ 1076 DISPLAY_SPEED_SCALING 1;
BA_ "U_CD4_MY13_Gas_Rx" SG_ 1076 DISPLAY_SPEED_SCALING 1;
BA_ "U_CD42_MY14_Gas_Rx" SG_ 1076 DISPLAY_SPEED_SCALING 1;
BA_ "U_P552_MY15_Gas_Rx" SG_ 1076 DISPLAY_SPEED_SCALING 1;
BA_ "U_S550_MY15_Gas_Rx" SG_ 1076 DISPLAY_SPEED_SCALING 1;
BA_ "U_C489_MY14_Gas_Rx" SG_ 1076 DISPLAY_SPEED_SCALING 1;
BA_ "U_U502_MY15_Gas_Rx" SG_ 1076 DISPLAY_SPEED_SCALING 1;
BA_ "U_CD43_MY16_Gas_Rx" SG_ 1076 DISPLAY_SPEED_SCALING 1;
BA_ "U_CD4_MY14_Gas_Rx" SG_ 1076 DISPLAY_SPEED_SCALING 1;
BA_ "CrossOver_InfoCAN" SG_ 1076 DISPLAY_SPEED_OFFSET 1;
BA_ "U_CD4_MY13_Gas_Rx" SG_ 1076 DISPLAY_SPEED_OFFSET 1;
BA_ "U_CD42_MY14_Gas_Rx" SG_ 1076 DISPLAY_SPEED_OFFSET 1;
BA_ "U_P552_MY15_Gas_Rx" SG_ 1076 DISPLAY_SPEED_OFFSET 1;
BA_ "U_S550_MY15_Gas_Rx" SG_ 1076 DISPLAY_SPEED_OFFSET 1;
BA_ "U_C489_MY14_Gas_Rx" SG_ 1076 DISPLAY_SPEED_OFFSET 1;
BA_ "U_U502_MY15_Gas_Rx" SG_ 1076 DISPLAY_SPEED_OFFSET 1;
BA_ "U_CD43_MY16_Gas_Rx" SG_ 1076 DISPLAY_SPEED_OFFSET 1;
BA_ "U_CD4_MY14_Gas_Rx" SG_ 1076 DISPLAY_SPEED_OFFSET 1;
BA_ "U_CD4_MY13_Gas_Rx" SG_ 1076 WndwDrvSide_D_Stat_UB 1;
BA_ "U_CD42_MY14_Gas_Rx" SG_ 1076 WndwDrvSide_D_Stat_UB 1;
BA_ "U_P552_MY15_Gas_Rx" SG_ 1076 WndwDrvSide_D_Stat_UB 1;
BA_ "U_U502_MY15_Gas_Rx" SG_ 1076 WndwDrvSide_D_Stat_UB 1;
BA_ "U_CD43_MY16_Gas_Rx" SG_ 1076 WndwDrvSide_D_Stat_UB 1;
BA_ "U_CD4_MY14_Gas_Rx" SG_ 1076 WndwDrvSide_D_Stat_UB 1;
BA_ "CrossOver_InfoCAN" SG_ 1076 TirePReset_B_Rq 1;
BA_ "GenSigSendType" SG_ 1076 TirePReset_B_Rq 3;
BA_ "U_CD4_MY13_Diesel_Rx" SG_ 1076 TirePReset_B_Rq 1;
BA_ "U_CD4_MY13_Gas_Rx" SG_ 1076 TirePReset_B_Rq 1;
BA_ "U_CD4_MY13_Hev_Rx" SG_ 1076 TirePReset_B_Rq 1;
BA_ "U_CD4_MY13_Phev_Rx" SG_ 1076 TirePReset_B_Rq 1;
BA_ "U_CD42_MY14_Diesel_Rx" SG_ 1076 TirePReset_B_Rq 1;
BA_ "U_CD42_MY14_Gas_Rx" SG_ 1076 TirePReset_B_Rq 1;
BA_ "U_P552_MY15_Gas_Rx" SG_ 1076 TirePReset_B_Rq 1;
BA_ "U_S550_MY15_Gas_Rx" SG_ 1076 TirePReset_B_Rq 1;
BA_ "U_C489_MY14_Gas_Rx" SG_ 1076 TirePReset_B_Rq 1;
BA_ "U_U502_MY15_Gas_Rx" SG_ 1076 TirePReset_B_Rq 1;
BA_ "U_UP375_MY15_Gas_Rx" SG_ 1076 TirePReset_B_Rq 1;
BA_ "U_UP375_MY15_Diesel_Rx" SG_ 1076 TirePReset_B_Rq 1;
BA_ "U_CD43_MY16_Gas_Rx" SG_ 1076 TirePReset_B_Rq 1;
BA_ "U_CD4_MY14_Diesel_Rx" SG_ 1076 TirePReset_B_Rq 1;
BA_ "U_CD4_MY14_Gas_Rx" SG_ 1076 TirePReset_B_Rq 1;
BA_ "U_CD4_MY14_Hev_Rx" SG_ 1076 TirePReset_B_Rq 1;
BA_ "U_CD4_MY14_Phev_Rx" SG_ 1076 TirePReset_B_Rq 1;
BA_ "U_CD4_MY13_Gas_Tx" SG_ 1072 DrvPerfMde_D_Rq_UB 1;
BA_ "U_CD4_MY13_Hev_Tx" SG_ 1072 DrvPerfMde_D_Rq_UB 1;
BA_ "GenSigSendType" SG_ 1072 DrvPerfMde_D_Rq 3;
BA_ "U_CD4_MY13_Gas_Tx" SG_ 1072 DrvPerfMde_D_Rq 1;
BA_ "U_CD4_MY13_Hev_Tx" SG_ 1072 DrvPerfMde_D_Rq 1;
BA_ "U_CD4_MY13_Diesel_Rx" SG_ 1072 ePRNDL_MODE_UB 1;
BA_ "U_CD4_MY13_Gas_Rx" SG_ 1072 ePRNDL_MODE_UB 1;
BA_ "U_CD4_MY13_Hev_Rx" SG_ 1072 ePRNDL_MODE_UB 1;
BA_ "U_CD4_MY13_Phev_Rx" SG_ 1072 ePRNDL_MODE_UB 1;
BA_ "U_CD42_MY14_Diesel_Rx" SG_ 1072 ePRNDL_MODE_UB 1;
BA_ "U_CD42_MY14_Gas_Rx" SG_ 1072 ePRNDL_MODE_UB 1;
BA_ "U_P552_MY15_Gas_Rx" SG_ 1072 ePRNDL_MODE_UB 1;
BA_ "U_S550_MY15_Gas_Rx" SG_ 1072 ePRNDL_MODE_UB 1;
BA_ "U_C489_MY14_Gas_Rx" SG_ 1072 ePRNDL_MODE_UB 1;
BA_ "U_U502_MY15_Gas_Rx" SG_ 1072 ePRNDL_MODE_UB 1;
BA_ "U_UP375_MY15_Gas_Rx" SG_ 1072 ePRNDL_MODE_UB 1;
BA_ "U_UP375_MY15_Diesel_Rx" SG_ 1072 ePRNDL_MODE_UB 1;
BA_ "U_CD43_MY16_Gas_Rx" SG_ 1072 ePRNDL_MODE_UB 1;
BA_ "U_CD4_MY14_Diesel_Rx" SG_ 1072 ePRNDL_MODE_UB 1;
BA_ "U_CD4_MY14_Gas_Rx" SG_ 1072 ePRNDL_MODE_UB 1;
BA_ "U_CD4_MY14_Hev_Rx" SG_ 1072 ePRNDL_MODE_UB 1;
BA_ "U_CD4_MY14_Phev_Rx" SG_ 1072 ePRNDL_MODE_UB 1;
BA_ "GenSigTimeoutTime_TCM" SG_ 1072 ePRNDL_MODE_UB 300;
BA_ "CrossOver_InfoCAN" SG_ 1072 NtrlTowMdeEnbl_B_RqDrv 1;
BA_ "GenSigSendType" SG_ 1072 NtrlTowMdeEnbl_B_RqDrv 3;
BA_ "U_CD4_MY13_Diesel_Rx" SG_ 1072 Remote_Start_QuietMode_UB 1;
BA_ "U_CD4_MY13_Gas_Rx" SG_ 1072 Remote_Start_QuietMode_UB 1;
BA_ "U_CD4_MY13_Hev_Rx" SG_ 1072 Remote_Start_QuietMode_UB 1;
BA_ "U_CD4_MY13_Phev_Rx" SG_ 1072 Remote_Start_QuietMode_UB 1;
BA_ "U_CD42_MY14_Diesel_Rx" SG_ 1072 Remote_Start_QuietMode_UB 1;
BA_ "U_CD42_MY14_Gas_Rx" SG_ 1072 Remote_Start_QuietMode_UB 1;
BA_ "U_P552_MY15_Gas_Rx" SG_ 1072 Remote_Start_QuietMode_UB 1;
BA_ "U_S550_MY15_Gas_Rx" SG_ 1072 Remote_Start_QuietMode_UB 1;
BA_ "U_C489_MY14_Gas_Rx" SG_ 1072 Remote_Start_QuietMode_UB 1;
BA_ "U_U502_MY15_Gas_Rx" SG_ 1072 Remote_Start_QuietMode_UB 1;
BA_ "U_UP375_MY15_Gas_Rx" SG_ 1072 Remote_Start_QuietMode_UB 1;
BA_ "U_UP375_MY15_Diesel_Rx" SG_ 1072 Remote_Start_QuietMode_UB 1;
BA_ "U_CD43_MY16_Gas_Rx" SG_ 1072 Remote_Start_QuietMode_UB 1;
BA_ "U_CD4_MY14_Diesel_Rx" SG_ 1072 Remote_Start_QuietMode_UB 1;
BA_ "U_CD4_MY14_Gas_Rx" SG_ 1072 Remote_Start_QuietMode_UB 1;
BA_ "U_CD4_MY14_Hev_Rx" SG_ 1072 Remote_Start_QuietMode_UB 1;
BA_ "U_CD4_MY14_Phev_Rx" SG_ 1072 Remote_Start_QuietMode_UB 1;
BA_ "GenSigSendType" SG_ 1072 Remote_Start_QuietMode 3;
BA_ "U_CD4_MY13_Diesel_Rx" SG_ 1072 Remote_Start_QuietMode 1;
BA_ "U_CD4_MY13_Gas_Rx" SG_ 1072 Remote_Start_QuietMode 1;
BA_ "U_CD4_MY13_Hev_Rx" SG_ 1072 Remote_Start_QuietMode 1;
BA_ "U_CD4_MY13_Phev_Rx" SG_ 1072 Remote_Start_QuietMode 1;
BA_ "U_CD42_MY14_Diesel_Rx" SG_ 1072 Remote_Start_QuietMode 1;
BA_ "U_CD42_MY14_Gas_Rx" SG_ 1072 Remote_Start_QuietMode 1;
BA_ "U_P552_MY15_Gas_Rx" SG_ 1072 Remote_Start_QuietMode 1;
BA_ "U_S550_MY15_Gas_Rx" SG_ 1072 Remote_Start_QuietMode 1;
BA_ "U_C489_MY14_Gas_Rx" SG_ 1072 Remote_Start_QuietMode 1;
BA_ "U_U502_MY15_Gas_Rx" SG_ 1072 Remote_Start_QuietMode 1;
BA_ "U_UP375_MY15_Gas_Rx" SG_ 1072 Remote_Start_QuietMode 1;
BA_ "U_UP375_MY15_Diesel_Rx" SG_ 1072 Remote_Start_QuietMode 1;
BA_ "U_CD43_MY16_Gas_Rx" SG_ 1072 Remote_Start_QuietMode 1;
BA_ "U_CD4_MY14_Diesel_Rx" SG_ 1072 Remote_Start_QuietMode 1;
BA_ "U_CD4_MY14_Gas_Rx" SG_ 1072 Remote_Start_QuietMode 1;
BA_ "U_CD4_MY14_Hev_Rx" SG_ 1072 Remote_Start_QuietMode 1;
BA_ "U_CD4_MY14_Phev_Rx" SG_ 1072 Remote_Start_QuietMode 1;
BA_ "U_CD4_MY13_Diesel_Rx" SG_ 1072 ParkDetect_Stat_UB 1;
BA_ "U_CD4_MY13_Gas_Rx" SG_ 1072 ParkDetect_Stat_UB 1;
BA_ "U_CD4_MY13_Hev_Rx" SG_ 1072 ParkDetect_Stat_UB 1;
BA_ "U_CD4_MY13_Phev_Rx" SG_ 1072 ParkDetect_Stat_UB 1;
BA_ "U_CD42_MY14_Diesel_Rx" SG_ 1072 ParkDetect_Stat_UB 1;
BA_ "U_CD42_MY14_Gas_Rx" SG_ 1072 ParkDetect_Stat_UB 1;
BA_ "U_P552_MY15_Gas_Rx" SG_ 1072 ParkDetect_Stat_UB 1;
BA_ "U_S550_MY15_Gas_Rx" SG_ 1072 ParkDetect_Stat_UB 1;
BA_ "U_C489_MY14_Gas_Rx" SG_ 1072 ParkDetect_Stat_UB 1;
BA_ "U_U502_MY15_Gas_Rx" SG_ 1072 ParkDetect_Stat_UB 1;
BA_ "U_UP375_MY15_Gas_Rx" SG_ 1072 ParkDetect_Stat_UB 1;
BA_ "U_UP375_MY15_Diesel_Rx" SG_ 1072 ParkDetect_Stat_UB 1;
BA_ "U_CD43_MY16_Gas_Rx" SG_ 1072 ParkDetect_Stat_UB 1;
BA_ "U_CD4_MY14_Diesel_Rx" SG_ 1072 ParkDetect_Stat_UB 1;
BA_ "U_CD4_MY14_Gas_Rx" SG_ 1072 ParkDetect_Stat_UB 1;
BA_ "U_CD4_MY14_Hev_Rx" SG_ 1072 ParkDetect_Stat_UB 1;
BA_ "U_CD4_MY14_Phev_Rx" SG_ 1072 ParkDetect_Stat_UB 1;
BA_ "CrossOver_InfoCAN" SG_ 1072 ParkDetect_Stat 1;
BA_ "GenSigSendType" SG_ 1072 ParkDetect_Stat 3;
BA_ "U_CD4_MY13_Diesel_Rx" SG_ 1072 ParkDetect_Stat 1;
BA_ "U_CD4_MY13_Gas_Rx" SG_ 1072 ParkDetect_Stat 1;
BA_ "U_CD4_MY13_Hev_Rx" SG_ 1072 ParkDetect_Stat 1;
BA_ "U_CD4_MY13_Phev_Rx" SG_ 1072 ParkDetect_Stat 1;
BA_ "U_CD42_MY14_Diesel_Rx" SG_ 1072 ParkDetect_Stat 1;
BA_ "U_CD42_MY14_Gas_Rx" SG_ 1072 ParkDetect_Stat 1;
BA_ "U_P552_MY15_Gas_Rx" SG_ 1072 ParkDetect_Stat 1;
BA_ "U_S550_MY15_Gas_Rx" SG_ 1072 ParkDetect_Stat 1;
BA_ "U_C489_MY14_Gas_Rx" SG_ 1072 ParkDetect_Stat 1;
BA_ "U_U502_MY15_Gas_Rx" SG_ 1072 ParkDetect_Stat 1;
BA_ "U_UP375_MY15_Gas_Rx" SG_ 1072 ParkDetect_Stat 1;
BA_ "U_UP375_MY15_Diesel_Rx" SG_ 1072 ParkDetect_Stat 1;
BA_ "U_CD43_MY16_Gas_Rx" SG_ 1072 ParkDetect_Stat 1;
BA_ "U_CD4_MY14_Diesel_Rx" SG_ 1072 ParkDetect_Stat 1;
BA_ "U_CD4_MY14_Gas_Rx" SG_ 1072 ParkDetect_Stat 1;
BA_ "U_CD4_MY14_Hev_Rx" SG_ 1072 ParkDetect_Stat 1;
BA_ "U_CD4_MY14_Phev_Rx" SG_ 1072 ParkDetect_Stat 1;
BA_ "U_CD4_MY13_Diesel_Rx" SG_ 1072 TrlrLampCnnct_B_Actl_UB 1;
BA_ "U_CD4_MY13_Gas_Rx" SG_ 1072 TrlrLampCnnct_B_Actl_UB 1;
BA_ "U_CD4_MY13_Hev_Rx" SG_ 1072 TrlrLampCnnct_B_Actl_UB 1;
BA_ "U_CD4_MY13_Phev_Rx" SG_ 1072 TrlrLampCnnct_B_Actl_UB 1;
BA_ "U_CD42_MY14_Diesel_Rx" SG_ 1072 TrlrLampCnnct_B_Actl_UB 1;
BA_ "U_CD42_MY14_Gas_Rx" SG_ 1072 TrlrLampCnnct_B_Actl_UB 1;
BA_ "U_P552_MY15_Gas_Rx" SG_ 1072 TrlrLampCnnct_B_Actl_UB 1;
BA_ "U_S550_MY15_Gas_Rx" SG_ 1072 TrlrLampCnnct_B_Actl_UB 1;
BA_ "U_C489_MY14_Gas_Rx" SG_ 1072 TrlrLampCnnct_B_Actl_UB 1;
BA_ "U_U502_MY15_Gas_Rx" SG_ 1072 TrlrLampCnnct_B_Actl_UB 1;
BA_ "U_UP375_MY15_Gas_Rx" SG_ 1072 TrlrLampCnnct_B_Actl_UB 1;
BA_ "U_UP375_MY15_Diesel_Rx" SG_ 1072 TrlrLampCnnct_B_Actl_UB 1;
BA_ "U_CD43_MY16_Gas_Rx" SG_ 1072 TrlrLampCnnct_B_Actl_UB 1;
BA_ "U_CD4_MY14_Diesel_Rx" SG_ 1072 TrlrLampCnnct_B_Actl_UB 1;
BA_ "U_CD4_MY14_Gas_Rx" SG_ 1072 TrlrLampCnnct_B_Actl_UB 1;
BA_ "U_CD4_MY14_Hev_Rx" SG_ 1072 TrlrLampCnnct_B_Actl_UB 1;
BA_ "U_CD4_MY14_Phev_Rx" SG_ 1072 TrlrLampCnnct_B_Actl_UB 1;
BA_ "U_CD4_MY13_Diesel_Rx" SG_ 1072 StopLamp_B_RqTrlrBrk_UB 1;
BA_ "U_CD4_MY13_Gas_Rx" SG_ 1072 StopLamp_B_RqTrlrBrk_UB 1;
BA_ "U_CD4_MY13_Hev_Rx" SG_ 1072 StopLamp_B_RqTrlrBrk_UB 1;
BA_ "U_CD4_MY13_Phev_Rx" SG_ 1072 StopLamp_B_RqTrlrBrk_UB 1;
BA_ "U_CD42_MY14_Diesel_Rx" SG_ 1072 StopLamp_B_RqTrlrBrk_UB 1;
BA_ "U_CD42_MY14_Gas_Rx" SG_ 1072 StopLamp_B_RqTrlrBrk_UB 1;
BA_ "U_P552_MY15_Gas_Rx" SG_ 1072 StopLamp_B_RqTrlrBrk_UB 1;
BA_ "U_S550_MY15_Gas_Rx" SG_ 1072 StopLamp_B_RqTrlrBrk_UB 1;
BA_ "U_C489_MY14_Gas_Rx" SG_ 1072 StopLamp_B_RqTrlrBrk_UB 1;
BA_ "U_U502_MY15_Gas_Rx" SG_ 1072 StopLamp_B_RqTrlrBrk_UB 1;
BA_ "U_UP375_MY15_Gas_Rx" SG_ 1072 StopLamp_B_RqTrlrBrk_UB 1;
BA_ "U_UP375_MY15_Diesel_Rx" SG_ 1072 StopLamp_B_RqTrlrBrk_UB 1;
BA_ "U_CD43_MY16_Gas_Rx" SG_ 1072 StopLamp_B_RqTrlrBrk_UB 1;
BA_ "U_CD4_MY14_Diesel_Rx" SG_ 1072 StopLamp_B_RqTrlrBrk_UB 1;
BA_ "U_CD4_MY14_Gas_Rx" SG_ 1072 StopLamp_B_RqTrlrBrk_UB 1;
BA_ "U_CD4_MY14_Hev_Rx" SG_ 1072 StopLamp_B_RqTrlrBrk_UB 1;
BA_ "U_CD4_MY14_Phev_Rx" SG_ 1072 StopLamp_B_RqTrlrBrk_UB 1;
BA_ "ContentDependant" SG_ 1072 StopLamp_B_RqTrlrBrk 1;
BA_ "GenSigSendType" SG_ 1072 StopLamp_B_RqTrlrBrk 3;
BA_ "U_CD4_MY13_Diesel_Rx" SG_ 1072 StopLamp_B_RqTrlrBrk 1;
BA_ "U_CD4_MY13_Gas_Rx" SG_ 1072 StopLamp_B_RqTrlrBrk 1;
BA_ "U_CD4_MY13_Hev_Rx" SG_ 1072 StopLamp_B_RqTrlrBrk 1;
BA_ "U_CD4_MY13_Phev_Rx" SG_ 1072 StopLamp_B_RqTrlrBrk 1;
BA_ "U_CD42_MY14_Diesel_Rx" SG_ 1072 StopLamp_B_RqTrlrBrk 1;
BA_ "U_CD42_MY14_Gas_Rx" SG_ 1072 StopLamp_B_RqTrlrBrk 1;
BA_ "U_P552_MY15_Gas_Rx" SG_ 1072 StopLamp_B_RqTrlrBrk 1;
BA_ "U_S550_MY15_Gas_Rx" SG_ 1072 StopLamp_B_RqTrlrBrk 1;
BA_ "U_C489_MY14_Gas_Rx" SG_ 1072 StopLamp_B_RqTrlrBrk 1;
BA_ "U_U502_MY15_Gas_Rx" SG_ 1072 StopLamp_B_RqTrlrBrk 1;
BA_ "U_UP375_MY15_Gas_Rx" SG_ 1072 StopLamp_B_RqTrlrBrk 1;
BA_ "U_UP375_MY15_Diesel_Rx" SG_ 1072 StopLamp_B_RqTrlrBrk 1;
BA_ "U_CD43_MY16_Gas_Rx" SG_ 1072 StopLamp_B_RqTrlrBrk 1;
BA_ "U_CD4_MY14_Diesel_Rx" SG_ 1072 StopLamp_B_RqTrlrBrk 1;
BA_ "U_CD4_MY14_Gas_Rx" SG_ 1072 StopLamp_B_RqTrlrBrk 1;
BA_ "U_CD4_MY14_Hev_Rx" SG_ 1072 StopLamp_B_RqTrlrBrk 1;
BA_ "U_CD4_MY14_Phev_Rx" SG_ 1072 StopLamp_B_RqTrlrBrk 1;
BA_ "U_CD4_MY13_Diesel_Rx" SG_ 1072 OdometerMasterValue_UB 1;
BA_ "U_CD4_MY13_Gas_Rx" SG_ 1072 OdometerMasterValue_UB 1;
BA_ "U_CD4_MY13_Hev_Rx" SG_ 1072 OdometerMasterValue_UB 1;
BA_ "U_CD4_MY13_Phev_Rx" SG_ 1072 OdometerMasterValue_UB 1;
BA_ "U_CD42_MY14_Diesel_Rx" SG_ 1072 OdometerMasterValue_UB 1;
BA_ "U_CD42_MY14_Gas_Rx" SG_ 1072 OdometerMasterValue_UB 1;
BA_ "U_P552_MY15_Gas_Rx" SG_ 1072 OdometerMasterValue_UB 1;
BA_ "U_S550_MY15_Gas_Rx" SG_ 1072 OdometerMasterValue_UB 1;
BA_ "U_C489_MY14_Gas_Rx" SG_ 1072 OdometerMasterValue_UB 1;
BA_ "U_U502_MY15_Gas_Rx" SG_ 1072 OdometerMasterValue_UB 1;
BA_ "U_UP375_MY15_Gas_Rx" SG_ 1072 OdometerMasterValue_UB 1;
BA_ "U_UP375_MY15_Diesel_Rx" SG_ 1072 OdometerMasterValue_UB 1;
BA_ "U_CD43_MY16_Gas_Rx" SG_ 1072 OdometerMasterValue_UB 1;
BA_ "U_CD4_MY14_Diesel_Rx" SG_ 1072 OdometerMasterValue_UB 1;
BA_ "U_CD4_MY14_Gas_Rx" SG_ 1072 OdometerMasterValue_UB 1;
BA_ "U_CD4_MY14_Hev_Rx" SG_ 1072 OdometerMasterValue_UB 1;
BA_ "U_CD4_MY14_Phev_Rx" SG_ 1072 OdometerMasterValue_UB 1;
BA_ "CrossOver_InfoCAN" SG_ 1072 OdometerMasterValue 1;
BA_ "GenSigSendType" SG_ 1072 OdometerMasterValue 3;
BA_ "U_CD4_MY13_Diesel_Rx" SG_ 1072 OdometerMasterValue 1;
BA_ "U_CD4_MY13_Gas_Rx" SG_ 1072 OdometerMasterValue 1;
BA_ "U_CD4_MY13_Hev_Rx" SG_ 1072 OdometerMasterValue 1;
BA_ "U_CD4_MY13_Phev_Rx" SG_ 1072 OdometerMasterValue 1;
BA_ "U_CD42_MY14_Diesel_Rx" SG_ 1072 OdometerMasterValue 1;
BA_ "U_CD42_MY14_Gas_Rx" SG_ 1072 OdometerMasterValue 1;
BA_ "U_P552_MY15_Gas_Rx" SG_ 1072 OdometerMasterValue 1;
BA_ "U_S550_MY15_Gas_Rx" SG_ 1072 OdometerMasterValue 1;
BA_ "U_C489_MY14_Gas_Rx" SG_ 1072 OdometerMasterValue 1;
BA_ "U_U502_MY15_Gas_Rx" SG_ 1072 OdometerMasterValue 1;
BA_ "U_CD43_MY16_Gas_Rx" SG_ 1072 OdometerMasterValue 1;
BA_ "U_CD4_MY14_Gas_Rx" SG_ 1072 OdometerMasterValue 1;
BA_ "U_UP375_MY15_Gas_Rx" SG_ 1072 OdometerMasterValue 1;
BA_ "U_UP375_MY15_Diesel_Rx" SG_ 1072 OdometerMasterValue 1;
BA_ "U_CD4_MY14_Diesel_Rx" SG_ 1072 OdometerMasterValue 1;
BA_ "U_CD4_MY14_Hev_Rx" SG_ 1072 OdometerMasterValue 1;
BA_ "U_CD4_MY14_Phev_Rx" SG_ 1072 OdometerMasterValue 1;
BA_ "GenSigTimeoutTime_TCM" SG_ 1072 OdometerMasterValue 300;
BA_ "CrossOver_InfoCAN" SG_ 1072 MetricActv_B_Actl 1;
BA_ "GenSigSendType" SG_ 1072 MetricActv_B_Actl 3;
BA_ "U_CD4_MY13_Gas_Rx" SG_ 1072 MetricActv_B_Actl 1;
BA_ "U_CD42_MY14_Gas_Rx" SG_ 1072 MetricActv_B_Actl 1;
BA_ "U_P552_MY15_Gas_Rx" SG_ 1072 MetricActv_B_Actl 1;
BA_ "U_S550_MY15_Gas_Rx" SG_ 1072 MetricActv_B_Actl 1;
BA_ "U_C489_MY14_Gas_Rx" SG_ 1072 MetricActv_B_Actl 1;
BA_ "U_U502_MY15_Gas_Rx" SG_ 1072 MetricActv_B_Actl 1;
BA_ "U_CD43_MY16_Gas_Rx" SG_ 1072 MetricActv_B_Actl 1;
BA_ "U_CD4_MY14_Gas_Rx" SG_ 1072 MetricActv_B_Actl 1;
BA_ "CrossOver_InfoCAN" SG_ 1072 FrostWarn_D_Stat 1;
BA_ "GenSigSendType" SG_ 1072 FrostWarn_D_Stat 3;
BA_ "U_CD4_MY13_Gas_Rx" SG_ 1072 FrostWarn_D_Stat 1;
BA_ "U_CD42_MY14_Gas_Rx" SG_ 1072 FrostWarn_D_Stat 1;
BA_ "U_P552_MY15_Gas_Rx" SG_ 1072 FrostWarn_D_Stat 1;
BA_ "U_U502_MY15_Gas_Rx" SG_ 1072 FrostWarn_D_Stat 1;
BA_ "U_CD43_MY16_Gas_Rx" SG_ 1072 FrostWarn_D_Stat 1;
BA_ "U_CD4_MY14_Gas_Rx" SG_ 1072 FrostWarn_D_Stat 1;
BA_ "U_CD4_MY13_Diesel_Rx" SG_ 1072 ReducedGuard_D_Rq_UB 1;
BA_ "U_CD4_MY13_Gas_Rx" SG_ 1072 ReducedGuard_D_Rq_UB 1;
BA_ "U_CD4_MY13_Hev_Rx" SG_ 1072 ReducedGuard_D_Rq_UB 1;
BA_ "U_CD4_MY13_Phev_Rx" SG_ 1072 ReducedGuard_D_Rq_UB 1;
BA_ "U_CD42_MY14_Diesel_Rx" SG_ 1072 ReducedGuard_D_Rq_UB 1;
BA_ "U_CD42_MY14_Gas_Rx" SG_ 1072 ReducedGuard_D_Rq_UB 1;
BA_ "U_P552_MY15_Gas_Rx" SG_ 1072 ReducedGuard_D_Rq_UB 1;
BA_ "U_S550_MY15_Gas_Rx" SG_ 1072 ReducedGuard_D_Rq_UB 1;
BA_ "U_C489_MY14_Gas_Rx" SG_ 1072 ReducedGuard_D_Rq_UB 1;
BA_ "U_U502_MY15_Gas_Rx" SG_ 1072 ReducedGuard_D_Rq_UB 1;
BA_ "U_UP375_MY15_Gas_Rx" SG_ 1072 ReducedGuard_D_Rq_UB 1;
BA_ "U_UP375_MY15_Diesel_Rx" SG_ 1072 ReducedGuard_D_Rq_UB 1;
BA_ "U_CD43_MY16_Gas_Rx" SG_ 1072 ReducedGuard_D_Rq_UB 1;
BA_ "U_CD4_MY14_Diesel_Rx" SG_ 1072 ReducedGuard_D_Rq_UB 1;
BA_ "U_CD4_MY14_Gas_Rx" SG_ 1072 ReducedGuard_D_Rq_UB 1;
BA_ "U_CD4_MY14_Hev_Rx" SG_ 1072 ReducedGuard_D_Rq_UB 1;
BA_ "U_CD4_MY14_Phev_Rx" SG_ 1072 ReducedGuard_D_Rq_UB 1;
BA_ "CrossOver_InfoCAN" SG_ 1072 ReducedGuard_D_Rq 1;
BA_ "GenSigSendType" SG_ 1072 ReducedGuard_D_Rq 3;
BA_ "U_CD4_MY13_Diesel_Rx" SG_ 1072 ReducedGuard_D_Rq 1;
BA_ "U_CD4_MY13_Gas_Rx" SG_ 1072 ReducedGuard_D_Rq 1;
BA_ "U_CD4_MY13_Hev_Rx" SG_ 1072 ReducedGuard_D_Rq 1;
BA_ "U_CD4_MY13_Phev_Rx" SG_ 1072 ReducedGuard_D_Rq 1;
BA_ "U_CD42_MY14_Diesel_Rx" SG_ 1072 ReducedGuard_D_Rq 1;
BA_ "U_CD42_MY14_Gas_Rx" SG_ 1072 ReducedGuard_D_Rq 1;
BA_ "U_P552_MY15_Gas_Rx" SG_ 1072 ReducedGuard_D_Rq 1;
BA_ "U_S550_MY15_Gas_Rx" SG_ 1072 ReducedGuard_D_Rq 1;
BA_ "U_C489_MY14_Gas_Rx" SG_ 1072 ReducedGuard_D_Rq 1;
BA_ "U_U502_MY15_Gas_Rx" SG_ 1072 ReducedGuard_D_Rq 1;
BA_ "U_UP375_MY15_Gas_Rx" SG_ 1072 ReducedGuard_D_Rq 1;
BA_ "U_UP375_MY15_Diesel_Rx" SG_ 1072 ReducedGuard_D_Rq 1;
BA_ "U_CD43_MY16_Gas_Rx" SG_ 1072 ReducedGuard_D_Rq 1;
BA_ "U_CD4_MY14_Diesel_Rx" SG_ 1072 ReducedGuard_D_Rq 1;
BA_ "U_CD4_MY14_Gas_Rx" SG_ 1072 ReducedGuard_D_Rq 1;
BA_ "U_CD4_MY14_Hev_Rx" SG_ 1072 ReducedGuard_D_Rq 1;
BA_ "U_CD4_MY14_Phev_Rx" SG_ 1072 ReducedGuard_D_Rq 1;
BA_ "WakeupSignal" SG_ 1072 ePRNDL_MODE 1;
BA_ "CrossOver_InfoCAN" SG_ 1072 ePRNDL_MODE 1;
BA_ "GenSigSendType" SG_ 1072 ePRNDL_MODE 3;
BA_ "U_CD4_MY13_Diesel_Rx" SG_ 1072 ePRNDL_MODE 1;
BA_ "U_CD4_MY13_Gas_Rx" SG_ 1072 ePRNDL_MODE 1;
BA_ "U_CD4_MY13_Hev_Rx" SG_ 1072 ePRNDL_MODE 1;
BA_ "U_CD4_MY13_Phev_Rx" SG_ 1072 ePRNDL_MODE 1;
BA_ "U_CD42_MY14_Diesel_Rx" SG_ 1072 ePRNDL_MODE 1;
BA_ "U_CD42_MY14_Gas_Rx" SG_ 1072 ePRNDL_MODE 1;
BA_ "U_P552_MY15_Gas_Rx" SG_ 1072 ePRNDL_MODE 1;
BA_ "U_S550_MY15_Gas_Rx" SG_ 1072 ePRNDL_MODE 1;
BA_ "U_C489_MY14_Gas_Rx" SG_ 1072 ePRNDL_MODE 1;
BA_ "U_U502_MY15_Gas_Rx" SG_ 1072 ePRNDL_MODE 1;
BA_ "U_CD43_MY16_Gas_Rx" SG_ 1072 ePRNDL_MODE 1;
BA_ "U_CD4_MY14_Gas_Rx" SG_ 1072 ePRNDL_MODE 1;
BA_ "U_UP375_MY15_Gas_Rx" SG_ 1072 ePRNDL_MODE 1;
BA_ "U_UP375_MY15_Diesel_Rx" SG_ 1072 ePRNDL_MODE 1;
BA_ "U_CD4_MY14_Diesel_Rx" SG_ 1072 ePRNDL_MODE 1;
BA_ "U_CD4_MY14_Hev_Rx" SG_ 1072 ePRNDL_MODE 1;
BA_ "U_CD4_MY14_Phev_Rx" SG_ 1072 ePRNDL_MODE 1;
BA_ "GenSigTimeoutTime_TCM" SG_ 1072 ePRNDL_MODE 300;
BA_ "CrossOver_InfoCAN" SG_ 1072 EngOilLife_B_RqReset 1;
BA_ "GenSigSendType" SG_ 1072 EngOilLife_B_RqReset 3;
BA_ "U_CD4_MY13_Gas_Rx" SG_ 1072 EngOilLife_B_RqReset 1;
BA_ "U_CD42_MY14_Gas_Rx" SG_ 1072 EngOilLife_B_RqReset 1;
BA_ "U_P552_MY15_Gas_Rx" SG_ 1072 EngOilLife_B_RqReset 1;
BA_ "U_S550_MY15_Gas_Rx" SG_ 1072 EngOilLife_B_RqReset 1;
BA_ "U_C489_MY14_Gas_Rx" SG_ 1072 EngOilLife_B_RqReset 1;
BA_ "U_U502_MY15_Gas_Rx" SG_ 1072 EngOilLife_B_RqReset 1;
BA_ "U_CD43_MY16_Gas_Rx" SG_ 1072 EngOilLife_B_RqReset 1;
BA_ "U_CD4_MY14_Gas_Rx" SG_ 1072 EngOilLife_B_RqReset 1;
BA_ "CrossOver_InfoCAN" SG_ 1072 Outside_Air_Temp_Stat_UB 1;
BA_ "U_CD4_MY13_Diesel_Rx" SG_ 1072 Outside_Air_Temp_Stat_UB 1;
BA_ "U_CD4_MY13_Gas_Rx" SG_ 1072 Outside_Air_Temp_Stat_UB 1;
BA_ "U_CD4_MY13_Hev_Rx" SG_ 1072 Outside_Air_Temp_Stat_UB 1;
BA_ "U_CD4_MY13_Phev_Rx" SG_ 1072 Outside_Air_Temp_Stat_UB 1;
BA_ "U_CD42_MY14_Diesel_Rx" SG_ 1072 Outside_Air_Temp_Stat_UB 1;
BA_ "U_CD42_MY14_Gas_Rx" SG_ 1072 Outside_Air_Temp_Stat_UB 1;
BA_ "U_P552_MY15_Gas_Rx" SG_ 1072 Outside_Air_Temp_Stat_UB 1;
BA_ "U_S550_MY15_Gas_Rx" SG_ 1072 Outside_Air_Temp_Stat_UB 1;
BA_ "U_C489_MY14_Gas_Rx" SG_ 1072 Outside_Air_Temp_Stat_UB 1;
BA_ "U_U502_MY15_Gas_Rx" SG_ 1072 Outside_Air_Temp_Stat_UB 1;
BA_ "U_UP375_MY15_Gas_Rx" SG_ 1072 Outside_Air_Temp_Stat_UB 1;
BA_ "U_UP375_MY15_Diesel_Rx" SG_ 1072 Outside_Air_Temp_Stat_UB 1;
BA_ "U_CD43_MY16_Gas_Rx" SG_ 1072 Outside_Air_Temp_Stat_UB 1;
BA_ "U_CD4_MY14_Diesel_Rx" SG_ 1072 Outside_Air_Temp_Stat_UB 1;
BA_ "U_CD4_MY14_Gas_Rx" SG_ 1072 Outside_Air_Temp_Stat_UB 1;
BA_ "U_CD4_MY14_Hev_Rx" SG_ 1072 Outside_Air_Temp_Stat_UB 1;
BA_ "U_CD4_MY14_Phev_Rx" SG_ 1072 Outside_Air_Temp_Stat_UB 1;
BA_ "CrossOver_InfoCAN" SG_ 1072 Outside_Air_Temp_Stat 1;
BA_ "GenSigStartValue" SG_ 1072 Outside_Air_Temp_Stat 255;
BA_ "GenSigSendType" SG_ 1072 Outside_Air_Temp_Stat 3;
BA_ "U_CD4_MY13_Gas_Rx" SG_ 1072 Outside_Air_Temp_Stat 1;
BA_ "U_CD42_MY14_Gas_Rx" SG_ 1072 Outside_Air_Temp_Stat 1;
BA_ "U_P552_MY15_Gas_Rx" SG_ 1072 Outside_Air_Temp_Stat 1;
BA_ "U_S550_MY15_Gas_Rx" SG_ 1072 Outside_Air_Temp_Stat 1;
BA_ "U_C489_MY14_Gas_Rx" SG_ 1072 Outside_Air_Temp_Stat 1;
BA_ "U_U502_MY15_Gas_Rx" SG_ 1072 Outside_Air_Temp_Stat 1;
BA_ "U_UP375_MY15_Gas_Rx" SG_ 1072 Outside_Air_Temp_Stat 1;
BA_ "U_UP375_MY15_Diesel_Rx" SG_ 1072 Outside_Air_Temp_Stat 1;
BA_ "U_CD43_MY16_Gas_Rx" SG_ 1072 Outside_Air_Temp_Stat 1;
BA_ "U_CD4_MY14_Diesel_Rx" SG_ 1072 Outside_Air_Temp_Stat 1;
BA_ "U_CD4_MY14_Gas_Rx" SG_ 1072 Outside_Air_Temp_Stat 1;
BA_ "U_CD4_MY14_Hev_Rx" SG_ 1072 Outside_Air_Temp_Stat 1;
BA_ "U_CD4_MY14_Phev_Rx" SG_ 1072 Outside_Air_Temp_Stat 1;
BA_ "U_CD4_MY13_Diesel_Rx" SG_ 1072 KeyTypeChngMykey_D_Rq_UB 1;
BA_ "U_CD4_MY13_Gas_Rx" SG_ 1072 KeyTypeChngMykey_D_Rq_UB 1;
BA_ "U_CD4_MY13_Hev_Rx" SG_ 1072 KeyTypeChngMykey_D_Rq_UB 1;
BA_ "U_CD4_MY13_Phev_Rx" SG_ 1072 KeyTypeChngMykey_D_Rq_UB 1;
BA_ "U_CD42_MY14_Diesel_Rx" SG_ 1072 KeyTypeChngMykey_D_Rq_UB 1;
BA_ "U_CD42_MY14_Gas_Rx" SG_ 1072 KeyTypeChngMykey_D_Rq_UB 1;
BA_ "U_P552_MY15_Gas_Rx" SG_ 1072 KeyTypeChngMykey_D_Rq_UB 1;
BA_ "U_S550_MY15_Gas_Rx" SG_ 1072 KeyTypeChngMykey_D_Rq_UB 1;
BA_ "U_C489_MY14_Gas_Rx" SG_ 1072 KeyTypeChngMykey_D_Rq_UB 1;
BA_ "U_U502_MY15_Gas_Rx" SG_ 1072 KeyTypeChngMykey_D_Rq_UB 1;
BA_ "U_UP375_MY15_Gas_Rx" SG_ 1072 KeyTypeChngMykey_D_Rq_UB 1;
BA_ "U_UP375_MY15_Diesel_Rx" SG_ 1072 KeyTypeChngMykey_D_Rq_UB 1;
BA_ "U_CD43_MY16_Gas_Rx" SG_ 1072 KeyTypeChngMykey_D_Rq_UB 1;
BA_ "U_CD4_MY14_Diesel_Rx" SG_ 1072 KeyTypeChngMykey_D_Rq_UB 1;
BA_ "U_CD4_MY14_Gas_Rx" SG_ 1072 KeyTypeChngMykey_D_Rq_UB 1;
BA_ "U_CD4_MY14_Hev_Rx" SG_ 1072 KeyTypeChngMykey_D_Rq_UB 1;
BA_ "U_CD4_MY14_Phev_Rx" SG_ 1072 KeyTypeChngMykey_D_Rq_UB 1;
BA_ "CrossOver_InfoCAN" SG_ 1072 KeyTypeChngMykey_D_Rq 1;
BA_ "GenSigSendType" SG_ 1072 KeyTypeChngMykey_D_Rq 3;
BA_ "U_CD4_MY13_Diesel_Rx" SG_ 1072 KeyTypeChngMykey_D_Rq 1;
BA_ "U_CD4_MY13_Gas_Rx" SG_ 1072 KeyTypeChngMykey_D_Rq 1;
BA_ "U_CD4_MY13_Hev_Rx" SG_ 1072 KeyTypeChngMykey_D_Rq 1;
BA_ "U_CD4_MY13_Phev_Rx" SG_ 1072 KeyTypeChngMykey_D_Rq 1;
BA_ "U_CD42_MY14_Diesel_Rx" SG_ 1072 KeyTypeChngMykey_D_Rq 1;
BA_ "U_CD42_MY14_Gas_Rx" SG_ 1072 KeyTypeChngMykey_D_Rq 1;
BA_ "U_P552_MY15_Gas_Rx" SG_ 1072 KeyTypeChngMykey_D_Rq 1;
BA_ "U_S550_MY15_Gas_Rx" SG_ 1072 KeyTypeChngMykey_D_Rq 1;
BA_ "U_C489_MY14_Gas_Rx" SG_ 1072 KeyTypeChngMykey_D_Rq 1;
BA_ "U_U502_MY15_Gas_Rx" SG_ 1072 KeyTypeChngMykey_D_Rq 1;
BA_ "U_UP375_MY15_Gas_Rx" SG_ 1072 KeyTypeChngMykey_D_Rq 1;
BA_ "U_UP375_MY15_Diesel_Rx" SG_ 1072 KeyTypeChngMykey_D_Rq 1;
BA_ "U_CD43_MY16_Gas_Rx" SG_ 1072 KeyTypeChngMykey_D_Rq 1;
BA_ "U_CD4_MY14_Diesel_Rx" SG_ 1072 KeyTypeChngMykey_D_Rq 1;
BA_ "U_CD4_MY14_Gas_Rx" SG_ 1072 KeyTypeChngMykey_D_Rq 1;
BA_ "U_CD4_MY14_Hev_Rx" SG_ 1072 KeyTypeChngMykey_D_Rq 1;
BA_ "U_CD4_MY14_Phev_Rx" SG_ 1072 KeyTypeChngMykey_D_Rq 1;
BA_ "CrossOver_InfoCAN" SG_ 1072 TrlrLampCnnct_B_Actl 1;
BA_ "GenSigSendType" SG_ 1072 TrlrLampCnnct_B_Actl 3;
BA_ "U_CD4_MY13_Diesel_Rx" SG_ 1072 TrlrLampCnnct_B_Actl 1;
BA_ "U_CD4_MY13_Gas_Rx" SG_ 1072 TrlrLampCnnct_B_Actl 1;
BA_ "U_CD4_MY13_Hev_Rx" SG_ 1072 TrlrLampCnnct_B_Actl 1;
BA_ "U_CD4_MY13_Phev_Rx" SG_ 1072 TrlrLampCnnct_B_Actl 1;
BA_ "U_CD42_MY14_Diesel_Rx" SG_ 1072 TrlrLampCnnct_B_Actl 1;
BA_ "U_CD42_MY14_Gas_Rx" SG_ 1072 TrlrLampCnnct_B_Actl 1;
BA_ "U_P552_MY15_Gas_Rx" SG_ 1072 TrlrLampCnnct_B_Actl 1;
BA_ "U_C489_MY14_Gas_Rx" SG_ 1072 TrlrLampCnnct_B_Actl 1;
BA_ "U_U502_MY15_Gas_Rx" SG_ 1072 TrlrLampCnnct_B_Actl 1;
BA_ "U_CD4_MY14_Gas_Rx" SG_ 1072 TrlrLampCnnct_B_Actl 1;
BA_ "U_S550_MY15_Gas_Rx" SG_ 1072 TrlrLampCnnct_B_Actl 1;
BA_ "U_UP375_MY15_Gas_Rx" SG_ 1072 TrlrLampCnnct_B_Actl 1;
BA_ "U_UP375_MY15_Diesel_Rx" SG_ 1072 TrlrLampCnnct_B_Actl 1;
BA_ "U_CD43_MY16_Gas_Rx" SG_ 1072 TrlrLampCnnct_B_Actl 1;
BA_ "U_CD4_MY14_Diesel_Rx" SG_ 1072 TrlrLampCnnct_B_Actl 1;
BA_ "U_CD4_MY14_Hev_Rx" SG_ 1072 TrlrLampCnnct_B_Actl 1;
BA_ "U_CD4_MY14_Phev_Rx" SG_ 1072 TrlrLampCnnct_B_Actl 1;
BA_ "CrossOver_InfoCAN" SG_ 1072 ManRgen_D_Rq 1;
BA_ "GenSigSendType" SG_ 1072 ManRgen_D_Rq 3;
BA_ "U_CD42_MY15_Diesel_Rx" SG_ 1438 GWM_AutoSar_NetworkMgmt_H1 1;
BA_ "U_U502_MY16_Gas_Rx" SG_ 1438 GWM_AutoSar_NetworkMgmt_H1 1;
BA_ "U_CD4_MY17_Diesel_Rx" SG_ 1438 GWM_AutoSar_NetworkMgmt_H1 1;
BA_ "U_CD4_MY17_Gas_Rx" SG_ 1438 GWM_AutoSar_NetworkMgmt_H1 1;
BA_ "U_CD4_MY17_Hev_Rx" SG_ 1438 GWM_AutoSar_NetworkMgmt_H1 1;
BA_ "U_CD4_MY17_Phev_Rx" SG_ 1438 GWM_AutoSar_NetworkMgmt_H1 1;
BA_ "U_P558_MY17_Gas_Rx" SG_ 1438 GWM_AutoSar_NetworkMgmt_H1 1;
BA_ "U_P558_MY17_Diesel_Rx" SG_ 1438 GWM_AutoSar_NetworkMgmt_H1 1;
BA_ "U_V36X_MY16_5_Diesel_Rx" SG_ 1438 GWM_AutoSar_NetworkMgmt_H1 1;
BA_ "U_C489_MY17_Gas_Rx" SG_ 1438 GWM_AutoSar_NetworkMgmt_H1 1;
BA_ "U_CD42_MY16_Diesel_Rx" SG_ 1438 GWM_AutoSar_NetworkMgmt_H1 1;
BA_ "U_CD42_MY16_Gas_Rx" SG_ 1438 GWM_AutoSar_NetworkMgmt_H1 1;
BA_ "U_CD43_MY17_Gas_Rx" SG_ 1438 GWM_AutoSar_NetworkMgmt_H1 1;
BA_ "U_P552_MY17_Gas_Rx" SG_ 1438 GWM_AutoSar_NetworkMgmt_H1 1;
BA_ "U_B515_MCA_MY17_Diesel_Rx" SG_ 1438 GWM_AutoSar_NetworkMgmt_H1 1;
BA_ "U_B515_MCA_MY17_Gas_Rx" SG_ 1438 GWM_AutoSar_NetworkMgmt_H1 1;
BA_ "U_U55x_MY18_Gas_Rx" SG_ 1438 GWM_AutoSar_NetworkMgmt_H1 1;
BA_ "GenSigSendType" SG_ 1438 GWM_AutoSar_NetworkMgmt_H1 3;
BA_ "U_CD4_MY13_Diesel_Rx" SG_ 1438 GWM_AutoSar_NetworkMgmt_H1 1;
BA_ "U_CD42_MY14_Diesel_Rx" SG_ 1438 GWM_AutoSar_NetworkMgmt_H1 1;
BA_ "U_CD42_MY14_Gas_Rx" SG_ 1438 GWM_AutoSar_NetworkMgmt_H1 1;
BA_ "U_S550_MY15_Gas_Rx" SG_ 1438 GWM_AutoSar_NetworkMgmt_H1 1;
BA_ "U_U502_MY15_Gas_Rx" SG_ 1438 GWM_AutoSar_NetworkMgmt_H1 1;
BA_ "U_CD43_MY16_Gas_Rx" SG_ 1438 GWM_AutoSar_NetworkMgmt_H1 1;
BA_ "U_CD4_MY14_Gas_Rx" SG_ 1438 GWM_AutoSar_NetworkMgmt_H1 1;
BA_ "U_UP375_MY15_Gas_Rx" SG_ 1438 GWM_AutoSar_NetworkMgmt_H1 1;
BA_ "U_UP375_MY15_Diesel_Rx" SG_ 1438 GWM_AutoSar_NetworkMgmt_H1 1;
BA_ "U_CD4_MY14_Diesel_Rx" SG_ 1438 GWM_AutoSar_NetworkMgmt_H1 1;
BA_ "U_CD4_MY14_Hev_Rx" SG_ 1438 GWM_AutoSar_NetworkMgmt_H1 1;
BA_ "U_CD4_MY14_Phev_Rx" SG_ 1438 GWM_AutoSar_NetworkMgmt_H1 1;
BA_ "GenSigSendType" SG_ 1814 TesterPhysicalReqGWM_H1 3;
BA_ "U_CD4_MY13_Diesel_Tx" SG_ 1814 TesterPhysicalReqGWM_H1 1;
BA_ "U_CD4_MY13_Gas_Tx" SG_ 1814 TesterPhysicalReqGWM_H1 1;
BA_ "U_CD4_MY13_Hev_Tx" SG_ 1814 TesterPhysicalReqGWM_H1 1;
BA_ "U_CD4_MY13_Phev_Tx" SG_ 1814 TesterPhysicalReqGWM_H1 1;
BA_ "U_CD42_MY14_Diesel_Tx" SG_ 1814 TesterPhysicalReqGWM_H1 1;
BA_ "U_CD42_MY14_Gas_Tx" SG_ 1814 TesterPhysicalReqGWM_H1 1;
BA_ "U_P552_MY15_Gas_Tx" SG_ 1814 TesterPhysicalReqGWM_H1 1;
BA_ "U_S550_MY15_Gas_Tx" SG_ 1814 TesterPhysicalReqGWM_H1 1;
BA_ "U_C489_MY14_Gas_Tx" SG_ 1814 TesterPhysicalReqGWM_H1 1;
BA_ "GenSigSendType" SG_ 1822 TesterPhysicalResGWM_H1 3;
BA_ "U_CD4_MY13_Diesel_Rx" SG_ 1822 TesterPhysicalResGWM_H1 1;
BA_ "U_CD4_MY13_Gas_Rx" SG_ 1822 TesterPhysicalResGWM_H1 1;
BA_ "U_CD4_MY13_Hev_Rx" SG_ 1822 TesterPhysicalResGWM_H1 1;
BA_ "U_CD4_MY13_Phev_Rx" SG_ 1822 TesterPhysicalResGWM_H1 1;
BA_ "U_CD42_MY14_Diesel_Rx" SG_ 1822 TesterPhysicalResGWM_H1 1;
BA_ "U_CD42_MY14_Gas_Rx" SG_ 1822 TesterPhysicalResGWM_H1 1;
BA_ "U_P552_MY15_Gas_Rx" SG_ 1822 TesterPhysicalResGWM_H1 1;
BA_ "U_S550_MY15_Gas_Rx" SG_ 1822 TesterPhysicalResGWM_H1 1;
BA_ "U_C489_MY14_Gas_Rx" SG_ 1822 TesterPhysicalResGWM_H1 1;
BA_ "U_UP375_MY15_Gas_Rx" SG_ 806 SnowPlowMde_B_Enbl 1;
BA_ "U_UP375_MY15_Diesel_Rx" SG_ 806 SnowPlowMde_B_Enbl 1;
BA_ "U_P558_MY17_Gas_Rx" SG_ 806 SnowPlowMde_B_Enbl 1;
BA_ "U_P558_MY17_Diesel_Rx" SG_ 806 SnowPlowMde_B_Enbl 1;
BA_ "U_V36X_MY16_5_Diesel_Rx" SG_ 806 SnowPlowMde_B_Enbl 1;
BA_ "Gateway_ID" SG_ 806 SnowPlowMde_B_Enbl 27631;
BA_ "U_CD4_MY13_Gas_Rx" SG_ 806 StopStrtDrvMde_B_RqBtn 1;
BA_ "U_CD42_MY14_Gas_Rx" SG_ 806 StopStrtDrvMde_B_RqBtn 1;
BA_ "U_P552_MY15_Gas_Rx" SG_ 806 StopStrtDrvMde_B_RqBtn 1;
BA_ "U_U502_MY15_Gas_Rx" SG_ 806 StopStrtDrvMde_B_RqBtn 1;
BA_ "U_CD43_MY16_Gas_Rx" SG_ 806 StopStrtDrvMde_B_RqBtn 1;
BA_ "U_CD4_MY14_Gas_Rx" SG_ 806 StopStrtDrvMde_B_RqBtn 1;
BA_ "U_CD4_MY13_Gas_Rx" SG_ 806 ClimtHeat_D_Rq 1;
BA_ "U_CD42_MY14_Gas_Rx" SG_ 806 ClimtHeat_D_Rq 1;
BA_ "U_P552_MY15_Gas_Rx" SG_ 806 ClimtHeat_D_Rq 1;
BA_ "U_U502_MY15_Gas_Rx" SG_ 806 ClimtHeat_D_Rq 1;
BA_ "U_CD43_MY16_Gas_Rx" SG_ 806 ClimtHeat_D_Rq 1;
BA_ "U_CD4_MY14_Gas_Rx" SG_ 806 ClimtHeat_D_Rq 1;
BA_ "U_CD4_MY13_Gas_Rx" SG_ 806 ClimtCool_D_Rq 1;
BA_ "U_CD42_MY14_Gas_Rx" SG_ 806 ClimtCool_D_Rq 1;
BA_ "U_P552_MY15_Gas_Rx" SG_ 806 ClimtCool_D_Rq 1;
BA_ "U_U502_MY15_Gas_Rx" SG_ 806 ClimtCool_D_Rq 1;
BA_ "U_CD43_MY16_Gas_Rx" SG_ 806 ClimtCool_D_Rq 1;
BA_ "U_CD4_MY14_Gas_Rx" SG_ 806 ClimtCool_D_Rq 1;
BA_ "GenSigStartValue" SG_ 806 HvacEvap_Te_Rq 400;
BA_ "U_CD4_MY13_Gas_Rx" SG_ 806 HvacEvap_Te_Rq 1;
BA_ "U_CD42_MY14_Gas_Rx" SG_ 806 HvacEvap_Te_Rq 1;
BA_ "U_P552_MY15_Gas_Rx" SG_ 806 HvacEvap_Te_Rq 1;
BA_ "U_S550_MY15_Gas_Rx" SG_ 806 HvacEvap_Te_Rq 1;
BA_ "U_C489_MY14_Gas_Rx" SG_ 806 HvacEvap_Te_Rq 1;
BA_ "U_U502_MY15_Gas_Rx" SG_ 806 HvacEvap_Te_Rq 1;
BA_ "U_CD43_MY16_Gas_Rx" SG_ 806 HvacEvap_Te_Rq 1;
BA_ "U_CD4_MY14_Gas_Rx" SG_ 806 HvacEvap_Te_Rq 1;
BA_ "GenSigStartValue" SG_ 806 HvacEvap_Te_Actl 400;
BA_ "U_CD4_MY13_Gas_Rx" SG_ 806 HvacEvap_Te_Actl 1;
BA_ "U_CD42_MY14_Gas_Rx" SG_ 806 HvacEvap_Te_Actl 1;
BA_ "U_P552_MY15_Gas_Rx" SG_ 806 HvacEvap_Te_Actl 1;
BA_ "U_S550_MY15_Gas_Rx" SG_ 806 HvacEvap_Te_Actl 1;
BA_ "U_C489_MY14_Gas_Rx" SG_ 806 HvacEvap_Te_Actl 1;
BA_ "U_U502_MY15_Gas_Rx" SG_ 806 HvacEvap_Te_Actl 1;
BA_ "U_CD43_MY16_Gas_Rx" SG_ 806 HvacEvap_Te_Actl 1;
BA_ "U_CD4_MY14_Gas_Rx" SG_ 806 HvacEvap_Te_Actl 1;
BA_ "U_CD4_MY13_Gas_Rx" SG_ 806 HvacAirCond_B_Rq 1;
BA_ "U_CD42_MY14_Gas_Rx" SG_ 806 HvacAirCond_B_Rq 1;
BA_ "U_P552_MY15_Gas_Rx" SG_ 806 HvacAirCond_B_Rq 1;
BA_ "U_S550_MY15_Gas_Rx" SG_ 806 HvacAirCond_B_Rq 1;
BA_ "U_C489_MY14_Gas_Rx" SG_ 806 HvacAirCond_B_Rq 1;
BA_ "U_U502_MY15_Gas_Rx" SG_ 806 HvacAirCond_B_Rq 1;
BA_ "U_CD43_MY16_Gas_Rx" SG_ 806 HvacAirCond_B_Rq 1;
BA_ "U_CD4_MY14_Gas_Rx" SG_ 806 HvacAirCond_B_Rq 1;
BA_ "GenSigStartValue" SG_ 806 HvacEvap_Te_Offst 400;
BA_ "U_CD4_MY13_Gas_Rx" SG_ 806 HvacEvap_Te_Offst 1;
BA_ "U_CD42_MY14_Gas_Rx" SG_ 806 HvacEvap_Te_Offst 1;
BA_ "U_P552_MY15_Gas_Rx" SG_ 806 HvacEvap_Te_Offst 1;
BA_ "U_S550_MY15_Gas_Rx" SG_ 806 HvacEvap_Te_Offst 1;
BA_ "U_C489_MY14_Gas_Rx" SG_ 806 HvacEvap_Te_Offst 1;
BA_ "U_U502_MY15_Gas_Rx" SG_ 806 HvacEvap_Te_Offst 1;
BA_ "U_CD43_MY16_Gas_Rx" SG_ 806 HvacEvap_Te_Offst 1;
BA_ "U_CD4_MY14_Gas_Rx" SG_ 806 HvacEvap_Te_Offst 1;
BA_ "GenSigStartValue" SG_ 806 ClimtDeltaLoad_Pw_Actl 32;
BA_ "U_CD4_MY13_Gas_Rx" SG_ 806 ClimtPw_B_Rq 1;
BA_ "U_CD42_MY14_Gas_Rx" SG_ 806 ClimtPw_B_Rq 1;
BA_ "U_P552_MY15_Gas_Rx" SG_ 806 ClimtPw_B_Rq 1;
BA_ "U_U502_MY15_Gas_Rx" SG_ 806 ClimtPw_B_Rq 1;
BA_ "U_CD43_MY16_Gas_Rx" SG_ 806 ClimtPw_B_Rq 1;
BA_ "U_CD4_MY14_Gas_Rx" SG_ 806 ClimtPw_B_Rq 1;
BA_ "U_P552_MY15_Gas_Rx" SG_ 578 PtLatchActv_B_RqBcm 1;
BA_ "U_S550_MY15_Gas_Rx" SG_ 578 PtLatchActv_B_RqBcm 1;
BA_ "U_C489_MY14_Gas_Rx" SG_ 578 PtLatchActv_B_RqBcm 1;
BA_ "U_CD43_MY16_Gas_Rx" SG_ 578 PtLatchActv_B_RqBcm 1;
BA_ "U_P552_MY15_Gas_Tx" SG_ 578 PtLatchActv_B_RqBcm 1;
BA_ "U_S550_MY15_Gas_Tx" SG_ 578 PtLatchActv_B_RqBcm 1;
BA_ "U_C489_MY14_Gas_Tx" SG_ 578 PtLatchActv_B_RqBcm 1;
BA_ "U_CD43_MY16_Gas_Tx" SG_ 578 PtLatchActv_B_RqBcm 1;
BA_ "U_CD4_MY14_Diesel_Tx" SG_ 578 PtLatchActv_B_RqBcm 1;
BA_ "U_CD4_MY14_Gas_Tx" SG_ 578 PtLatchActv_B_RqBcm 1;
BA_ "U_CD4_MY14_Hev_Tx" SG_ 578 PtLatchActv_B_RqBcm 1;
BA_ "U_CD4_MY14_Phev_Tx" SG_ 578 PtLatchActv_B_RqBcm 1;
BA_ "GenSigTimeoutTime_TCM" SG_ 578 PtLatchActv_B_RqBcm 120;
BA_ "U_CD4_MY13_Gas_Rx" SG_ 578 immoSecureIdleMode 1;
BA_ "U_CD42_MY14_Gas_Rx" SG_ 578 immoSecureIdleMode 1;
BA_ "U_P552_MY15_Gas_Rx" SG_ 578 immoSecureIdleMode 1;
BA_ "U_S550_MY15_Gas_Rx" SG_ 578 immoSecureIdleMode 1;
BA_ "U_C489_MY14_Gas_Rx" SG_ 578 immoSecureIdleMode 1;
BA_ "U_U502_MY15_Gas_Rx" SG_ 578 immoSecureIdleMode 1;
BA_ "U_UP375_MY15_Gas_Rx" SG_ 578 immoSecureIdleMode 1;
BA_ "U_CD43_MY16_Gas_Rx" SG_ 578 immoSecureIdleMode 1;
BA_ "U_CD4_MY14_Gas_Rx" SG_ 578 immoSecureIdleMode 1;
BA_ "U_CD4_MY13_Diesel_Tx" SG_ 578 immoSecureIdleMode 1;
BA_ "U_CD4_MY13_Gas_Tx" SG_ 578 immoSecureIdleMode 1;
BA_ "U_CD4_MY13_Hev_Tx" SG_ 578 immoSecureIdleMode 1;
BA_ "U_CD4_MY13_Phev_Tx" SG_ 578 immoSecureIdleMode 1;
BA_ "U_CD42_MY14_Diesel_Tx" SG_ 578 immoSecureIdleMode 1;
BA_ "U_CD42_MY14_Gas_Tx" SG_ 578 immoSecureIdleMode 1;
BA_ "U_P552_MY15_Gas_Tx" SG_ 578 immoSecureIdleMode 1;
BA_ "U_S550_MY15_Gas_Tx" SG_ 578 immoSecureIdleMode 1;
BA_ "U_C489_MY14_Gas_Tx" SG_ 578 immoSecureIdleMode 1;
BA_ "U_U502_MY15_Gas_Tx" SG_ 578 immoSecureIdleMode 1;
BA_ "U_UP375_MY15_Gas_Tx" SG_ 578 immoSecureIdleMode 1;
BA_ "U_UP375_MY15_Diesel_Tx" SG_ 578 immoSecureIdleMode 1;
BA_ "U_CD43_MY16_Gas_Tx" SG_ 578 immoSecureIdleMode 1;
BA_ "U_CD4_MY14_Diesel_Tx" SG_ 578 immoSecureIdleMode 1;
BA_ "U_CD4_MY14_Gas_Tx" SG_ 578 immoSecureIdleMode 1;
BA_ "U_CD4_MY14_Hev_Tx" SG_ 578 immoSecureIdleMode 1;
BA_ "U_CD4_MY14_Phev_Tx" SG_ 578 immoSecureIdleMode 1;
BA_ "WakeupSignal" SG_ 578 ReFuelSwtchStat_D_Actl 1;
BA_ "U_CD4_MY13_Diesel_Tx" SG_ 578 ReFuelSwtchStat_D_Actl 1;
BA_ "U_CD4_MY13_Gas_Tx" SG_ 578 ReFuelSwtchStat_D_Actl 1;
BA_ "U_CD4_MY13_Hev_Tx" SG_ 578 ReFuelSwtchStat_D_Actl 1;
BA_ "U_CD4_MY13_Phev_Tx" SG_ 578 ReFuelSwtchStat_D_Actl 1;
BA_ "U_CD42_MY14_Diesel_Tx" SG_ 578 ReFuelSwtchStat_D_Actl 1;
BA_ "U_CD42_MY14_Gas_Tx" SG_ 578 ReFuelSwtchStat_D_Actl 1;
BA_ "U_P552_MY15_Gas_Tx" SG_ 578 ReFuelSwtchStat_D_Actl 1;
BA_ "U_S550_MY15_Gas_Tx" SG_ 578 ReFuelSwtchStat_D_Actl 1;
BA_ "U_C489_MY14_Gas_Tx" SG_ 578 ReFuelSwtchStat_D_Actl 1;
BA_ "U_U502_MY15_Gas_Tx" SG_ 578 ReFuelSwtchStat_D_Actl 1;
BA_ "U_UP375_MY15_Gas_Tx" SG_ 578 ReFuelSwtchStat_D_Actl 1;
BA_ "U_UP375_MY15_Diesel_Tx" SG_ 578 ReFuelSwtchStat_D_Actl 1;
BA_ "U_CD43_MY16_Gas_Tx" SG_ 578 ReFuelSwtchStat_D_Actl 1;
BA_ "U_CD4_MY14_Diesel_Tx" SG_ 578 ReFuelSwtchStat_D_Actl 1;
BA_ "U_CD4_MY14_Gas_Tx" SG_ 578 ReFuelSwtchStat_D_Actl 1;
BA_ "U_CD4_MY14_Hev_Tx" SG_ 578 ReFuelSwtchStat_D_Actl 1;
BA_ "U_CD4_MY14_Phev_Tx" SG_ 578 ReFuelSwtchStat_D_Actl 1;
BA_ "U_CD4_MY13_Gas_Rx" SG_ 578 FuelPumpPwr_D_Stat 1;
BA_ "U_CD42_MY14_Gas_Rx" SG_ 578 FuelPumpPwr_D_Stat 1;
BA_ "U_P552_MY15_Gas_Rx" SG_ 578 FuelPumpPwr_D_Stat 1;
BA_ "U_S550_MY15_Gas_Rx" SG_ 578 FuelPumpPwr_D_Stat 1;
BA_ "U_C489_MY14_Gas_Rx" SG_ 578 FuelPumpPwr_D_Stat 1;
BA_ "U_U502_MY15_Gas_Rx" SG_ 578 FuelPumpPwr_D_Stat 1;
BA_ "U_UP375_MY15_Gas_Rx" SG_ 578 FuelPumpPwr_D_Stat 1;
BA_ "U_CD43_MY16_Gas_Rx" SG_ 578 FuelPumpPwr_D_Stat 1;
BA_ "U_CD4_MY14_Gas_Rx" SG_ 578 FuelPumpPwr_D_Stat 1;
BA_ "U_CD4_MY13_Diesel_Tx" SG_ 578 FuelPumpPwr_D_Stat 1;
BA_ "U_CD4_MY13_Gas_Tx" SG_ 578 FuelPumpPwr_D_Stat 1;
BA_ "U_CD4_MY13_Hev_Tx" SG_ 578 FuelPumpPwr_D_Stat 1;
BA_ "U_CD4_MY13_Phev_Tx" SG_ 578 FuelPumpPwr_D_Stat 1;
BA_ "U_CD42_MY14_Diesel_Tx" SG_ 578 FuelPumpPwr_D_Stat 1;
BA_ "U_CD42_MY14_Gas_Tx" SG_ 578 FuelPumpPwr_D_Stat 1;
BA_ "U_P552_MY15_Gas_Tx" SG_ 578 FuelPumpPwr_D_Stat 1;
BA_ "U_S550_MY15_Gas_Tx" SG_ 578 FuelPumpPwr_D_Stat 1;
BA_ "U_C489_MY14_Gas_Tx" SG_ 578 FuelPumpPwr_D_Stat 1;
BA_ "U_U502_MY15_Gas_Tx" SG_ 578 FuelPumpPwr_D_Stat 1;
BA_ "U_UP375_MY15_Gas_Tx" SG_ 578 FuelPumpPwr_D_Stat 1;
BA_ "U_UP375_MY15_Diesel_Tx" SG_ 578 FuelPumpPwr_D_Stat 1;
BA_ "U_CD43_MY16_Gas_Tx" SG_ 578 FuelPumpPwr_D_Stat 1;
BA_ "U_CD4_MY14_Diesel_Tx" SG_ 578 FuelPumpPwr_D_Stat 1;
BA_ "U_CD4_MY14_Gas_Tx" SG_ 578 FuelPumpPwr_D_Stat 1;
BA_ "U_CD4_MY14_Hev_Tx" SG_ 578 FuelPumpPwr_D_Stat 1;
BA_ "U_CD4_MY14_Phev_Tx" SG_ 578 FuelPumpPwr_D_Stat 1;
BA_ "GenSigStartValue" SG_ 578 BattULo_U_Actl 255;
BA_ "U_CD4_MY13_Gas_Rx" SG_ 578 BattULo_U_Actl 1;
BA_ "U_CD42_MY14_Gas_Rx" SG_ 578 BattULo_U_Actl 1;
BA_ "U_P552_MY15_Gas_Rx" SG_ 578 BattULo_U_Actl 1;
BA_ "U_S550_MY15_Gas_Rx" SG_ 578 BattULo_U_Actl 1;
BA_ "U_C489_MY14_Gas_Rx" SG_ 578 BattULo_U_Actl 1;
BA_ "U_U502_MY15_Gas_Rx" SG_ 578 BattULo_U_Actl 1;
BA_ "U_UP375_MY15_Gas_Rx" SG_ 578 BattULo_U_Actl 1;
BA_ "U_CD43_MY16_Gas_Rx" SG_ 578 BattULo_U_Actl 1;
BA_ "U_CD4_MY14_Gas_Rx" SG_ 578 BattULo_U_Actl 1;
BA_ "U_CD4_MY13_Diesel_Tx" SG_ 578 BattULo_U_Actl 1;
BA_ "U_CD4_MY13_Gas_Tx" SG_ 578 BattULo_U_Actl 1;
BA_ "U_CD4_MY13_Hev_Tx" SG_ 578 BattULo_U_Actl 1;
BA_ "U_CD4_MY13_Phev_Tx" SG_ 578 BattULo_U_Actl 1;
BA_ "U_CD42_MY14_Diesel_Tx" SG_ 578 BattULo_U_Actl 1;
BA_ "U_CD42_MY14_Gas_Tx" SG_ 578 BattULo_U_Actl 1;
BA_ "U_P552_MY15_Gas_Tx" SG_ 578 BattULo_U_Actl 1;
BA_ "U_S550_MY15_Gas_Tx" SG_ 578 BattULo_U_Actl 1;
BA_ "U_C489_MY14_Gas_Tx" SG_ 578 BattULo_U_Actl 1;
BA_ "U_U502_MY15_Gas_Tx" SG_ 578 BattULo_U_Actl 1;
BA_ "U_UP375_MY15_Gas_Tx" SG_ 578 BattULo_U_Actl 1;
BA_ "U_UP375_MY15_Diesel_Tx" SG_ 578 BattULo_U_Actl 1;
BA_ "U_CD43_MY16_Gas_Tx" SG_ 578 BattULo_U_Actl 1;
BA_ "U_CD4_MY14_Diesel_Tx" SG_ 578 BattULo_U_Actl 1;
BA_ "U_CD4_MY14_Gas_Tx" SG_ 578 BattULo_U_Actl 1;
BA_ "U_CD4_MY14_Hev_Tx" SG_ 578 BattULo_U_Actl 1;
BA_ "U_CD4_MY14_Phev_Tx" SG_ 578 BattULo_U_Actl 1;
BA_ "CrossOver_InfoCAN" SG_ 578 PrkLckCtl_B_Enbl 1;
BA_ "U_CD4_MY13_Diesel_Tx" SG_ 578 PrkLckCtl_B_Enbl 1;
BA_ "U_CD4_MY13_Gas_Tx" SG_ 578 PrkLckCtl_B_Enbl 1;
BA_ "U_CD4_MY13_Hev_Tx" SG_ 578 PrkLckCtl_B_Enbl 1;
BA_ "U_CD4_MY13_Phev_Tx" SG_ 578 PrkLckCtl_B_Enbl 1;
BA_ "U_CD42_MY14_Diesel_Tx" SG_ 578 PrkLckCtl_B_Enbl 1;
BA_ "U_CD42_MY14_Gas_Tx" SG_ 578 PrkLckCtl_B_Enbl 1;
BA_ "U_P552_MY15_Gas_Tx" SG_ 578 PrkLckCtl_B_Enbl 1;
BA_ "U_S550_MY15_Gas_Tx" SG_ 578 PrkLckCtl_B_Enbl 1;
BA_ "U_C489_MY14_Gas_Tx" SG_ 578 PrkLckCtl_B_Enbl 1;
BA_ "U_U502_MY15_Gas_Tx" SG_ 578 PrkLckCtl_B_Enbl 1;
BA_ "U_UP375_MY15_Gas_Tx" SG_ 578 PrkLckCtl_B_Enbl 1;
BA_ "U_UP375_MY15_Diesel_Tx" SG_ 578 PrkLckCtl_B_Enbl 1;
BA_ "U_CD43_MY16_Gas_Tx" SG_ 578 PrkLckCtl_B_Enbl 1;
BA_ "U_CD4_MY14_Diesel_Tx" SG_ 578 PrkLckCtl_B_Enbl 1;
BA_ "U_CD4_MY14_Gas_Tx" SG_ 578 PrkLckCtl_B_Enbl 1;
BA_ "U_CD4_MY14_Hev_Tx" SG_ 578 PrkLckCtl_B_Enbl 1;
BA_ "U_CD4_MY14_Phev_Tx" SG_ 578 PrkLckCtl_B_Enbl 1;
BA_ "GenSigTimeoutTime_TCM" SG_ 578 PrkLckCtl_B_Enbl 120;
BA_ "WakeupSignal" SG_ 578 PrkLckCtlMsgTxt_D_Rq 1;
BA_ "CrossOver_InfoCAN" SG_ 578 PrkLckCtlMsgTxt_D_Rq 1;
BA_ "U_CD4_MY13_Diesel_Rx" SG_ 578 PrkLckCtlMsgTxt_D_Rq 1;
BA_ "U_CD4_MY13_Gas_Rx" SG_ 578 PrkLckCtlMsgTxt_D_Rq 1;
BA_ "U_CD4_MY13_Hev_Rx" SG_ 578 PrkLckCtlMsgTxt_D_Rq 1;
BA_ "U_CD4_MY13_Phev_Rx" SG_ 578 PrkLckCtlMsgTxt_D_Rq 1;
BA_ "U_CD42_MY14_Diesel_Rx" SG_ 578 PrkLckCtlMsgTxt_D_Rq 1;
BA_ "U_CD42_MY14_Gas_Rx" SG_ 578 PrkLckCtlMsgTxt_D_Rq 1;
BA_ "U_P552_MY15_Gas_Rx" SG_ 578 PrkLckCtlMsgTxt_D_Rq 1;
BA_ "U_S550_MY15_Gas_Rx" SG_ 578 PrkLckCtlMsgTxt_D_Rq 1;
BA_ "U_C489_MY14_Gas_Rx" SG_ 578 PrkLckCtlMsgTxt_D_Rq 1;
BA_ "U_U502_MY15_Gas_Rx" SG_ 578 PrkLckCtlMsgTxt_D_Rq 1;
BA_ "U_B479_MY15_Gas_Rx" SG_ 578 PrkLckCtlMsgTxt_D_Rq 1;
BA_ "U_UP375_MY15_Gas_Rx" SG_ 578 PrkLckCtlMsgTxt_D_Rq 1;
BA_ "U_UP375_MY15_Diesel_Rx" SG_ 578 PrkLckCtlMsgTxt_D_Rq 1;
BA_ "U_CD4_MY13_Diesel_Tx" SG_ 578 PrkLckCtlMsgTxt_D_Rq 1;
BA_ "U_CD4_MY13_Gas_Tx" SG_ 578 PrkLckCtlMsgTxt_D_Rq 1;
BA_ "U_CD4_MY13_Hev_Tx" SG_ 578 PrkLckCtlMsgTxt_D_Rq 1;
BA_ "U_CD4_MY13_Phev_Tx" SG_ 578 PrkLckCtlMsgTxt_D_Rq 1;
BA_ "U_CD42_MY14_Diesel_Tx" SG_ 578 PrkLckCtlMsgTxt_D_Rq 1;
BA_ "U_CD42_MY14_Gas_Tx" SG_ 578 PrkLckCtlMsgTxt_D_Rq 1;
BA_ "U_P552_MY15_Gas_Tx" SG_ 578 PrkLckCtlMsgTxt_D_Rq 1;
BA_ "U_S550_MY15_Gas_Tx" SG_ 578 PrkLckCtlMsgTxt_D_Rq 1;
BA_ "U_C489_MY14_Gas_Tx" SG_ 578 PrkLckCtlMsgTxt_D_Rq 1;
BA_ "U_U502_MY15_Gas_Tx" SG_ 578 PrkLckCtlMsgTxt_D_Rq 1;
BA_ "U_UP375_MY15_Gas_Tx" SG_ 578 PrkLckCtlMsgTxt_D_Rq 1;
BA_ "U_UP375_MY15_Diesel_Tx" SG_ 578 PrkLckCtlMsgTxt_D_Rq 1;
BA_ "U_CD43_MY16_Gas_Tx" SG_ 578 PrkLckCtlMsgTxt_D_Rq 1;
BA_ "U_CD4_MY14_Diesel_Tx" SG_ 578 PrkLckCtlMsgTxt_D_Rq 1;
BA_ "U_CD4_MY14_Gas_Tx" SG_ 578 PrkLckCtlMsgTxt_D_Rq 1;
BA_ "U_CD4_MY14_Hev_Tx" SG_ 578 PrkLckCtlMsgTxt_D_Rq 1;
BA_ "U_CD4_MY14_Phev_Tx" SG_ 578 PrkLckCtlMsgTxt_D_Rq 1;
BA_ "WakeupSignal" SG_ 578 PrkLckCtlAvail_T_Stat 1;
BA_ "CrossOver_InfoCAN" SG_ 578 PrkLckCtlAvail_T_Stat 1;
BA_ "U_CD4_MY13_Diesel_Rx" SG_ 578 PrkLckCtlAvail_T_Stat 1;
BA_ "U_CD4_MY13_Gas_Rx" SG_ 578 PrkLckCtlAvail_T_Stat 1;
BA_ "U_CD4_MY13_Hev_Rx" SG_ 578 PrkLckCtlAvail_T_Stat 1;
BA_ "U_CD4_MY13_Phev_Rx" SG_ 578 PrkLckCtlAvail_T_Stat 1;
BA_ "U_CD42_MY14_Diesel_Rx" SG_ 578 PrkLckCtlAvail_T_Stat 1;
BA_ "U_CD42_MY14_Gas_Rx" SG_ 578 PrkLckCtlAvail_T_Stat 1;
BA_ "U_P552_MY15_Gas_Rx" SG_ 578 PrkLckCtlAvail_T_Stat 1;
BA_ "U_S550_MY15_Gas_Rx" SG_ 578 PrkLckCtlAvail_T_Stat 1;
BA_ "U_C489_MY14_Gas_Rx" SG_ 578 PrkLckCtlAvail_T_Stat 1;
BA_ "U_U502_MY15_Gas_Rx" SG_ 578 PrkLckCtlAvail_T_Stat 1;
BA_ "U_B479_MY15_Gas_Rx" SG_ 578 PrkLckCtlAvail_T_Stat 1;
BA_ "U_UP375_MY15_Gas_Rx" SG_ 578 PrkLckCtlAvail_T_Stat 1;
BA_ "U_UP375_MY15_Diesel_Rx" SG_ 578 PrkLckCtlAvail_T_Stat 1;
BA_ "U_CD4_MY13_Diesel_Tx" SG_ 578 PrkLckCtlAvail_T_Stat 1;
BA_ "U_CD4_MY13_Gas_Tx" SG_ 578 PrkLckCtlAvail_T_Stat 1;
BA_ "U_CD4_MY13_Hev_Tx" SG_ 578 PrkLckCtlAvail_T_Stat 1;
BA_ "U_CD4_MY13_Phev_Tx" SG_ 578 PrkLckCtlAvail_T_Stat 1;
BA_ "U_CD42_MY14_Diesel_Tx" SG_ 578 PrkLckCtlAvail_T_Stat 1;
BA_ "U_CD42_MY14_Gas_Tx" SG_ 578 PrkLckCtlAvail_T_Stat 1;
BA_ "U_P552_MY15_Gas_Tx" SG_ 578 PrkLckCtlAvail_T_Stat 1;
BA_ "U_S550_MY15_Gas_Tx" SG_ 578 PrkLckCtlAvail_T_Stat 1;
BA_ "U_C489_MY14_Gas_Tx" SG_ 578 PrkLckCtlAvail_T_Stat 1;
BA_ "U_U502_MY15_Gas_Tx" SG_ 578 PrkLckCtlAvail_T_Stat 1;
BA_ "U_UP375_MY15_Gas_Tx" SG_ 578 PrkLckCtlAvail_T_Stat 1;
BA_ "U_UP375_MY15_Diesel_Tx" SG_ 578 PrkLckCtlAvail_T_Stat 1;
BA_ "U_CD43_MY16_Gas_Tx" SG_ 578 PrkLckCtlAvail_T_Stat 1;
BA_ "U_CD4_MY14_Diesel_Tx" SG_ 578 PrkLckCtlAvail_T_Stat 1;
BA_ "U_CD4_MY14_Gas_Tx" SG_ 578 PrkLckCtlAvail_T_Stat 1;
BA_ "U_CD4_MY14_Hev_Tx" SG_ 578 PrkLckCtlAvail_T_Stat 1;
BA_ "U_CD4_MY14_Phev_Tx" SG_ 578 PrkLckCtlAvail_T_Stat 1;
BA_ "U_CD4_MY13_Diesel_Tx" SG_ 578 BrkTrnShifLck_B_Stat 1;
BA_ "U_CD4_MY13_Gas_Tx" SG_ 578 BrkTrnShifLck_B_Stat 1;
BA_ "U_CD4_MY13_Hev_Tx" SG_ 578 BrkTrnShifLck_B_Stat 1;
BA_ "U_CD4_MY13_Phev_Tx" SG_ 578 BrkTrnShifLck_B_Stat 1;
BA_ "U_CD42_MY14_Diesel_Tx" SG_ 578 BrkTrnShifLck_B_Stat 1;
BA_ "U_CD42_MY14_Gas_Tx" SG_ 578 BrkTrnShifLck_B_Stat 1;
BA_ "U_P552_MY15_Gas_Tx" SG_ 578 BrkTrnShifLck_B_Stat 1;
BA_ "U_S550_MY15_Gas_Tx" SG_ 578 BrkTrnShifLck_B_Stat 1;
BA_ "U_C489_MY14_Gas_Tx" SG_ 578 BrkTrnShifLck_B_Stat 1;
BA_ "U_U502_MY15_Gas_Tx" SG_ 578 BrkTrnShifLck_B_Stat 1;
BA_ "U_UP375_MY15_Gas_Tx" SG_ 578 BrkTrnShifLck_B_Stat 1;
BA_ "U_UP375_MY15_Diesel_Tx" SG_ 578 BrkTrnShifLck_B_Stat 1;
BA_ "U_CD43_MY16_Gas_Tx" SG_ 578 BrkTrnShifLck_B_Stat 1;
BA_ "U_CD4_MY14_Diesel_Tx" SG_ 578 BrkTrnShifLck_B_Stat 1;
BA_ "U_CD4_MY14_Gas_Tx" SG_ 578 BrkTrnShifLck_B_Stat 1;
BA_ "U_CD4_MY14_Hev_Tx" SG_ 578 BrkTrnShifLck_B_Stat 1;
BA_ "U_CD4_MY14_Phev_Tx" SG_ 578 BrkTrnShifLck_B_Stat 1;
BA_ "U_P552_MY15_Gas_Tx" SG_ 578 PrkLckCtlUnlck_D_Stat 1;
BA_ "U_S550_MY15_Gas_Tx" SG_ 578 PrkLckCtlUnlck_D_Stat 1;
BA_ "U_C489_MY14_Gas_Tx" SG_ 578 PrkLckCtlUnlck_D_Stat 1;
BA_ "U_CD43_MY16_Gas_Tx" SG_ 578 PrkLckCtlUnlck_D_Stat 1;
BA_ "U_CD4_MY14_Diesel_Tx" SG_ 578 PrkLckCtlUnlck_D_Stat 1;
BA_ "U_CD4_MY14_Gas_Tx" SG_ 578 PrkLckCtlUnlck_D_Stat 1;
BA_ "U_CD4_MY14_Hev_Tx" SG_ 578 PrkLckCtlUnlck_D_Stat 1;
BA_ "U_CD4_MY14_Phev_Tx" SG_ 578 PrkLckCtlUnlck_D_Stat 1;
BA_ "U_P552_MY15_Gas_Tx" SG_ 578 PrkLckCtlTow_B_Enbl 1;
BA_ "U_S550_MY15_Gas_Tx" SG_ 578 PrkLckCtlTow_B_Enbl 1;
BA_ "U_C489_MY14_Gas_Tx" SG_ 578 PrkLckCtlTow_B_Enbl 1;
BA_ "U_CD43_MY16_Gas_Tx" SG_ 578 PrkLckCtlTow_B_Enbl 1;
BA_ "U_CD4_MY14_Diesel_Tx" SG_ 578 PrkLckCtlTow_B_Enbl 1;
BA_ "U_CD4_MY14_Gas_Tx" SG_ 578 PrkLckCtlTow_B_Enbl 1;
BA_ "U_CD4_MY14_Hev_Tx" SG_ 578 PrkLckCtlTow_B_Enbl 1;
BA_ "U_CD4_MY14_Phev_Tx" SG_ 578 PrkLckCtlTow_B_Enbl 1;
BA_ "U_CD42_MY14_Gas_Rx" SG_ 578 DriverCrankingReq 1;
BA_ "U_P552_MY15_Gas_Rx" SG_ 578 DriverCrankingReq 1;
BA_ "U_S550_MY15_Gas_Rx" SG_ 578 DriverCrankingReq 1;
BA_ "U_C489_MY14_Gas_Rx" SG_ 578 DriverCrankingReq 1;
BA_ "U_U502_MY15_Gas_Rx" SG_ 578 DriverCrankingReq 1;
BA_ "U_UP375_MY15_Gas_Rx" SG_ 578 DriverCrankingReq 1;
BA_ "U_CD43_MY16_Gas_Rx" SG_ 578 DriverCrankingReq 1;
BA_ "U_CD4_MY14_Gas_Rx" SG_ 578 DriverCrankingReq 1;
BA_ "U_CD4_MY13_Diesel_Tx" SG_ 578 DriverCrankingReq 1;
BA_ "U_CD4_MY13_Gas_Tx" SG_ 578 DriverCrankingReq 1;
BA_ "U_CD4_MY13_Hev_Tx" SG_ 578 DriverCrankingReq 1;
BA_ "U_CD4_MY13_Phev_Tx" SG_ 578 DriverCrankingReq 1;
BA_ "U_CD42_MY14_Diesel_Tx" SG_ 578 DriverCrankingReq 1;
BA_ "U_CD42_MY14_Gas_Tx" SG_ 578 DriverCrankingReq 1;
BA_ "U_P552_MY15_Gas_Tx" SG_ 578 DriverCrankingReq 1;
BA_ "U_S550_MY15_Gas_Tx" SG_ 578 DriverCrankingReq 1;
BA_ "U_C489_MY14_Gas_Tx" SG_ 578 DriverCrankingReq 1;
BA_ "U_U502_MY15_Gas_Tx" SG_ 578 DriverCrankingReq 1;
BA_ "U_UP375_MY15_Gas_Tx" SG_ 578 DriverCrankingReq 1;
BA_ "U_UP375_MY15_Diesel_Tx" SG_ 578 DriverCrankingReq 1;
BA_ "U_CD43_MY16_Gas_Tx" SG_ 578 DriverCrankingReq 1;
BA_ "U_CD4_MY14_Diesel_Tx" SG_ 578 DriverCrankingReq 1;
BA_ "U_CD4_MY14_Gas_Tx" SG_ 578 DriverCrankingReq 1;
BA_ "U_CD4_MY14_Hev_Tx" SG_ 578 DriverCrankingReq 1;
BA_ "U_CD4_MY14_Phev_Tx" SG_ 578 DriverCrankingReq 1;
BA_ "U_CD4_MY13_Gas_Rx" SG_ 578 EngOff_T_Actl 1;
BA_ "U_CD42_MY14_Gas_Rx" SG_ 578 EngOff_T_Actl 1;
BA_ "U_P552_MY15_Gas_Rx" SG_ 578 EngOff_T_Actl 1;
BA_ "U_S550_MY15_Gas_Rx" SG_ 578 EngOff_T_Actl 1;
BA_ "U_C489_MY14_Gas_Rx" SG_ 578 EngOff_T_Actl 1;
BA_ "U_U502_MY15_Gas_Rx" SG_ 578 EngOff_T_Actl 1;
BA_ "U_UP375_MY15_Gas_Rx" SG_ 578 EngOff_T_Actl 1;
BA_ "U_CD43_MY16_Gas_Rx" SG_ 578 EngOff_T_Actl 1;
BA_ "U_CD4_MY14_Gas_Rx" SG_ 578 EngOff_T_Actl 1;
BA_ "U_CD4_MY13_Diesel_Tx" SG_ 578 EngOff_T_Actl 1;
BA_ "U_CD4_MY13_Gas_Tx" SG_ 578 EngOff_T_Actl 1;
BA_ "U_CD4_MY13_Hev_Tx" SG_ 578 EngOff_T_Actl 1;
BA_ "U_CD4_MY13_Phev_Tx" SG_ 578 EngOff_T_Actl 1;
BA_ "U_CD42_MY14_Diesel_Tx" SG_ 578 EngOff_T_Actl 1;
BA_ "U_CD42_MY14_Gas_Tx" SG_ 578 EngOff_T_Actl 1;
BA_ "U_P552_MY15_Gas_Tx" SG_ 578 EngOff_T_Actl 1;
BA_ "U_S550_MY15_Gas_Tx" SG_ 578 EngOff_T_Actl 1;
BA_ "U_C489_MY14_Gas_Tx" SG_ 578 EngOff_T_Actl 1;
BA_ "U_U502_MY15_Gas_Tx" SG_ 578 EngOff_T_Actl 1;
BA_ "U_UP375_MY15_Gas_Tx" SG_ 578 EngOff_T_Actl 1;
BA_ "U_UP375_MY15_Diesel_Tx" SG_ 578 EngOff_T_Actl 1;
BA_ "U_CD43_MY16_Gas_Tx" SG_ 578 EngOff_T_Actl 1;
BA_ "U_CD4_MY14_Diesel_Tx" SG_ 578 EngOff_T_Actl 1;
BA_ "U_CD4_MY14_Gas_Tx" SG_ 578 EngOff_T_Actl 1;
BA_ "U_CD4_MY14_Hev_Tx" SG_ 578 EngOff_T_Actl 1;
BA_ "U_CD4_MY14_Phev_Tx" SG_ 578 EngOff_T_Actl 1;
BA_ "GenSigTimeoutTime_TCM" SG_ 578 EngOff_T_Actl 120;
BA_ "U_CD42_MY14_Gas_Rx" SG_ 578 DcacElPw_D_Rq 1;
BA_ "U_P552_MY15_Gas_Rx" SG_ 578 DcacElPw_D_Rq 1;
BA_ "U_U502_MY15_Gas_Rx" SG_ 578 DcacElPw_D_Rq 1;
BA_ "U_CD43_MY16_Gas_Rx" SG_ 578 DcacElPw_D_Rq 1;
BA_ "U_CD4_MY14_Gas_Rx" SG_ 578 DcacElPw_D_Rq 1;
BA_ "U_CD4_MY13_Diesel_Tx" SG_ 578 DcacElPw_D_Rq 1;
BA_ "U_CD4_MY13_Gas_Tx" SG_ 578 DcacElPw_D_Rq 1;
BA_ "U_CD4_MY13_Hev_Tx" SG_ 578 DcacElPw_D_Rq 1;
BA_ "U_CD4_MY13_Phev_Tx" SG_ 578 DcacElPw_D_Rq 1;
BA_ "U_CD42_MY14_Diesel_Tx" SG_ 578 DcacElPw_D_Rq 1;
BA_ "U_CD42_MY14_Gas_Tx" SG_ 578 DcacElPw_D_Rq 1;
BA_ "U_P552_MY15_Gas_Tx" SG_ 578 DcacElPw_D_Rq 1;
BA_ "U_S550_MY15_Gas_Tx" SG_ 578 DcacElPw_D_Rq 1;
BA_ "U_C489_MY14_Gas_Tx" SG_ 578 DcacElPw_D_Rq 1;
BA_ "U_U502_MY15_Gas_Tx" SG_ 578 DcacElPw_D_Rq 1;
BA_ "U_UP375_MY15_Gas_Tx" SG_ 578 DcacElPw_D_Rq 1;
BA_ "U_UP375_MY15_Diesel_Tx" SG_ 578 DcacElPw_D_Rq 1;
BA_ "U_CD43_MY16_Gas_Tx" SG_ 578 DcacElPw_D_Rq 1;
BA_ "U_CD4_MY14_Diesel_Tx" SG_ 578 DcacElPw_D_Rq 1;
BA_ "U_CD4_MY14_Gas_Tx" SG_ 578 DcacElPw_D_Rq 1;
BA_ "U_CD4_MY14_Hev_Tx" SG_ 578 DcacElPw_D_Rq 1;
BA_ "U_CD4_MY14_Phev_Tx" SG_ 578 DcacElPw_D_Rq 1;
BA_ "GenSigStartValue" SG_ 578 BattULo_I_Actl 16383;
BA_ "U_CD42_MY14_Gas_Rx" SG_ 578 BattULo_I_Actl 1;
BA_ "U_P552_MY15_Gas_Rx" SG_ 578 BattULo_I_Actl 1;
BA_ "U_S550_MY15_Gas_Rx" SG_ 578 BattULo_I_Actl 1;
BA_ "U_C489_MY14_Gas_Rx" SG_ 578 BattULo_I_Actl 1;
BA_ "U_U502_MY15_Gas_Rx" SG_ 578 BattULo_I_Actl 1;
BA_ "U_UP375_MY15_Gas_Rx" SG_ 578 BattULo_I_Actl 1;
BA_ "U_CD43_MY16_Gas_Rx" SG_ 578 BattULo_I_Actl 1;
BA_ "U_CD4_MY14_Gas_Rx" SG_ 578 BattULo_I_Actl 1;
BA_ "U_CD4_MY13_Diesel_Tx" SG_ 578 BattULo_I_Actl 1;
BA_ "U_CD4_MY13_Gas_Tx" SG_ 578 BattULo_I_Actl 1;
BA_ "U_CD4_MY13_Hev_Tx" SG_ 578 BattULo_I_Actl 1;
BA_ "U_CD4_MY13_Phev_Tx" SG_ 578 BattULo_I_Actl 1;
BA_ "U_CD42_MY14_Diesel_Tx" SG_ 578 BattULo_I_Actl 1;
BA_ "U_CD42_MY14_Gas_Tx" SG_ 578 BattULo_I_Actl 1;
BA_ "U_P552_MY15_Gas_Tx" SG_ 578 BattULo_I_Actl 1;
BA_ "U_S550_MY15_Gas_Tx" SG_ 578 BattULo_I_Actl 1;
BA_ "U_C489_MY14_Gas_Tx" SG_ 578 BattULo_I_Actl 1;
BA_ "U_U502_MY15_Gas_Tx" SG_ 578 BattULo_I_Actl 1;
BA_ "U_UP375_MY15_Gas_Tx" SG_ 578 BattULo_I_Actl 1;
BA_ "U_UP375_MY15_Diesel_Tx" SG_ 578 BattULo_I_Actl 1;
BA_ "U_CD43_MY16_Gas_Tx" SG_ 578 BattULo_I_Actl 1;
BA_ "U_CD4_MY14_Diesel_Tx" SG_ 578 BattULo_I_Actl 1;
BA_ "U_CD4_MY14_Gas_Tx" SG_ 578 BattULo_I_Actl 1;
BA_ "U_CD4_MY14_Hev_Tx" SG_ 578 BattULo_I_Actl 1;
BA_ "U_CD4_MY14_Phev_Tx" SG_ 578 BattULo_I_Actl 1;
BA_ "U_P552_MY15_Gas_Rx" SG_ 514 StrtrMtrDlyStrt_B_Stat 1;
BA_ "U_S550_MY15_Gas_Rx" SG_ 514 StrtrMtrDlyStrt_B_Stat 1;
BA_ "U_C489_MY14_Gas_Rx" SG_ 514 StrtrMtrDlyStrt_B_Stat 1;
BA_ "U_CD43_MY16_Gas_Rx" SG_ 514 StrtrMtrDlyStrt_B_Stat 1;
BA_ "U_CD4_MY14_Diesel_Rx" SG_ 514 StrtrMtrDlyStrt_B_Stat 1;
BA_ "U_CD4_MY14_Gas_Rx" SG_ 514 StrtrMtrDlyStrt_B_Stat 1;
BA_ "U_CD4_MY14_Hev_Rx" SG_ 514 StrtrMtrDlyStrt_B_Stat 1;
BA_ "U_CD4_MY14_Phev_Rx" SG_ 514 StrtrMtrDlyStrt_B_Stat 1;
BA_ "U_P552_MY15_Gas_Tx" SG_ 514 StrtrMtrDlyStrt_B_Stat 1;
BA_ "U_S550_MY15_Gas_Tx" SG_ 514 StrtrMtrDlyStrt_B_Stat 1;
BA_ "U_C489_MY14_Gas_Tx" SG_ 514 StrtrMtrDlyStrt_B_Stat 1;
BA_ "U_CD43_MY16_Gas_Tx" SG_ 514 StrtrMtrDlyStrt_B_Stat 1;
BA_ "U_P552_MY15_Gas_Tx" SG_ 514 VehVTrlrAid_B_Avail 1;
BA_ "CrossOver_InfoCAN" SG_ 514 StrtrMtrCtlMsgTxt_D_Rq 1;
BA_ "U_CD4_MY13_Gas_Tx" SG_ 514 StrtrMtrCtlMsgTxt_D_Rq 1;
BA_ "U_CD42_MY14_Gas_Tx" SG_ 514 StrtrMtrCtlMsgTxt_D_Rq 1;
BA_ "U_P552_MY15_Gas_Tx" SG_ 514 StrtrMtrCtlMsgTxt_D_Rq 1;
BA_ "U_S550_MY15_Gas_Tx" SG_ 514 StrtrMtrCtlMsgTxt_D_Rq 1;
BA_ "U_C489_MY14_Gas_Tx" SG_ 514 StrtrMtrCtlMsgTxt_D_Rq 1;
BA_ "U_U502_MY15_Gas_Tx" SG_ 514 StrtrMtrCtlMsgTxt_D_Rq 1;
BA_ "U_UP375_MY15_Gas_Tx" SG_ 514 StrtrMtrCtlMsgTxt_D_Rq 1;
BA_ "U_CD43_MY16_Gas_Tx" SG_ 514 StrtrMtrCtlMsgTxt_D_Rq 1;
BA_ "U_CD4_MY14_Gas_Tx" SG_ 514 StrtrMtrCtlMsgTxt_D_Rq 1;
BA_ "CrossOver_InfoCAN" SG_ 514 VehVActlEng_No_Cs 1;
BA_ "U_CD4_MY13_Gas_Tx" SG_ 514 VehVActlEng_No_Cs 1;
BA_ "U_CD42_MY14_Gas_Tx" SG_ 514 VehVActlEng_No_Cs 1;
BA_ "U_P552_MY15_Gas_Tx" SG_ 514 VehVActlEng_No_Cs 1;
BA_ "U_S550_MY15_Gas_Tx" SG_ 514 VehVActlEng_No_Cs 1;
BA_ "U_C489_MY14_Gas_Tx" SG_ 514 VehVActlEng_No_Cs 1;
BA_ "U_U502_MY15_Gas_Tx" SG_ 514 VehVActlEng_No_Cs 1;
BA_ "U_UP375_MY15_Gas_Tx" SG_ 514 VehVActlEng_No_Cs 1;
BA_ "U_CD43_MY16_Gas_Tx" SG_ 514 VehVActlEng_No_Cs 1;
BA_ "U_CD4_MY14_Gas_Tx" SG_ 514 VehVActlEng_No_Cs 1;
BA_ "CrossOver_InfoCAN" SG_ 514 VehVActlEng_No_Cnt 1;
BA_ "U_CD4_MY13_Gas_Tx" SG_ 514 VehVActlEng_No_Cnt 1;
BA_ "U_CD42_MY14_Gas_Tx" SG_ 514 VehVActlEng_No_Cnt 1;
BA_ "U_P552_MY15_Gas_Tx" SG_ 514 VehVActlEng_No_Cnt 1;
BA_ "U_S550_MY15_Gas_Tx" SG_ 514 VehVActlEng_No_Cnt 1;
BA_ "U_C489_MY14_Gas_Tx" SG_ 514 VehVActlEng_No_Cnt 1;
BA_ "U_U502_MY15_Gas_Tx" SG_ 514 VehVActlEng_No_Cnt 1;
BA_ "U_UP375_MY15_Gas_Tx" SG_ 514 VehVActlEng_No_Cnt 1;
BA_ "U_CD43_MY16_Gas_Tx" SG_ 514 VehVActlEng_No_Cnt 1;
BA_ "U_CD4_MY14_Gas_Tx" SG_ 514 VehVActlEng_No_Cnt 1;
BA_ "CrossOver_InfoCAN" SG_ 514 Veh_V_RqCcSet 1;
BA_ "U_CD4_MY13_Gas_Tx" SG_ 514 Veh_V_RqCcSet 1;
BA_ "U_CD42_MY14_Gas_Tx" SG_ 514 Veh_V_RqCcSet 1;
BA_ "U_P552_MY15_Gas_Tx" SG_ 514 Veh_V_RqCcSet 1;
BA_ "U_S550_MY15_Gas_Tx" SG_ 514 Veh_V_RqCcSet 1;
BA_ "U_C489_MY14_Gas_Tx" SG_ 514 Veh_V_RqCcSet 1;
BA_ "U_U502_MY15_Gas_Tx" SG_ 514 Veh_V_RqCcSet 1;
BA_ "U_UP375_MY15_Gas_Tx" SG_ 514 Veh_V_RqCcSet 1;
BA_ "U_CD43_MY16_Gas_Tx" SG_ 514 Veh_V_RqCcSet 1;
BA_ "U_CD4_MY14_Gas_Tx" SG_ 514 Veh_V_RqCcSet 1;
BA_ "GenSigTimeoutTime_TCM" SG_ 514 Veh_V_RqCcSet 60;
BA_ "CrossOver_InfoCAN" SG_ 514 VehVActlEng_D_Qf 1;
BA_ "U_CD4_MY13_Diesel_Rx" SG_ 514 VehVActlEng_D_Qf 1;
BA_ "U_CD4_MY13_Gas_Rx" SG_ 514 VehVActlEng_D_Qf 1;
BA_ "U_CD4_MY13_Hev_Rx" SG_ 514 VehVActlEng_D_Qf 1;
BA_ "U_CD4_MY13_Phev_Rx" SG_ 514 VehVActlEng_D_Qf 1;
BA_ "U_CD42_MY14_Diesel_Rx" SG_ 514 VehVActlEng_D_Qf 1;
BA_ "U_CD42_MY14_Gas_Rx" SG_ 514 VehVActlEng_D_Qf 1;
BA_ "U_P552_MY15_Gas_Rx" SG_ 514 VehVActlEng_D_Qf 1;
BA_ "U_S550_MY15_Gas_Rx" SG_ 514 VehVActlEng_D_Qf 1;
BA_ "U_C489_MY14_Gas_Rx" SG_ 514 VehVActlEng_D_Qf 1;
BA_ "U_U502_MY15_Gas_Rx" SG_ 514 VehVActlEng_D_Qf 1;
BA_ "U_UP375_MY15_Gas_Rx" SG_ 514 VehVActlEng_D_Qf 1;
BA_ "U_UP375_MY15_Diesel_Rx" SG_ 514 VehVActlEng_D_Qf 1;
BA_ "U_CD43_MY16_Gas_Rx" SG_ 514 VehVActlEng_D_Qf 1;
BA_ "U_CD4_MY14_Diesel_Rx" SG_ 514 VehVActlEng_D_Qf 1;
BA_ "U_CD4_MY14_Gas_Rx" SG_ 514 VehVActlEng_D_Qf 1;
BA_ "U_CD4_MY14_Hev_Rx" SG_ 514 VehVActlEng_D_Qf 1;
BA_ "U_CD4_MY14_Phev_Rx" SG_ 514 VehVActlEng_D_Qf 1;
BA_ "U_CD4_MY13_Gas_Tx" SG_ 514 VehVActlEng_D_Qf 1;
BA_ "U_CD42_MY14_Gas_Tx" SG_ 514 VehVActlEng_D_Qf 1;
BA_ "U_P552_MY15_Gas_Tx" SG_ 514 VehVActlEng_D_Qf 1;
BA_ "U_S550_MY15_Gas_Tx" SG_ 514 VehVActlEng_D_Qf 1;
BA_ "U_C489_MY14_Gas_Tx" SG_ 514 VehVActlEng_D_Qf 1;
BA_ "U_U502_MY15_Gas_Tx" SG_ 514 VehVActlEng_D_Qf 1;
BA_ "U_UP375_MY15_Gas_Tx" SG_ 514 VehVActlEng_D_Qf 1;
BA_ "U_CD43_MY16_Gas_Tx" SG_ 514 VehVActlEng_D_Qf 1;
BA_ "U_CD4_MY14_Gas_Tx" SG_ 514 VehVActlEng_D_Qf 1;
BA_ "GenSigTimeoutTime_TCM" SG_ 514 VehVActlEng_D_Qf 60;
BA_ "U_CD42_MY15_Diesel_Rx" SG_ 514 Veh_V_ActlEng 1;
BA_ "U_CD42_MY15_Gas_Rx" SG_ 514 Veh_V_ActlEng 1;
BA_ "U_U502_MY16_Gas_Rx" SG_ 514 Veh_V_ActlEng 1;
BA_ "U_CD4_MY17_Diesel_Rx" SG_ 514 Veh_V_ActlEng 1;
BA_ "U_CD4_MY17_Gas_Rx" SG_ 514 Veh_V_ActlEng 1;
BA_ "U_CD4_MY17_Hev_Rx" SG_ 514 Veh_V_ActlEng 1;
BA_ "U_CD4_MY17_Phev_Rx" SG_ 514 Veh_V_ActlEng 1;
BA_ "U_P558_MY17_Gas_Rx" SG_ 514 Veh_V_ActlEng 1;
BA_ "U_P558_MY17_Diesel_Rx" SG_ 514 Veh_V_ActlEng 1;
BA_ "U_V36X_MY16_5_Diesel_Rx" SG_ 514 Veh_V_ActlEng 1;
BA_ "U_C489_MY17_Gas_Rx" SG_ 514 Veh_V_ActlEng 1;
BA_ "U_CD42_MY16_Diesel_Rx" SG_ 514 Veh_V_ActlEng 1;
BA_ "U_CD42_MY16_Gas_Rx" SG_ 514 Veh_V_ActlEng 1;
BA_ "U_CD43_MY17_Gas_Rx" SG_ 514 Veh_V_ActlEng 1;
BA_ "U_P552_MY17_Gas_Rx" SG_ 514 Veh_V_ActlEng 1;
BA_ "U_B515_MCA_MY17_Diesel_Rx" SG_ 514 Veh_V_ActlEng 1;
BA_ "U_B515_MCA_MY17_Gas_Rx" SG_ 514 Veh_V_ActlEng 1;
BA_ "U_U55x_MY18_Gas_Rx" SG_ 514 Veh_V_ActlEng 1;
BA_ "U_U502_MY16_Gas_Tx" SG_ 514 Veh_V_ActlEng 1;
BA_ "U_UP375_MY15_Diesel_Tx" SG_ 514 Veh_V_ActlEng 1;
BA_ "U_CD4_MY14_Diesel_Tx" SG_ 514 Veh_V_ActlEng 1;
BA_ "U_CD4_MY14_Hev_Tx" SG_ 514 Veh_V_ActlEng 1;
BA_ "U_CD4_MY14_Phev_Tx" SG_ 514 Veh_V_ActlEng 1;
BA_ "U_CD4_MY17_Gas_Tx" SG_ 514 Veh_V_ActlEng 1;
BA_ "U_CD4_MY17_Hev_Tx" SG_ 514 Veh_V_ActlEng 1;
BA_ "U_CD4_MY17_Phev_Tx" SG_ 514 Veh_V_ActlEng 1;
BA_ "U_P558_MY17_Gas_Tx" SG_ 514 Veh_V_ActlEng 1;
BA_ "U_P558_MY17_Diesel_Tx" SG_ 514 Veh_V_ActlEng 1;
BA_ "U_V36X_MY16_5_Diesel_Tx" SG_ 514 Veh_V_ActlEng 1;
BA_ "U_C489_MY17_Gas_Tx" SG_ 514 Veh_V_ActlEng 1;
BA_ "U_CD42_MY16_Diesel_Tx" SG_ 514 Veh_V_ActlEng 1;
BA_ "U_CD42_MY16_Gas_Tx" SG_ 514 Veh_V_ActlEng 1;
BA_ "U_CD43_MY17_Gas_Tx" SG_ 514 Veh_V_ActlEng 1;
BA_ "U_P552_MY17_Gas_Tx" SG_ 514 Veh_V_ActlEng 1;
BA_ "U_B515_MCA_MY17_Diesel_Tx" SG_ 514 Veh_V_ActlEng 1;
BA_ "U_B515_MCA_MY17_Gas_Tx" SG_ 514 Veh_V_ActlEng 1;
BA_ "U_U55x_MY18_Gas_Tx" SG_ 514 Veh_V_ActlEng 1;
BA_ "CrossOver_InfoCAN" SG_ 514 Veh_V_ActlEng 1;
BA_ "CrossOver_LIN" SG_ 514 Veh_V_ActlEng 1;
BA_ "U_CD4_MY13_Diesel_Rx" SG_ 514 Veh_V_ActlEng 1;
BA_ "U_CD4_MY13_Gas_Rx" SG_ 514 Veh_V_ActlEng 1;
BA_ "U_CD4_MY13_Hev_Rx" SG_ 514 Veh_V_ActlEng 1;
BA_ "U_CD4_MY13_Phev_Rx" SG_ 514 Veh_V_ActlEng 1;
BA_ "U_CD42_MY14_Diesel_Rx" SG_ 514 Veh_V_ActlEng 1;
BA_ "U_CD42_MY14_Gas_Rx" SG_ 514 Veh_V_ActlEng 1;
BA_ "U_P552_MY15_Gas_Rx" SG_ 514 Veh_V_ActlEng 1;
BA_ "U_S550_MY15_Gas_Rx" SG_ 514 Veh_V_ActlEng 1;
BA_ "U_C489_MY14_Gas_Rx" SG_ 514 Veh_V_ActlEng 1;
BA_ "U_U502_MY15_Gas_Rx" SG_ 514 Veh_V_ActlEng 1;
BA_ "U_UP375_MY15_Gas_Rx" SG_ 514 Veh_V_ActlEng 1;
BA_ "U_UP375_MY15_Diesel_Rx" SG_ 514 Veh_V_ActlEng 1;
BA_ "U_CD43_MY16_Gas_Rx" SG_ 514 Veh_V_ActlEng 1;
BA_ "U_CD4_MY14_Diesel_Rx" SG_ 514 Veh_V_ActlEng 1;
BA_ "U_CD4_MY14_Gas_Rx" SG_ 514 Veh_V_ActlEng 1;
BA_ "U_CD4_MY14_Hev_Rx" SG_ 514 Veh_V_ActlEng 1;
BA_ "U_CD4_MY14_Phev_Rx" SG_ 514 Veh_V_ActlEng 1;
BA_ "U_CD4_MY13_Hev_Tx" SG_ 514 Veh_V_ActlEng 1;
BA_ "U_CD4_MY13_Phev_Tx" SG_ 514 Veh_V_ActlEng 1;
BA_ "U_CD42_MY14_Gas_Tx" SG_ 514 Veh_V_ActlEng 1;
BA_ "U_U502_MY15_Gas_Tx" SG_ 514 Veh_V_ActlEng 1;
BA_ "U_UP375_MY15_Gas_Tx" SG_ 514 Veh_V_ActlEng 1;
BA_ "U_CD43_MY16_Gas_Tx" SG_ 514 Veh_V_ActlEng 1;
BA_ "U_CD4_MY14_Gas_Tx" SG_ 514 Veh_V_ActlEng 1;
BA_ "GenSigTimeoutTime_TCM" SG_ 514 Veh_V_ActlEng 60;
BA_ "GenSigMissingSourceValue" SG_ 514 GearRvrse_D_Actl 3;
BA_ "CrossOver_InfoCAN" SG_ 514 GearRvrse_D_Actl 1;
BA_ "GenSigStartValue" SG_ 514 GearRvrse_D_Actl 7;
BA_ "U_CD4_MY13_Phev_Rx" SG_ 514 GearRvrse_D_Actl 1;
BA_ "U_CD42_MY14_Diesel_Rx" SG_ 514 GearRvrse_D_Actl 1;
BA_ "U_CD42_MY14_Gas_Rx" SG_ 514 GearRvrse_D_Actl 1;
BA_ "U_P552_MY15_Gas_Rx" SG_ 514 GearRvrse_D_Actl 1;
BA_ "U_S550_MY15_Gas_Rx" SG_ 514 GearRvrse_D_Actl 1;
BA_ "U_C489_MY14_Gas_Rx" SG_ 514 GearRvrse_D_Actl 1;
BA_ "U_U502_MY15_Gas_Rx" SG_ 514 GearRvrse_D_Actl 1;
BA_ "U_UP375_MY15_Gas_Rx" SG_ 514 GearRvrse_D_Actl 1;
BA_ "U_UP375_MY15_Diesel_Rx" SG_ 514 GearRvrse_D_Actl 1;
BA_ "U_CD43_MY16_Gas_Rx" SG_ 514 GearRvrse_D_Actl 1;
BA_ "U_CD4_MY14_Diesel_Rx" SG_ 514 GearRvrse_D_Actl 1;
BA_ "U_CD4_MY14_Gas_Rx" SG_ 514 GearRvrse_D_Actl 1;
BA_ "U_CD4_MY14_Hev_Rx" SG_ 514 GearRvrse_D_Actl 1;
BA_ "U_CD4_MY14_Phev_Rx" SG_ 514 GearRvrse_D_Actl 1;
BA_ "U_CD4_MY13_Gas_Tx" SG_ 514 GearRvrse_D_Actl 1;
BA_ "U_CD42_MY14_Gas_Tx" SG_ 514 GearRvrse_D_Actl 1;
BA_ "U_P552_MY15_Gas_Tx" SG_ 514 GearRvrse_D_Actl 1;
BA_ "U_S550_MY15_Gas_Tx" SG_ 514 GearRvrse_D_Actl 1;
BA_ "U_C489_MY14_Gas_Tx" SG_ 514 GearRvrse_D_Actl 1;
BA_ "U_U502_MY15_Gas_Tx" SG_ 514 GearRvrse_D_Actl 1;
BA_ "U_UP375_MY15_Gas_Tx" SG_ 514 GearRvrse_D_Actl 1;
BA_ "U_CD43_MY16_Gas_Tx" SG_ 514 GearRvrse_D_Actl 1;
BA_ "U_CD4_MY14_Gas_Tx" SG_ 514 GearRvrse_D_Actl 1;
BA_ "U_CD42_MY16_Diesel_Tx" SG_ 1057 VehVLimStat_D_Actl 1;
BA_ "U_V36X_MY16_5_Diesel_Tx" SG_ 1057 VehVLimStat_D_Actl 1;
BA_ "U_P558_MY17_Diesel_Tx" SG_ 1057 VehVLimStat_D_Actl 1;
BA_ "U_CD4_MY14_Diesel_Tx" SG_ 1057 VehVLimStat_D_Actl 1;
BA_ "U_UP375_MY15_Diesel_Tx" SG_ 1057 VehVLimStat_D_Actl 1;
BA_ "U_CD42_MY16_Diesel_Rx" SG_ 1057 VehVLimStat_D_Actl 1;
BA_ "U_V36X_MY16_5_Diesel_Rx" SG_ 1057 VehVLimStat_D_Actl 1;
BA_ "U_P558_MY17_Diesel_Rx" SG_ 1057 VehVLimStat_D_Actl 1;
BA_ "U_CD4_MY17_Diesel_Rx" SG_ 1057 VehVLimStat_D_Actl 1;
BA_ "U_CD4_MY14_Diesel_Rx" SG_ 1057 VehVLimStat_D_Actl 1;
BA_ "U_UP375_MY15_Diesel_Rx" SG_ 1057 VehVLimStat_D_Actl 1;
BA_ "U_CD42_MY15_Diesel_Rx" SG_ 1057 VehVLimStat_D_Actl 1;
BA_ "ContentDependant" SG_ 1057 VehVLimStat_D_Actl 1;
BA_ "CrossOver_InfoCAN" SG_ 1057 VehVLimStat_D_Actl 1;
BA_ "GenSigTimeoutTime_TCM" SG_ 1057 VehVLimStat_D_Actl 300;
BA_ "U_CD42_MY16_Diesel_Tx" SG_ 1057 VehVLimActv_B_Actl 1;
BA_ "U_V36X_MY16_5_Diesel_Tx" SG_ 1057 VehVLimActv_B_Actl 1;
BA_ "U_P558_MY17_Diesel_Tx" SG_ 1057 VehVLimActv_B_Actl 1;
BA_ "U_CD4_MY14_Diesel_Tx" SG_ 1057 VehVLimActv_B_Actl 1;
BA_ "U_UP375_MY15_Diesel_Tx" SG_ 1057 VehVLimActv_B_Actl 1;
BA_ "U_CD42_MY16_Diesel_Rx" SG_ 1057 VehVLimActv_B_Actl 1;
BA_ "U_V36X_MY16_5_Diesel_Rx" SG_ 1057 VehVLimActv_B_Actl 1;
BA_ "U_P558_MY17_Diesel_Rx" SG_ 1057 VehVLimActv_B_Actl 1;
BA_ "U_CD4_MY17_Diesel_Rx" SG_ 1057 VehVLimActv_B_Actl 1;
BA_ "U_CD4_MY14_Diesel_Rx" SG_ 1057 VehVLimActv_B_Actl 1;
BA_ "U_UP375_MY15_Diesel_Rx" SG_ 1057 VehVLimActv_B_Actl 1;
BA_ "U_CD42_MY15_Diesel_Rx" SG_ 1057 VehVLimActv_B_Actl 1;
BA_ "ContentDependant" SG_ 1057 VehVLimActv_B_Actl 1;
BA_ "CrossOver_InfoCAN" SG_ 1057 VehVLimActv_B_Actl 1;
BA_ "GenSigTimeoutTime_TCM" SG_ 1057 VehVLimActv_B_Actl 300;
BA_ "U_CD4_MY13_Diesel_Rx" SG_ 1057 EngIdlShutDwnTxt_D_Rq 1;
BA_ "U_CD4_MY13_Gas_Rx" SG_ 1057 EngIdlShutDwnTxt_D_Rq 1;
BA_ "U_CD4_MY13_Hev_Rx" SG_ 1057 EngIdlShutDwnTxt_D_Rq 1;
BA_ "U_CD4_MY13_Gas_Tx" SG_ 1057 EngIdlShutDwnTxt_D_Rq 1;
BA_ "U_CD42_MY14_Gas_Tx" SG_ 1057 EngIdlShutDwnTxt_D_Rq 1;
BA_ "U_P552_MY15_Gas_Tx" SG_ 1057 EngIdlShutDwnTxt_D_Rq 1;
BA_ "U_S550_MY15_Gas_Tx" SG_ 1057 EngIdlShutDwnTxt_D_Rq 1;
BA_ "U_C489_MY14_Gas_Tx" SG_ 1057 EngIdlShutDwnTxt_D_Rq 1;
BA_ "U_U502_MY15_Gas_Tx" SG_ 1057 EngIdlShutDwnTxt_D_Rq 1;
BA_ "U_UP375_MY15_Gas_Tx" SG_ 1057 EngIdlShutDwnTxt_D_Rq 1;
BA_ "U_CD43_MY16_Gas_Tx" SG_ 1057 EngIdlShutDwnTxt_D_Rq 1;
BA_ "U_CD4_MY14_Gas_Tx" SG_ 1057 EngIdlShutDwnTxt_D_Rq 1;
BA_ "CrossOver_InfoCAN" SG_ 1057 EngIdlShutDown_D_Stat 1;
BA_ "ContentDependant" SG_ 1057 EngIdlShutDown_D_Stat 1;
BA_ "U_CD4_MY13_Diesel_Rx" SG_ 1057 EngIdlShutDown_D_Stat 1;
BA_ "U_CD4_MY13_Gas_Rx" SG_ 1057 EngIdlShutDown_D_Stat 1;
BA_ "U_CD4_MY13_Hev_Rx" SG_ 1057 EngIdlShutDown_D_Stat 1;
BA_ "U_CD4_MY13_Phev_Rx" SG_ 1057 EngIdlShutDown_D_Stat 1;
BA_ "U_CD42_MY14_Diesel_Rx" SG_ 1057 EngIdlShutDown_D_Stat 1;
BA_ "U_CD42_MY14_Gas_Rx" SG_ 1057 EngIdlShutDown_D_Stat 1;
BA_ "U_P552_MY15_Gas_Rx" SG_ 1057 EngIdlShutDown_D_Stat 1;
BA_ "U_S550_MY15_Gas_Rx" SG_ 1057 EngIdlShutDown_D_Stat 1;
BA_ "U_C489_MY14_Gas_Rx" SG_ 1057 EngIdlShutDown_D_Stat 1;
BA_ "U_U502_MY15_Gas_Rx" SG_ 1057 EngIdlShutDown_D_Stat 1;
BA_ "U_UP375_MY15_Gas_Rx" SG_ 1057 EngIdlShutDown_D_Stat 1;
BA_ "U_UP375_MY15_Diesel_Rx" SG_ 1057 EngIdlShutDown_D_Stat 1;
BA_ "U_CD43_MY16_Gas_Rx" SG_ 1057 EngIdlShutDown_D_Stat 1;
BA_ "U_CD4_MY14_Diesel_Rx" SG_ 1057 EngIdlShutDown_D_Stat 1;
BA_ "U_CD4_MY14_Gas_Rx" SG_ 1057 EngIdlShutDown_D_Stat 1;
BA_ "U_CD4_MY14_Hev_Rx" SG_ 1057 EngIdlShutDown_D_Stat 1;
BA_ "U_CD4_MY14_Phev_Rx" SG_ 1057 EngIdlShutDown_D_Stat 1;
BA_ "U_CD4_MY13_Gas_Tx" SG_ 1057 EngIdlShutDown_D_Stat 1;
BA_ "U_CD42_MY14_Gas_Tx" SG_ 1057 EngIdlShutDown_D_Stat 1;
BA_ "U_P552_MY15_Gas_Tx" SG_ 1057 EngIdlShutDown_D_Stat 1;
BA_ "U_S550_MY15_Gas_Tx" SG_ 1057 EngIdlShutDown_D_Stat 1;
BA_ "U_C489_MY14_Gas_Tx" SG_ 1057 EngIdlShutDown_D_Stat 1;
BA_ "U_U502_MY15_Gas_Tx" SG_ 1057 EngIdlShutDown_D_Stat 1;
BA_ "U_UP375_MY15_Gas_Tx" SG_ 1057 EngIdlShutDown_D_Stat 1;
BA_ "U_CD43_MY16_Gas_Tx" SG_ 1057 EngIdlShutDown_D_Stat 1;
BA_ "U_CD4_MY14_Gas_Tx" SG_ 1057 EngIdlShutDown_D_Stat 1;
BA_ "CrossOver_InfoCAN" SG_ 1057 FUEL_ALCOHOL_PERCNT 1;
BA_ "GenSigStartValue" SG_ 1057 FUEL_ALCOHOL_PERCNT 255;
BA_ "ContentDependant" SG_ 1057 FUEL_ALCOHOL_PERCNT 1;
BA_ "U_CD4_MY13_Gas_Tx" SG_ 1057 FUEL_ALCOHOL_PERCNT 1;
BA_ "U_CD42_MY14_Gas_Tx" SG_ 1057 FUEL_ALCOHOL_PERCNT 1;
BA_ "U_P552_MY15_Gas_Tx" SG_ 1057 FUEL_ALCOHOL_PERCNT 1;
BA_ "U_U502_MY15_Gas_Tx" SG_ 1057 FUEL_ALCOHOL_PERCNT 1;
BA_ "U_CD43_MY16_Gas_Tx" SG_ 1057 FUEL_ALCOHOL_PERCNT 1;
BA_ "U_CD4_MY14_Gas_Tx" SG_ 1057 FUEL_ALCOHOL_PERCNT 1;
BA_ "CrossOver_InfoCAN" SG_ 1057 ECMMILRequest 1;
BA_ "U_CD4_MY13_Diesel_Rx" SG_ 1057 ECMMILRequest 1;
BA_ "U_CD4_MY13_Gas_Rx" SG_ 1057 ECMMILRequest 1;
BA_ "U_CD4_MY13_Hev_Rx" SG_ 1057 ECMMILRequest 1;
BA_ "U_CD4_MY13_Phev_Rx" SG_ 1057 ECMMILRequest 1;
BA_ "U_CD42_MY14_Diesel_Rx" SG_ 1057 ECMMILRequest 1;
BA_ "U_CD42_MY14_Gas_Rx" SG_ 1057 ECMMILRequest 1;
BA_ "U_P552_MY15_Gas_Rx" SG_ 1057 ECMMILRequest 1;
BA_ "U_S550_MY15_Gas_Rx" SG_ 1057 ECMMILRequest 1;
BA_ "U_C489_MY14_Gas_Rx" SG_ 1057 ECMMILRequest 1;
BA_ "U_U502_MY15_Gas_Rx" SG_ 1057 ECMMILRequest 1;
BA_ "U_UP375_MY15_Gas_Rx" SG_ 1057 ECMMILRequest 1;
BA_ "U_UP375_MY15_Diesel_Rx" SG_ 1057 ECMMILRequest 1;
BA_ "U_CD43_MY16_Gas_Rx" SG_ 1057 ECMMILRequest 1;
BA_ "U_CD4_MY14_Diesel_Rx" SG_ 1057 ECMMILRequest 1;
BA_ "U_CD4_MY14_Gas_Rx" SG_ 1057 ECMMILRequest 1;
BA_ "U_CD4_MY14_Hev_Rx" SG_ 1057 ECMMILRequest 1;
BA_ "U_CD4_MY14_Phev_Rx" SG_ 1057 ECMMILRequest 1;
BA_ "U_CD4_MY13_Gas_Tx" SG_ 1057 ECMMILRequest 1;
BA_ "U_CD42_MY14_Gas_Tx" SG_ 1057 ECMMILRequest 1;
BA_ "U_P552_MY15_Gas_Tx" SG_ 1057 ECMMILRequest 1;
BA_ "U_S550_MY15_Gas_Tx" SG_ 1057 ECMMILRequest 1;
BA_ "U_C489_MY14_Gas_Tx" SG_ 1057 ECMMILRequest 1;
BA_ "U_U502_MY15_Gas_Tx" SG_ 1057 ECMMILRequest 1;
BA_ "U_UP375_MY15_Gas_Tx" SG_ 1057 ECMMILRequest 1;
BA_ "U_CD43_MY16_Gas_Tx" SG_ 1057 ECMMILRequest 1;
BA_ "U_CD4_MY14_Gas_Tx" SG_ 1057 ECMMILRequest 1;
BA_ "CrossOver_InfoCAN" SG_ 1057 AirCondFluidHi_P_Actl 1;
BA_ "U_CD4_MY13_Gas_Tx" SG_ 1057 AirCondFluidHi_P_Actl 1;
BA_ "U_CD42_MY14_Gas_Tx" SG_ 1057 AirCondFluidHi_P_Actl 1;
BA_ "U_P552_MY15_Gas_Tx" SG_ 1057 AirCondFluidHi_P_Actl 1;
BA_ "U_S550_MY15_Gas_Tx" SG_ 1057 AirCondFluidHi_P_Actl 1;
BA_ "U_C489_MY14_Gas_Tx" SG_ 1057 AirCondFluidHi_P_Actl 1;
BA_ "U_U502_MY15_Gas_Tx" SG_ 1057 AirCondFluidHi_P_Actl 1;
BA_ "U_CD43_MY16_Gas_Tx" SG_ 1057 AirCondFluidHi_P_Actl 1;
BA_ "U_CD4_MY14_Gas_Tx" SG_ 1057 AirCondFluidHi_P_Actl 1;
BA_ "CrossOver_InfoCAN" SG_ 1057 OilPressureWarning 1;
BA_ "U_CD4_MY13_Gas_Tx" SG_ 1057 OilPressureWarning 1;
BA_ "U_CD42_MY14_Gas_Tx" SG_ 1057 OilPressureWarning 1;
BA_ "U_P552_MY15_Gas_Tx" SG_ 1057 OilPressureWarning 1;
BA_ "U_S550_MY15_Gas_Tx" SG_ 1057 OilPressureWarning 1;
BA_ "U_C489_MY14_Gas_Tx" SG_ 1057 OilPressureWarning 1;
BA_ "U_U502_MY15_Gas_Tx" SG_ 1057 OilPressureWarning 1;
BA_ "U_UP375_MY15_Gas_Tx" SG_ 1057 OilPressureWarning 1;
BA_ "U_CD43_MY16_Gas_Tx" SG_ 1057 OilPressureWarning 1;
BA_ "U_CD4_MY14_Gas_Tx" SG_ 1057 OilPressureWarning 1;
BA_ "CrossOver_InfoCAN" SG_ 1057 CoolantFanStepAct 1;
BA_ "U_CD4_MY13_Diesel_Rx" SG_ 1057 CoolantFanStepAct 1;
BA_ "U_CD4_MY13_Gas_Rx" SG_ 1057 CoolantFanStepAct 1;
BA_ "U_CD4_MY13_Hev_Rx" SG_ 1057 CoolantFanStepAct 1;
BA_ "U_CD4_MY13_Phev_Rx" SG_ 1057 CoolantFanStepAct 1;
BA_ "U_CD42_MY14_Diesel_Rx" SG_ 1057 CoolantFanStepAct 1;
BA_ "U_CD42_MY14_Gas_Rx" SG_ 1057 CoolantFanStepAct 1;
BA_ "U_P552_MY15_Gas_Rx" SG_ 1057 CoolantFanStepAct 1;
BA_ "U_S550_MY15_Gas_Rx" SG_ 1057 CoolantFanStepAct 1;
BA_ "U_C489_MY14_Gas_Rx" SG_ 1057 CoolantFanStepAct 1;
BA_ "U_U502_MY15_Gas_Rx" SG_ 1057 CoolantFanStepAct 1;
BA_ "U_UP375_MY15_Gas_Rx" SG_ 1057 CoolantFanStepAct 1;
BA_ "U_UP375_MY15_Diesel_Rx" SG_ 1057 CoolantFanStepAct 1;
BA_ "U_CD43_MY16_Gas_Rx" SG_ 1057 CoolantFanStepAct 1;
BA_ "U_CD4_MY14_Diesel_Rx" SG_ 1057 CoolantFanStepAct 1;
BA_ "U_CD4_MY14_Gas_Rx" SG_ 1057 CoolantFanStepAct 1;
BA_ "U_CD4_MY14_Hev_Rx" SG_ 1057 CoolantFanStepAct 1;
BA_ "U_CD4_MY14_Phev_Rx" SG_ 1057 CoolantFanStepAct 1;
BA_ "U_CD4_MY13_Gas_Tx" SG_ 1057 CoolantFanStepAct 1;
BA_ "U_CD42_MY14_Gas_Tx" SG_ 1057 CoolantFanStepAct 1;
BA_ "U_P552_MY15_Gas_Tx" SG_ 1057 CoolantFanStepAct 1;
BA_ "U_S550_MY15_Gas_Tx" SG_ 1057 CoolantFanStepAct 1;
BA_ "U_C489_MY14_Gas_Tx" SG_ 1057 CoolantFanStepAct 1;
BA_ "U_U502_MY15_Gas_Tx" SG_ 1057 CoolantFanStepAct 1;
BA_ "U_UP375_MY15_Gas_Tx" SG_ 1057 CoolantFanStepAct 1;
BA_ "U_CD43_MY16_Gas_Tx" SG_ 1057 CoolantFanStepAct 1;
BA_ "U_CD4_MY14_Gas_Tx" SG_ 1057 CoolantFanStepAct 1;
BA_ "ContentDependant" SG_ 1069 ThrPos_Pc_CalcDiag 1;
BA_ "U_CD42_MY16_Diesel_Tx" SG_ 1069 ThrPos_Pc_CalcDiag 1;
BA_ "U_V36X_MY16_5_Diesel_Tx" SG_ 1069 ThrPos_Pc_CalcDiag 1;
BA_ "U_P558_MY17_Diesel_Tx" SG_ 1069 ThrPos_Pc_CalcDiag 1;
BA_ "U_CD4_MY17_Diesel_Tx" SG_ 1069 ThrPos_Pc_CalcDiag 1;
BA_ "U_CD4_MY14_Diesel_Tx" SG_ 1069 ThrPos_Pc_CalcDiag 1;
BA_ "U_UP375_MY15_Diesel_Tx" SG_ 1069 ThrPos_Pc_CalcDiag 1;
BA_ "U_CD42_MY16_Diesel_Rx" SG_ 1069 ThrPos_Pc_CalcDiag 1;
BA_ "U_CD4_MY17_Diesel_Rx" SG_ 1069 ThrPos_Pc_CalcDiag 1;
BA_ "U_CD4_MY14_Diesel_Rx" SG_ 1069 ThrPos_Pc_CalcDiag 1;
BA_ "CrossOver_InfoCAN" SG_ 1069 ThrPos_Pc_CalcDiag 1;
BA_ "U_CD42_MY16_Diesel_Tx" SG_ 1069 EngLoad_Pc_CalcDiag 1;
BA_ "U_V36X_MY16_5_Diesel_Tx" SG_ 1069 EngLoad_Pc_CalcDiag 1;
BA_ "U_P558_MY17_Diesel_Tx" SG_ 1069 EngLoad_Pc_CalcDiag 1;
BA_ "U_CD4_MY17_Phev_Tx" SG_ 1069 EngLoad_Pc_CalcDiag 1;
BA_ "U_CD4_MY17_Hev_Tx" SG_ 1069 EngLoad_Pc_CalcDiag 1;
BA_ "U_CD4_MY14_Phev_Tx" SG_ 1069 EngLoad_Pc_CalcDiag 1;
BA_ "U_CD4_MY14_Hev_Tx" SG_ 1069 EngLoad_Pc_CalcDiag 1;
BA_ "U_CD4_MY14_Diesel_Tx" SG_ 1069 EngLoad_Pc_CalcDiag 1;
BA_ "U_UP375_MY15_Diesel_Tx" SG_ 1069 EngLoad_Pc_CalcDiag 1;
BA_ "U_CD4_MY13_Phev_Tx" SG_ 1069 EngLoad_Pc_CalcDiag 1;
BA_ "U_CD4_MY13_Hev_Tx" SG_ 1069 EngLoad_Pc_CalcDiag 1;
BA_ "U_V36X_MY16_5_Diesel_Rx" SG_ 1069 EngLoad_Pc_CalcDiag 1;
BA_ "U_P558_MY17_Diesel_Rx" SG_ 1069 EngLoad_Pc_CalcDiag 1;
BA_ "U_CD4_MY17_Phev_Rx" SG_ 1069 EngLoad_Pc_CalcDiag 1;
BA_ "U_CD4_MY17_Hev_Rx" SG_ 1069 EngLoad_Pc_CalcDiag 1;
BA_ "U_CD4_MY17_Diesel_Rx" SG_ 1069 EngLoad_Pc_CalcDiag 1;
BA_ "U_CD4_MY14_Phev_Rx" SG_ 1069 EngLoad_Pc_CalcDiag 1;
BA_ "U_CD4_MY14_Hev_Rx" SG_ 1069 EngLoad_Pc_CalcDiag 1;
BA_ "U_CD4_MY14_Diesel_Rx" SG_ 1069 EngLoad_Pc_CalcDiag 1;
BA_ "U_UP375_MY15_Diesel_Rx" SG_ 1069 EngLoad_Pc_CalcDiag 1;
BA_ "U_CD4_MY13_Phev_Rx" SG_ 1069 EngLoad_Pc_CalcDiag 1;
BA_ "U_CD4_MY13_Hev_Rx" SG_ 1069 EngLoad_Pc_CalcDiag 1;
BA_ "ContentDependant" SG_ 1069 EngLoad_Pc_CalcDiag 1;
BA_ "CrossOver_InfoCAN" SG_ 1069 EngLoad_Pc_CalcDiag 1;
BA_ "GenSigTimeoutTime_TCM" SG_ 1069 EngLoad_Pc_CalcDiag 300;
BA_ "U_CD42_MY16_Diesel_Tx" SG_ 1069 EngClnt_Te_ActlDiag 1;
BA_ "U_V36X_MY16_5_Diesel_Tx" SG_ 1069 EngClnt_Te_ActlDiag 1;
BA_ "U_P558_MY17_Diesel_Tx" SG_ 1069 EngClnt_Te_ActlDiag 1;
BA_ "U_CD4_MY17_Phev_Tx" SG_ 1069 EngClnt_Te_ActlDiag 1;
BA_ "U_CD4_MY17_Hev_Tx" SG_ 1069 EngClnt_Te_ActlDiag 1;
BA_ "U_CD4_MY14_Phev_Tx" SG_ 1069 EngClnt_Te_ActlDiag 1;
BA_ "U_CD4_MY14_Hev_Tx" SG_ 1069 EngClnt_Te_ActlDiag 1;
BA_ "U_CD4_MY14_Diesel_Tx" SG_ 1069 EngClnt_Te_ActlDiag 1;
BA_ "U_UP375_MY15_Diesel_Tx" SG_ 1069 EngClnt_Te_ActlDiag 1;
BA_ "U_CD4_MY13_Phev_Tx" SG_ 1069 EngClnt_Te_ActlDiag 1;
BA_ "U_CD4_MY13_Hev_Tx" SG_ 1069 EngClnt_Te_ActlDiag 1;
BA_ "U_V36X_MY16_5_Diesel_Rx" SG_ 1069 EngClnt_Te_ActlDiag 1;
BA_ "U_P558_MY17_Diesel_Rx" SG_ 1069 EngClnt_Te_ActlDiag 1;
BA_ "U_CD4_MY17_Phev_Rx" SG_ 1069 EngClnt_Te_ActlDiag 1;
BA_ "U_CD4_MY17_Hev_Rx" SG_ 1069 EngClnt_Te_ActlDiag 1;
BA_ "U_CD4_MY17_Diesel_Rx" SG_ 1069 EngClnt_Te_ActlDiag 1;
BA_ "U_CD4_MY14_Phev_Rx" SG_ 1069 EngClnt_Te_ActlDiag 1;
BA_ "U_CD4_MY14_Hev_Rx" SG_ 1069 EngClnt_Te_ActlDiag 1;
BA_ "U_CD4_MY14_Diesel_Rx" SG_ 1069 EngClnt_Te_ActlDiag 1;
BA_ "U_UP375_MY15_Diesel_Rx" SG_ 1069 EngClnt_Te_ActlDiag 1;
BA_ "U_CD4_MY13_Phev_Rx" SG_ 1069 EngClnt_Te_ActlDiag 1;
BA_ "U_CD4_MY13_Hev_Rx" SG_ 1069 EngClnt_Te_ActlDiag 1;
BA_ "ContentDependant" SG_ 1069 EngClnt_Te_ActlDiag 1;
BA_ "CrossOver_InfoCAN" SG_ 1069 EngClnt_Te_ActlDiag 1;
BA_ "GenSigTimeoutTime_TCM" SG_ 1069 EngClnt_Te_ActlDiag 300;
BA_ "U_CD42_MY16_Diesel_Tx" SG_ 1069 ApedPos_Pc_ActlDiag 1;
BA_ "U_V36X_MY16_5_Diesel_Tx" SG_ 1069 ApedPos_Pc_ActlDiag 1;
BA_ "U_P558_MY17_Diesel_Tx" SG_ 1069 ApedPos_Pc_ActlDiag 1;
BA_ "U_CD4_MY17_Phev_Tx" SG_ 1069 ApedPos_Pc_ActlDiag 1;
BA_ "U_CD4_MY17_Hev_Tx" SG_ 1069 ApedPos_Pc_ActlDiag 1;
BA_ "U_CD4_MY14_Phev_Tx" SG_ 1069 ApedPos_Pc_ActlDiag 1;
BA_ "U_CD4_MY14_Hev_Tx" SG_ 1069 ApedPos_Pc_ActlDiag 1;
BA_ "U_CD4_MY14_Diesel_Tx" SG_ 1069 ApedPos_Pc_ActlDiag 1;
BA_ "U_UP375_MY15_Diesel_Tx" SG_ 1069 ApedPos_Pc_ActlDiag 1;
BA_ "U_CD4_MY13_Phev_Tx" SG_ 1069 ApedPos_Pc_ActlDiag 1;
BA_ "U_CD4_MY13_Hev_Tx" SG_ 1069 ApedPos_Pc_ActlDiag 1;
BA_ "U_CD42_MY16_Diesel_Rx" SG_ 1069 ApedPos_Pc_ActlDiag 1;
BA_ "U_V36X_MY16_5_Diesel_Rx" SG_ 1069 ApedPos_Pc_ActlDiag 1;
BA_ "U_P558_MY17_Diesel_Rx" SG_ 1069 ApedPos_Pc_ActlDiag 1;
BA_ "U_CD4_MY17_Phev_Rx" SG_ 1069 ApedPos_Pc_ActlDiag 1;
BA_ "U_CD4_MY17_Hev_Rx" SG_ 1069 ApedPos_Pc_ActlDiag 1;
BA_ "U_CD4_MY17_Diesel_Rx" SG_ 1069 ApedPos_Pc_ActlDiag 1;
BA_ "U_CD4_MY14_Phev_Rx" SG_ 1069 ApedPos_Pc_ActlDiag 1;
BA_ "U_CD4_MY14_Hev_Rx" SG_ 1069 ApedPos_Pc_ActlDiag 1;
BA_ "U_CD4_MY14_Diesel_Rx" SG_ 1069 ApedPos_Pc_ActlDiag 1;
BA_ "U_UP375_MY15_Diesel_Rx" SG_ 1069 ApedPos_Pc_ActlDiag 1;
BA_ "U_CD4_MY13_Phev_Rx" SG_ 1069 ApedPos_Pc_ActlDiag 1;
BA_ "U_CD4_MY13_Hev_Rx" SG_ 1069 ApedPos_Pc_ActlDiag 1;
BA_ "ContentDependant" SG_ 1069 ApedPos_Pc_ActlDiag 1;
BA_ "CrossOver_InfoCAN" SG_ 1069 ApedPos_Pc_ActlDiag 1;
BA_ "GenSigTimeoutTime_TCM" SG_ 1069 ApedPos_Pc_ActlDiag 300;
BA_ "CrossOver_InfoCAN" SG_ 1069 GrllShtrPos_D_Cmd 1;
BA_ "U_CD4_MY13_Phev_Rx" SG_ 1069 GrllShtrPos_D_Cmd 1;
BA_ "U_CD42_MY14_Diesel_Rx" SG_ 1069 GrllShtrPos_D_Cmd 1;
BA_ "U_CD42_MY14_Gas_Rx" SG_ 1069 GrllShtrPos_D_Cmd 1;
BA_ "U_P552_MY15_Gas_Rx" SG_ 1069 GrllShtrPos_D_Cmd 1;
BA_ "U_S550_MY15_Gas_Rx" SG_ 1069 GrllShtrPos_D_Cmd 1;
BA_ "U_C489_MY14_Gas_Rx" SG_ 1069 GrllShtrPos_D_Cmd 1;
BA_ "U_U502_MY15_Gas_Rx" SG_ 1069 GrllShtrPos_D_Cmd 1;
BA_ "U_UP375_MY15_Gas_Rx" SG_ 1069 GrllShtrPos_D_Cmd 1;
BA_ "U_UP375_MY15_Diesel_Rx" SG_ 1069 GrllShtrPos_D_Cmd 1;
BA_ "U_CD43_MY16_Gas_Rx" SG_ 1069 GrllShtrPos_D_Cmd 1;
BA_ "U_CD4_MY14_Diesel_Rx" SG_ 1069 GrllShtrPos_D_Cmd 1;
BA_ "U_CD4_MY14_Gas_Rx" SG_ 1069 GrllShtrPos_D_Cmd 1;
BA_ "U_CD4_MY14_Hev_Rx" SG_ 1069 GrllShtrPos_D_Cmd 1;
BA_ "U_CD4_MY14_Phev_Rx" SG_ 1069 GrllShtrPos_D_Cmd 1;
BA_ "U_CD4_MY13_Gas_Tx" SG_ 1069 GrllShtrPos_D_Cmd 1;
BA_ "U_CD42_MY14_Gas_Tx" SG_ 1069 GrllShtrPos_D_Cmd 1;
BA_ "U_P552_MY15_Gas_Tx" SG_ 1069 GrllShtrPos_D_Cmd 1;
BA_ "U_S550_MY15_Gas_Tx" SG_ 1069 GrllShtrPos_D_Cmd 1;
BA_ "U_C489_MY14_Gas_Tx" SG_ 1069 GrllShtrPos_D_Cmd 1;
BA_ "U_U502_MY15_Gas_Tx" SG_ 1069 GrllShtrPos_D_Cmd 1;
BA_ "U_UP375_MY15_Gas_Tx" SG_ 1069 GrllShtrPos_D_Cmd 1;
BA_ "U_CD43_MY16_Gas_Tx" SG_ 1069 GrllShtrPos_D_Cmd 1;
BA_ "U_CD4_MY14_Gas_Tx" SG_ 1069 GrllShtrPos_D_Cmd 1;
BA_ "CrossOver_InfoCAN" SG_ 1069 GrllShtrPos_B_Falt 1;
BA_ "U_CD4_MY13_Phev_Rx" SG_ 1069 GrllShtrPos_B_Falt 1;
BA_ "U_CD42_MY14_Diesel_Rx" SG_ 1069 GrllShtrPos_B_Falt 1;
BA_ "U_CD42_MY14_Gas_Rx" SG_ 1069 GrllShtrPos_B_Falt 1;
BA_ "U_P552_MY15_Gas_Rx" SG_ 1069 GrllShtrPos_B_Falt 1;
BA_ "U_S550_MY15_Gas_Rx" SG_ 1069 GrllShtrPos_B_Falt 1;
BA_ "U_C489_MY14_Gas_Rx" SG_ 1069 GrllShtrPos_B_Falt 1;
BA_ "U_U502_MY15_Gas_Rx" SG_ 1069 GrllShtrPos_B_Falt 1;
BA_ "U_UP375_MY15_Gas_Rx" SG_ 1069 GrllShtrPos_B_Falt 1;
BA_ "U_UP375_MY15_Diesel_Rx" SG_ 1069 GrllShtrPos_B_Falt 1;
BA_ "U_CD43_MY16_Gas_Rx" SG_ 1069 GrllShtrPos_B_Falt 1;
BA_ "U_CD4_MY14_Diesel_Rx" SG_ 1069 GrllShtrPos_B_Falt 1;
BA_ "U_CD4_MY14_Gas_Rx" SG_ 1069 GrllShtrPos_B_Falt 1;
BA_ "U_CD4_MY14_Hev_Rx" SG_ 1069 GrllShtrPos_B_Falt 1;
BA_ "U_CD4_MY14_Phev_Rx" SG_ 1069 GrllShtrPos_B_Falt 1;
BA_ "U_CD4_MY13_Gas_Tx" SG_ 1069 GrllShtrPos_B_Falt 1;
BA_ "U_CD42_MY14_Gas_Tx" SG_ 1069 GrllShtrPos_B_Falt 1;
BA_ "U_P552_MY15_Gas_Tx" SG_ 1069 GrllShtrPos_B_Falt 1;
BA_ "U_S550_MY15_Gas_Tx" SG_ 1069 GrllShtrPos_B_Falt 1;
BA_ "U_C489_MY14_Gas_Tx" SG_ 1069 GrllShtrPos_B_Falt 1;
BA_ "U_U502_MY15_Gas_Tx" SG_ 1069 GrllShtrPos_B_Falt 1;
BA_ "U_UP375_MY15_Gas_Tx" SG_ 1069 GrllShtrPos_B_Falt 1;
BA_ "U_CD43_MY16_Gas_Tx" SG_ 1069 GrllShtrPos_B_Falt 1;
BA_ "U_CD4_MY14_Gas_Tx" SG_ 1069 GrllShtrPos_B_Falt 1;
BA_ "CrossOver_InfoCAN" SG_ 1069 EngMsgTxt_D_Rq 1;
BA_ "ContentDependant" SG_ 1069 EngMsgTxt_D_Rq 1;
BA_ "U_CD4_MY13_Gas_Tx" SG_ 1069 EngMsgTxt_D_Rq 1;
BA_ "U_CD42_MY14_Gas_Tx" SG_ 1069 EngMsgTxt_D_Rq 1;
BA_ "U_P552_MY15_Gas_Tx" SG_ 1069 EngMsgTxt_D_Rq 1;
BA_ "U_S550_MY15_Gas_Tx" SG_ 1069 EngMsgTxt_D_Rq 1;
BA_ "U_C489_MY14_Gas_Tx" SG_ 1069 EngMsgTxt_D_Rq 1;
BA_ "U_U502_MY15_Gas_Tx" SG_ 1069 EngMsgTxt_D_Rq 1;
BA_ "U_UP375_MY15_Gas_Tx" SG_ 1069 EngMsgTxt_D_Rq 1;
BA_ "U_CD43_MY16_Gas_Tx" SG_ 1069 EngMsgTxt_D_Rq 1;
BA_ "U_CD4_MY14_Gas_Tx" SG_ 1069 EngMsgTxt_D_Rq 1;
BA_ "CrossOver_InfoCAN" SG_ 1069 EngAirIn_Te_Actl 1;
BA_ "U_CD4_MY13_Diesel_Rx" SG_ 1069 EngAirIn_Te_Actl 1;
BA_ "U_CD4_MY13_Gas_Rx" SG_ 1069 EngAirIn_Te_Actl 1;
BA_ "U_CD4_MY13_Hev_Rx" SG_ 1069 EngAirIn_Te_Actl 1;
BA_ "U_CD4_MY13_Phev_Rx" SG_ 1069 EngAirIn_Te_Actl 1;
BA_ "U_CD42_MY14_Diesel_Rx" SG_ 1069 EngAirIn_Te_Actl 1;
BA_ "U_CD42_MY14_Gas_Rx" SG_ 1069 EngAirIn_Te_Actl 1;
BA_ "U_P552_MY15_Gas_Rx" SG_ 1069 EngAirIn_Te_Actl 1;
BA_ "U_S550_MY15_Gas_Rx" SG_ 1069 EngAirIn_Te_Actl 1;
BA_ "U_C489_MY14_Gas_Rx" SG_ 1069 EngAirIn_Te_Actl 1;
BA_ "U_U502_MY15_Gas_Rx" SG_ 1069 EngAirIn_Te_Actl 1;
BA_ "U_UP375_MY15_Gas_Rx" SG_ 1069 EngAirIn_Te_Actl 1;
BA_ "U_UP375_MY15_Diesel_Rx" SG_ 1069 EngAirIn_Te_Actl 1;
BA_ "U_CD43_MY16_Gas_Rx" SG_ 1069 EngAirIn_Te_Actl 1;
BA_ "U_CD4_MY14_Diesel_Rx" SG_ 1069 EngAirIn_Te_Actl 1;
BA_ "U_CD4_MY14_Gas_Rx" SG_ 1069 EngAirIn_Te_Actl 1;
BA_ "U_CD4_MY14_Hev_Rx" SG_ 1069 EngAirIn_Te_Actl 1;
BA_ "U_CD4_MY14_Phev_Rx" SG_ 1069 EngAirIn_Te_Actl 1;
BA_ "U_CD4_MY13_Gas_Tx" SG_ 1069 EngAirIn_Te_Actl 1;
BA_ "U_CD42_MY14_Gas_Tx" SG_ 1069 EngAirIn_Te_Actl 1;
BA_ "U_P552_MY15_Gas_Tx" SG_ 1069 EngAirIn_Te_Actl 1;
BA_ "U_S550_MY15_Gas_Tx" SG_ 1069 EngAirIn_Te_Actl 1;
BA_ "U_C489_MY14_Gas_Tx" SG_ 1069 EngAirIn_Te_Actl 1;
BA_ "U_U502_MY15_Gas_Tx" SG_ 1069 EngAirIn_Te_Actl 1;
BA_ "U_UP375_MY15_Gas_Tx" SG_ 1069 EngAirIn_Te_Actl 1;
BA_ "U_CD43_MY16_Gas_Tx" SG_ 1069 EngAirIn_Te_Actl 1;
BA_ "U_CD4_MY14_Gas_Tx" SG_ 1069 EngAirIn_Te_Actl 1;
BA_ "GenSigTimeoutTime_TCM" SG_ 1069 EngAirIn_Te_Actl 300;
BA_ "U_CD4_MY13_Diesel_Rx" SG_ 118 EmgcyBrkLamp_D_Rq 1;
BA_ "U_CD4_MY13_Gas_Rx" SG_ 118 EmgcyBrkLamp_D_Rq 1;
BA_ "U_CD4_MY13_Hev_Rx" SG_ 118 EmgcyBrkLamp_D_Rq 1;
BA_ "U_CD4_MY13_Phev_Rx" SG_ 118 EmgcyBrkLamp_D_Rq 1;
BA_ "U_CD42_MY14_Diesel_Rx" SG_ 118 EmgcyBrkLamp_D_Rq 1;
BA_ "U_CD42_MY14_Gas_Rx" SG_ 118 EmgcyBrkLamp_D_Rq 1;
BA_ "U_P552_MY15_Gas_Rx" SG_ 118 EmgcyBrkLamp_D_Rq 1;
BA_ "U_S550_MY15_Gas_Rx" SG_ 118 EmgcyBrkLamp_D_Rq 1;
BA_ "U_C489_MY14_Gas_Rx" SG_ 118 EmgcyBrkLamp_D_Rq 1;
BA_ "U_U502_MY15_Gas_Rx" SG_ 118 EmgcyBrkLamp_D_Rq 1;
BA_ "U_UP375_MY15_Gas_Rx" SG_ 118 EmgcyBrkLamp_D_Rq 1;
BA_ "U_UP375_MY15_Diesel_Rx" SG_ 118 EmgcyBrkLamp_D_Rq 1;
BA_ "U_CD43_MY16_Gas_Rx" SG_ 118 EmgcyBrkLamp_D_Rq 1;
BA_ "U_CD4_MY14_Diesel_Rx" SG_ 118 EmgcyBrkLamp_D_Rq 1;
BA_ "U_CD4_MY14_Gas_Rx" SG_ 118 EmgcyBrkLamp_D_Rq 1;
BA_ "U_CD4_MY14_Hev_Rx" SG_ 118 EmgcyBrkLamp_D_Rq 1;
BA_ "U_CD4_MY14_Phev_Rx" SG_ 118 EmgcyBrkLamp_D_Rq 1;
BA_ "U_CD4_MY13_Diesel_Rx" SG_ 118 SteWhlComp_An_Est 1;
BA_ "U_CD4_MY13_Gas_Rx" SG_ 118 SteWhlComp_An_Est 1;
BA_ "U_CD4_MY13_Hev_Rx" SG_ 118 SteWhlComp_An_Est 1;
BA_ "U_CD4_MY13_Phev_Rx" SG_ 118 SteWhlComp_An_Est 1;
BA_ "U_CD42_MY14_Diesel_Rx" SG_ 118 SteWhlComp_An_Est 1;
BA_ "U_CD42_MY14_Gas_Rx" SG_ 118 SteWhlComp_An_Est 1;
BA_ "U_P552_MY15_Gas_Rx" SG_ 118 SteWhlComp_An_Est 1;
BA_ "U_S550_MY15_Gas_Rx" SG_ 118 SteWhlComp_An_Est 1;
BA_ "U_C489_MY14_Gas_Rx" SG_ 118 SteWhlComp_An_Est 1;
BA_ "U_U502_MY15_Gas_Rx" SG_ 118 SteWhlComp_An_Est 1;
BA_ "U_CD43_MY16_Gas_Rx" SG_ 118 SteWhlComp_An_Est 1;
BA_ "U_CD4_MY14_Gas_Rx" SG_ 118 SteWhlComp_An_Est 1;
BA_ "U_UP375_MY15_Gas_Rx" SG_ 118 SteWhlComp_An_Est 1;
BA_ "U_UP375_MY15_Diesel_Rx" SG_ 118 SteWhlComp_An_Est 1;
BA_ "U_CD4_MY14_Diesel_Rx" SG_ 118 SteWhlComp_An_Est 1;
BA_ "U_CD4_MY14_Hev_Rx" SG_ 118 SteWhlComp_An_Est 1;
BA_ "U_CD4_MY14_Phev_Rx" SG_ 118 SteWhlComp_An_Est 1;
BA_ "GenSigTimeoutTime_TCM" SG_ 118 SteWhlComp_An_Est 60;
BA_ "U_CD4_MY13_Diesel_Rx" SG_ 118 StopLamp_B_RqBrk 1;
BA_ "U_CD4_MY13_Gas_Rx" SG_ 118 StopLamp_B_RqBrk 1;
BA_ "U_CD4_MY13_Hev_Rx" SG_ 118 StopLamp_B_RqBrk 1;
BA_ "U_CD4_MY13_Phev_Rx" SG_ 118 StopLamp_B_RqBrk 1;
BA_ "U_CD42_MY14_Diesel_Rx" SG_ 118 StopLamp_B_RqBrk 1;
BA_ "U_CD42_MY14_Gas_Rx" SG_ 118 StopLamp_B_RqBrk 1;
BA_ "U_P552_MY15_Gas_Rx" SG_ 118 StopLamp_B_RqBrk 1;
BA_ "U_S550_MY15_Gas_Rx" SG_ 118 StopLamp_B_RqBrk 1;
BA_ "U_C489_MY14_Gas_Rx" SG_ 118 StopLamp_B_RqBrk 1;
BA_ "U_U502_MY15_Gas_Rx" SG_ 118 StopLamp_B_RqBrk 1;
BA_ "U_UP375_MY15_Gas_Rx" SG_ 118 StopLamp_B_RqBrk 1;
BA_ "U_UP375_MY15_Diesel_Rx" SG_ 118 StopLamp_B_RqBrk 1;
BA_ "U_CD43_MY16_Gas_Rx" SG_ 118 StopLamp_B_RqBrk 1;
BA_ "U_CD4_MY14_Diesel_Rx" SG_ 118 StopLamp_B_RqBrk 1;
BA_ "U_CD4_MY14_Gas_Rx" SG_ 118 StopLamp_B_RqBrk 1;
BA_ "U_CD4_MY14_Hev_Rx" SG_ 118 StopLamp_B_RqBrk 1;
BA_ "U_CD4_MY14_Phev_Rx" SG_ 118 StopLamp_B_RqBrk 1;
BA_ "U_CD4_MY13_Diesel_Rx" SG_ 118 SteWhlCompAnEst_D_Qf 1;
BA_ "U_CD4_MY13_Gas_Rx" SG_ 118 SteWhlCompAnEst_D_Qf 1;
BA_ "U_CD4_MY13_Hev_Rx" SG_ 118 SteWhlCompAnEst_D_Qf 1;
BA_ "U_CD4_MY13_Phev_Rx" SG_ 118 SteWhlCompAnEst_D_Qf 1;
BA_ "U_CD42_MY14_Diesel_Rx" SG_ 118 SteWhlCompAnEst_D_Qf 1;
BA_ "U_CD42_MY14_Gas_Rx" SG_ 118 SteWhlCompAnEst_D_Qf 1;
BA_ "U_P552_MY15_Gas_Rx" SG_ 118 SteWhlCompAnEst_D_Qf 1;
BA_ "U_S550_MY15_Gas_Rx" SG_ 118 SteWhlCompAnEst_D_Qf 1;
BA_ "U_C489_MY14_Gas_Rx" SG_ 118 SteWhlCompAnEst_D_Qf 1;
BA_ "U_U502_MY15_Gas_Rx" SG_ 118 SteWhlCompAnEst_D_Qf 1;
BA_ "U_CD43_MY16_Gas_Rx" SG_ 118 SteWhlCompAnEst_D_Qf 1;
BA_ "U_CD4_MY14_Gas_Rx" SG_ 118 SteWhlCompAnEst_D_Qf 1;
BA_ "U_UP375_MY15_Gas_Rx" SG_ 118 SteWhlCompAnEst_D_Qf 1;
BA_ "U_UP375_MY15_Diesel_Rx" SG_ 118 SteWhlCompAnEst_D_Qf 1;
BA_ "U_CD4_MY14_Diesel_Rx" SG_ 118 SteWhlCompAnEst_D_Qf 1;
BA_ "U_CD4_MY14_Hev_Rx" SG_ 118 SteWhlCompAnEst_D_Qf 1;
BA_ "U_CD4_MY14_Phev_Rx" SG_ 118 SteWhlCompAnEst_D_Qf 1;
BA_ "GenSigTimeoutTime_TCM" SG_ 118 SteWhlCompAnEst_D_Qf 60;
BA_ "CrossOver_InfoCAN" SG_ 118 VehDynamicsSOS 1;
BA_ "U_CD4_MY13_Diesel_Rx" SG_ 118 VehDynamicsSOS 1;
BA_ "U_CD4_MY13_Gas_Rx" SG_ 118 VehDynamicsSOS 1;
BA_ "U_CD4_MY13_Hev_Rx" SG_ 118 VehDynamicsSOS 1;
BA_ "U_CD4_MY13_Phev_Rx" SG_ 118 VehDynamicsSOS 1;
BA_ "U_CD42_MY14_Diesel_Rx" SG_ 118 VehDynamicsSOS 1;
BA_ "U_CD42_MY14_Gas_Rx" SG_ 118 VehDynamicsSOS 1;
BA_ "U_P552_MY15_Gas_Rx" SG_ 118 VehDynamicsSOS 1;
BA_ "U_S550_MY15_Gas_Rx" SG_ 118 VehDynamicsSOS 1;
BA_ "U_C489_MY14_Gas_Rx" SG_ 118 VehDynamicsSOS 1;
BA_ "U_U502_MY15_Gas_Rx" SG_ 118 VehDynamicsSOS 1;
BA_ "U_UP375_MY15_Gas_Rx" SG_ 118 VehDynamicsSOS 1;
BA_ "U_UP375_MY15_Diesel_Rx" SG_ 118 VehDynamicsSOS 1;
BA_ "U_CD43_MY16_Gas_Rx" SG_ 118 VehDynamicsSOS 1;
BA_ "U_CD4_MY14_Diesel_Rx" SG_ 118 VehDynamicsSOS 1;
BA_ "U_CD4_MY14_Gas_Rx" SG_ 118 VehDynamicsSOS 1;
BA_ "U_CD4_MY14_Hev_Rx" SG_ 118 VehDynamicsSOS 1;
BA_ "U_CD4_MY14_Phev_Rx" SG_ 118 VehDynamicsSOS 1;
VAL_ 1085 ULoRgenTestMde_B_Stat 1 "Active" 0 "Inactive" ;
VAL_ 1085 PwSrcULoOvrTe_B_Actl 1 "Yes" 0 "No" ;
VAL_ 1085 PwSrcULoFalt_D_Stat 3 "Fault_No_Output" 2 "Fault_Reduced_Output" 1 "Fault_NonSpecific" 0 "No_Fault" ;
VAL_ 1085 PwSrcULoDcnnt_B_Stat 1 "Loose_or_Disconnected" 0 "Connected" ;
VAL_ 1085 PwSrcULo_Pc_Mx 255 "Fault" ;
VAL_ 1085 PwSrcULoComm_B_Falt 1 "Fault" 0 "No_Fault" ;
VAL_ 1085 PwSrcULo_I_Mx 255 "Fault" ;
VAL_ 1085 PwSrcULo_I_Actl 255 "Fault" ;
VAL_ 891 TrlrAidMsgTxt_D_Rq_UB 1 "Fresh_data" 0 "Unchanged_data" ;
VAL_ 891 TrlrAidMsgTxt_D_Rq 31 "Message31" 30 "Message30" 29 "Message29" 28 "Message28" 27 "Message27" 26 "Message26" 25 "Message25" 24 "Message24" 23 "Message23" 22 "Message22" 21 "Message21" 20 "Message20" 19 "Message19" 18 "Message18" 17 "Message17" 16 "Message16" 15 "Message15" 14 "Message14" 13 "Message13" 12 "Message12" 11 "Message11" 10 "Message10" 9 "Message9" 8 "Message8" 7 "Message7" 6 "Message6" 5 "Message5" 4 "Message4" 3 "Message3" 2 "Message2" 1 "Message1" 0 "NoMessage" ;
VAL_ 891 TrlrBrkCtl_B_Falt_UB 1 "Fresh_data" 0 "Unchanged_data" ;
VAL_ 891 TrlrBrkActCirct_B_Falt_UB 1 "Fresh_data" 0 "Unchanged_data" ;
VAL_ 891 TrlrBrkCtl_B_Falt 1 "Yes" 0 "No" ;
VAL_ 891 TrlrBrkActCirct_B_Falt 1 "Yes" 0 "No" ;
VAL_ 130 VehVTrlrAid_B_Rq 1 "Request" 0 "NoRequest" ;
VAL_ 130 TrlrHitchLamp_D_Rqst 1 "On" 0 "Off" ;
VAL_ 130 SteMdule_D_Stat 7 "NotUsed" 6 "EPAS_Failure3" 5 "EPAS_Failure2" 4 "System_Failure" 3 "EPAS_Shutdown" 2 "Normal_Op_Full_Assist" 1 "Normal_Op_Limited_Assist" 0 "EPAS_Initialization" ;
VAL_ 130 DrvSteActv_B_Stat 1 "Active" 0 "Inactive" ;
VAL_ 130 DrvSte_Tq_Actl 255 "Invalid" 254 "Unknown" ;
VAL_ 130 SteMdule_U_Meas 255 "Invalid" ;
VAL_ 130 SteMdule_I_Est 4095 "Invalid" ;
VAL_ 130 EPAS_Failure 3 "SERVICE_POWER_STEERING_NOW" 2 "SERVICE_POWER_STEERING" 1 "POWER_STRG_ASSIST_FAULT" 0 "EPAS_OK_NO_MESSAGE" ;
VAL_ 130 SteeringColumnTorque 255 "Invalid" 254 "Unknown" ;
VAL_ 130 SAPPAngleControlStat6 1 "RequestedAngleNotReached" 0 "RequestedAngleCanBeReached" ;
VAL_ 130 SAPPAngleControlStat5 1 "StrgColTorqueExceed_EAROn" 0 "ExternalSigContentOKforEAC" ;
VAL_ 130 SAPPAngleControlStat4 1 "SpeedLimitExceededEAROn" 0 "ExternalSigContentOKforEAC" ;
VAL_ 130 SAPPAngleControlStat3 1 "EARactiveNoReverseEngage" 0 "ExternalSigContentOKforEAC" ;
VAL_ 130 SAPPAngleControlStat2 1 "Rel_ExtSteeringAngleReqx" 0 "NoRel_ExtSteeringAngleReqx" ;
VAL_ 130 SAPPAngleControlStat1 3 "Fault" 2 "Active" 1 "Open" 0 "Closed" ;
VAL_ 75 VedsPasKneeBag_D_Ltchd 7 "Fault" 6 "NotSupported" 5 "Unused_3" 4 "Unused_2" 3 "Unused_1" 2 "NotDeployed" 1 "Deployed" 0 "NoEvent" ;
VAL_ 75 VedsRw1mBckl_D_Ltchd 5 "Unused_3" 4 "Unused_2" 3 "Unused_1" 2 "NotBelted" 1 "Belted" 0 "NoEvent" 7 "Fault" 6 "NotSupported" ;
VAL_ 75 VedsRw1mBelt_D_Ltchd 7 "Fault" 6 "NotSupported" 5 "Unused_3" 4 "Unused_2" 3 "Unused_1" 2 "NotDeployed" 1 "Deployed" 0 "NoEvent" ;
VAL_ 75 VedsRw2pRib_D_Ltchd 7 "Fault" 6 "NotSupported" 5 "Unused_3" 4 "Unused_2" 3 "Unused_1" 2 "NotDeployed" 1 "Deployed" 0 "NoEvent" ;
VAL_ 75 VedsRw2dRib_D_Ltchd 7 "Fault" 6 "NotSupported" 5 "Unused_3" 4 "Unused_2" 3 "Unused_1" 2 "NotDeployed" 1 "Deployed" 0 "NoEvent" ;
VAL_ 75 VedsRw3pBckl_D_Ltchd 5 "Unused_3" 4 "Unused_2" 3 "Unused_1" 2 "NotBelted" 1 "Belted" 0 "NoEvent" 7 "Fault" 6 "NotSupported" ;
VAL_ 75 VedsRw3mBckl_D_Ltchd 5 "Unused_3" 4 "Unused_2" 3 "Unused_1" 2 "NotBelted" 1 "Belted" 0 "NoEvent" 7 "Fault" 6 "NotSupported" ;
VAL_ 75 VedsRw3dBckl_D_Ltchd 5 "Unused_3" 4 "Unused_2" 3 "Unused_1" 2 "NotBelted" 1 "Belted" 0 "NoEvent" 7 "Fault" 6 "NotSupported" ;
VAL_ 75 VedsRw2pBckl_D_Ltchd 5 "Unused_3" 4 "Unused_2" 3 "Unused_1" 2 "NotBelted" 1 "Belted" 0 "NoEvent" 7 "Fault" 6 "NotSupported" ;
VAL_ 75 VedsRw2mBckl_D_Ltchd 5 "Unused_3" 4 "Unused_2" 3 "Unused_1" 2 "NotBelted" 1 "Belted" 0 "NoEvent" 7 "Fault" 6 "NotSupported" ;
VAL_ 75 VedsRw2dBckl_D_Ltchd 5 "Unused_3" 4 "Unused_2" 3 "Unused_1" 2 "NotBelted" 1 "Belted" 0 "NoEvent" 7 "Fault" 6 "NotSupported" ;
VAL_ 75 VedsRw1PasChld_D_Ltchd 7 "Fault" 6 "NotSupported" 5 "Unused_3" 4 "Unused_2" 3 "Unused_1" 2 "ChildNotDetected" 1 "ChildDetected" 0 "NoEvent" ;
VAL_ 75 VedsRw1PasBckl_D_Ltchd 5 "Unused_3" 4 "Unused_2" 3 "Unused_1" 2 "NotBelted" 1 "Belted" 0 "NoEvent" 7 "Fault" 6 "NotSupported" ;
VAL_ 75 VedsRw1DrvBckl_D_Ltchd 5 "Unused_3" 4 "Unused_2" 3 "Unused_1" 2 "NotBelted" 1 "Belted" 0 "NoEvent" 7 "Fault" 6 "NotSupported" ;
VAL_ 74 VedsPasSideBag_D_Ltchd 7 "Fault" 6 "NotSupported" 5 "Unused_3" 4 "Unused_2" 3 "Unused_1" 2 "NotDeployed" 1 "Deployed" 0 "NoEvent" ;
VAL_ 74 VedsPasCrtnBag_D_Ltchd 7 "Fault" 6 "NotSupported" 5 "Unused_3" 4 "Unused_2" 3 "Unused_1" 2 "NotDeployed" 1 "Deployed" 0 "NoEvent" ;
VAL_ 74 VedsPasBelt_D_Ltchd 7 "Fault" 6 "NotSupported" 5 "Unused_3" 4 "Unused_2" 3 "Unused_1" 2 "NotDeployed" 1 "Deployed" 0 "NoEvent" ;
VAL_ 74 VedsPasBag_D_Ltchd 7 "Fault" 6 "NotSupported" 5 "Unused_3" 4 "Unused_2" 3 "Unused_1" 2 "NotDeployed" 1 "Deployed" 0 "NoEvent" ;
VAL_ 74 VedsMultiEvnt_D_Ltchd 7 "Fault" 6 "NotSupported" 5 "Unused_3" 4 "Unused_2" 3 "Unused_1" 2 "Yes" 1 "No" 0 "NoEvent" ;
VAL_ 74 VedsMaxDeltaV_D_Ltchd 0 "NoEvent" 255 "Fault" 254 "NotSupported" ;
VAL_ 74 VedsDrvKneeBag_D_Ltchd 7 "Fault" 6 "NotSupported" 5 "Unused_3" 4 "Unused_2" 3 "Unused_1" 2 "NotDeployed" 1 "Deployed" 0 "NoEvent" ;
VAL_ 74 VedsEvntType_D_Ltchd 7 "Fault" 6 "NotSupported" 5 "Unused" 4 "Rolllover" 3 "Rear" 2 "Side" 1 "Frontal" 0 "NoEvent" ;
VAL_ 74 VedsEvntRoll_D_Ltchd 7 "Fault" 6 "NotSupported" 5 "Unused_3" 4 "Unused_2" 3 "Unused_1" 2 "Yes" 1 "No" 0 "NoEvent" ;
VAL_ 74 VedsDrvSideBag_D_Ltchd 7 "Fault" 6 "NotSupported" 5 "Unused_3" 4 "Unused_2" 3 "Unused_1" 2 "NotDeployed" 1 "Deployed" 0 "NoEvent" ;
VAL_ 74 VedsDrvCrtnBag_D_Ltchd 7 "Fault" 6 "NotSupported" 5 "Unused_3" 4 "Unused_2" 3 "Unused_1" 2 "NotDeployed" 1 "Deployed" 0 "NoEvent" ;
VAL_ 74 VedsDrvBelt_D_Ltchd 7 "Fault" 6 "NotSupported" 5 "Unused_3" 4 "Unused_2" 3 "Unused_1" 2 "NotDeployed" 1 "Deployed" 0 "NoEvent" ;
VAL_ 74 VedsDrvBag_D_Ltchd 7 "Fault" 6 "NotSupported" 5 "Unused_3" 4 "Unused_2" 3 "Unused_1" 2 "NotDeployed" 1 "Deployed" 0 "NoEvent" ;
VAL_ 74 eCallNotification 3 "Not_Used" 2 "Active" 1 "Normal" 0 "Not_Supported" ;
VAL_ 1076 CenterStackRing_D_Actl 3 "LimitedOn" 2 "On" 1 "Off" 0 "Null" ;
VAL_ 1076 CenterStackRing_D_Actl_UB 1 "Fresh_data" 0 "Unchanged_data" ;
VAL_ 1076 EngIdlShutDown_B_RqDrv_UB 1 "Fresh_data" 0 "Unchanged_data" ;
VAL_ 1076 EngIdlShutDown_B_RqDrv 1 "Inhibit" 0 "No_Inibit" ;
VAL_ 1076 OdoTripRx_B_Actl 1 "Yes" 0 "No" ;
VAL_ 1076 FuelLvlWarn_D_Actl 3 "NotUsed" 2 "VeryLow" 1 "Low" 0 "OK" ;
VAL_ 1076 TirePReset_B_Rq_UB 1 "Fresh_data" 0 "Unchanged_data" ;
VAL_ 1076 DrTGate_D_Rq 3 "NotUsed" 2 "Closing" 1 "Opening" 0 "Not_Moving" ;
VAL_ 1076 DrTGate_D_Rq_UB 1 "Fresh_data" 0 "Unchanged_data" ;
VAL_ 1076 DieslFuelBio_B_ActlDrv 1 "Biodiesel_User" 0 "Non_Biodiesel_User" ;
VAL_ 1076 FuelSecndActv_B_Actl 1 "Yes" 0 "No" ;
VAL_ 1076 FUEL_SENSOR_NUM 1 "Dual_Sensors" 0 "Single_Sensor" ;
VAL_ 1076 WndwPsngrSide_D_Stat 3 "BothWindow_Operating" 2 "RearWindow_Operating" 1 "FrontWindow_Operating" 0 "NoWindows_Operating" ;
VAL_ 1076 WndwDrvSide_D_Stat 3 "BothWindow_Operating" 2 "RearWindow_Operating" 1 "FrontWindow_Operating" 0 "NoWindows_Operating" ;
VAL_ 1076 WndwPsngrSide_D_Stat_UB 1 "Fresh_data" 0 "Unchanged_data" ;
VAL_ 1076 WndwDrvSide_D_Stat_UB 1 "Fresh_data" 0 "Unchanged_data" ;
VAL_ 1076 TirePReset_B_Rq 1 "Reset" 0 "Null" ;
VAL_ 1072 DrvPerfMde_D_Rq_UB 1 "Fresh_data" 0 "Unchanged_data" ;
VAL_ 1072 DrvPerfMde_D_Rq 3 "Sport" 2 "Normal" 1 "NotUsed" 0 "NoModeSelected" ;
VAL_ 1072 ePRNDL_MODE_UB 1 "Fresh_data" 0 "Unchanged_data" ;
VAL_ 1072 NtrlTowMdeEnbl_B_RqDrv_UB 1 "Fresh_data" 0 "Unchanged_data" ;
VAL_ 1072 NtrlTowMdeEnbl_B_RqDrv 1 "Yes" 0 "No" ;
VAL_ 1072 Remote_Start_QuietMode_UB 1 "Fresh_data" 0 "Unchanged_data" ;
VAL_ 1072 Remote_Start_QuietMode 1 "Quiet" 0 "Not_Quiet" ;
VAL_ 1072 ParkDetect_Stat_UB 1 "Fresh_data" 0 "Unchanged_data" ;
VAL_ 1072 ParkDetect_Stat 1 "Park" 0 "Not_Park" ;
VAL_ 1072 TrlrLampCnnct_B_Actl_UB 1 "Fresh_data" 0 "Unchanged_data" ;
VAL_ 1072 StopLamp_B_RqTrlrBrk_UB 1 "Fresh_data" 0 "Unchanged_data" ;
VAL_ 1072 StopLamp_B_RqTrlrBrk 1 "Yes" 0 "No" ;
VAL_ 1072 OdometerMasterValue_UB 1 "Fresh_data" 0 "Unchanged_data" ;
VAL_ 1072 OdometerMasterValue 16777215 "Invalid" ;
VAL_ 1072 MetricActv_B_Actl 1 "Active" 0 "Inactive" ;
VAL_ 1072 FrostWarn_D_Stat 3 "NotUsed" 2 "On_Amber" 1 "On_Red" 0 "Off" ;
VAL_ 1072 ReducedGuard_D_Rq_UB 1 "Fresh_data" 0 "Unchanged_data" ;
VAL_ 1072 ReducedGuard_D_Rq 3 "NotUsed" 2 "On" 1 "Off" 0 "Null" ;
VAL_ 1072 ePRNDL_MODE 1 "On" 0 "Off" ;
VAL_ 1072 EngOilLife_B_RqReset 1 "Yes" 0 "No" ;
VAL_ 1072 Outside_Air_Temp_Stat_UB 1 "Fresh_data" 0 "Unchanged_data" ;
VAL_ 1072 Outside_Air_Temp_Stat 255 "Invalid" 254 "Unknown" ;
VAL_ 1072 KeyTypeChngMykey_D_Rq_UB 1 "Fresh_data" 0 "Unchanged_data" ;
VAL_ 1072 KeyTypeChngMykey_D_Rq 3 "Search_PE_BackupSlot" 2 "Clear_All_MyKeys" 1 "Request_New_MyKey" 0 "None" ;
VAL_ 1072 TrlrLampCnnct_B_Actl 1 "Yes" 0 "No" ;
VAL_ 1072 ManRgen_D_Rq 3 "NotUsed2" 2 "NotUsed1" 1 "CustInitManExhFilterClean" 0 "No_Customer_Request" ;
VAL_ 806 SnowPlowMde_B_Enbl 1 "Enable" 0 "Disable" ;
VAL_ 806 StopStrtDrvMde_B_RqBtn 1 "Pressed" 0 "Not_Pressed" ;
VAL_ 806 ClimtHeat_D_Rq 7 "NotUsed4" 6 "NotUsed3" 5 "NotUsed2" 4 "NotUsed1" 3 "Defrost_Defog" 2 "FastTempPullDownHeatingReq" 1 "OpportunisticHeatingReq" 0 "NoHeatingRequest" ;
VAL_ 806 ClimtCool_D_Rq 7 "NotUsed4" 6 "NotUsed3" 5 "NotUsed2" 4 "NotUsed1" 3 "Defrost_Defog" 2 "FastTempPullDownCoolReq" 1 "OpportunisticCoolingReq" 0 "NoCoolingRequest" ;
VAL_ 806 HvacEvap_Te_Actl 1023 "Fault" ;
VAL_ 806 HvacAirCond_B_Rq 1 "Yes" 0 "No" ;
VAL_ 806 ClimtDeltaLoad_Pw_Actl 63 "Faulty" 62 "NoDataExists" ;
VAL_ 806 ClimtPw_B_Rq 1 "Yes" 0 "No" ;
VAL_ 578 PtLatchActv_B_RqBcm 1 "On" 0 "Off" ;
VAL_ 578 immoSecureIdleMode 3 "NotUsed2" 2 "NotUsed1" 1 "Active" 0 "Inactive" ;
VAL_ 578 ReFuelSwtchStat_D_Actl 3 "NotUsed2" 2 "NotUsed1" 1 "On" 0 "Off" ;
VAL_ 578 FuelPumpPwr_D_Stat 7 "NotUsed3" 6 "NotUsed2" 5 "NotUsed1" 4 "Power_Off_Default" 3 "Power_Off_Command" 2 "Power_Off_Service" 1 "Power_Off_Impact" 0 "Power_On" ;
VAL_ 578 BattULo_U_Actl 255 "Fault" ;
VAL_ 578 PrkLckCtl_B_Enbl 1 "Enable" 0 "Disable" ;
VAL_ 578 PrkLckCtlMsgTxt_D_Rq 3 "BTSI_DI_3" 2 "BTSI_DI_2" 1 "BTSI_DI_1" 0 "Null_BTSI_DI" ;
VAL_ 578 BrkTrnShifLck_B_Stat 1 "Shift" 0 "NoShift" ;
VAL_ 578 PrkLckCtlUnlck_D_Stat 3 "Trans_And_Steer_Unlckd" 2 "Steering_Unlckd" 1 "Transmission_Unlckd" 0 "Null" ;
VAL_ 578 PrkLckCtlTow_B_Enbl 1 "Enable" 0 "Disable" ;
VAL_ 578 DriverCrankingReq 1 "Crank_Request" 0 "No_Crank_Request" ;
VAL_ 578 EngOff_T_Actl 65535 "Invalid" ;
VAL_ 578 DcacElPw_D_Rq 3 "NotUsed" 2 "AC_HighPower_Requested" 1 "AC_LowPower_Requested" 0 "AC_Power_NotRequested" ;
VAL_ 578 BattULo_I_Actl 16383 "Fault" ;
VAL_ 514 StrtrMtrDlyStrt_B_Stat 1 "Yes" 0 "No" ;
VAL_ 514 VehVTrlrAid_B_Avail 1 "Yes" 0 "No" ;
VAL_ 514 StrtrMtrCtlMsgTxt_D_Rq 15 "Message_15" 14 "Message_14" 13 "Message_13" 12 "Message_12" 11 "Message_11" 10 "Message_10" 9 "Message_9" 8 "Message_8" 7 "Message_7" 6 "Message_6" 5 "Message_5" 4 "Message_4" 3 "Message_3" 2 "Message_2" 1 "Message_1" 0 "NoMessage" ;
VAL_ 514 VehVActlEng_D_Qf 3 "OK" 2 "Not_Within_Specifications" 1 "No_Data_Exists" 0 "Faulty" ;
VAL_ 514 GearRvrse_D_Actl 7 "Fault" 6 "NotUsed_3" 5 "NotUsed_2" 4 "NotUsed_1" 3 "Active_confirmed" 2 "Active_not_confirmed" 1 "Inactive_confirmed" 0 "Inactive_not_confirmed" ;
VAL_ 1057 VehVLimStat_D_Actl 7 "Undefined_3" 6 "Undefined_2" 5 "Undefined_1" 4 "ASL_Fault_Condition" 3 "Active_and_Limiting" 2 "Active_but_Not_Limiting" 1 "Standby" 0 "Off" ;
VAL_ 1057 VehVLimActv_B_Actl 1 "Active" 0 "Inactive" ;
VAL_ 1057 EngIdlShutDwnTxt_D_Rq 3 "NotUsed" 2 "EngineShutdownOnPrevDrive" 1 "FeatureDisabledDueToFault" 0 "NoMessage" ;
VAL_ 1057 EngIdlShutDown_D_Stat 3 "Not_used" 2 "Engine_Shutdown" 1 "Initiated_Countdown" 0 "Normal_Operation" ;
VAL_ 1057 FUEL_ALCOHOL_PERCNT 255 "Invalid" ;
VAL_ 1057 ECMMILRequest 3 "Not_Used" 2 "Flash" 1 "On" 0 "Off" ;
VAL_ 1057 AirCondFluidHi_P_Actl 255 "Fault" 254 "Unknown" ;
VAL_ 1057 OilPressureWarning 1 "Low_Pressure_Lamp_On" 0 "Normal_Pressure_Lamp_Off" ;
VAL_ 1057 CoolantFanStepAct 31 "Unused7" 30 "Unused6" 29 "Unused5" 28 "Unused4" 27 "Unused3" 26 "Unused2" 25 "Unused1" 23 "Step23" 22 "Step22" 21 "Step21" 20 "Step20" 19 "Step19" 18 "Step18" 17 "Step17" 16 "Step16" 15 "Step15" 14 "Step14" 13 "Step13" 12 "Step12" 11 "Step11" 10 "Step10" 9 "Step9" 8 "Step8" 7 "Step7" 6 "Step6" 5 "Step5" 4 "Step4" 3 "Step3" 2 "Step2" 1 "Step1" 24 "Max_Fan_Speed_Req" 0 "Fan_Cmd_Off" ;
VAL_ 1069 GrllShtrPos_D_Cmd 15 "Fully_Open" 14 "Position14" 13 "Position13" 12 "Position12" 11 "Position11" 10 "Position10" 9 "Position9" 8 "Position8" 7 "Position7" 6 "Position6" 5 "Position5" 4 "Position4" 3 "Position3" 2 "Position2" 1 "Position1" 0 "Fully_Closed" ;
VAL_ 1069 GrllShtrPos_B_Falt 1 "Fault" 0 "No_Fault" ;
VAL_ 1069 EngMsgTxt_D_Rq 3 "Undefined_2" 2 "Undefined_1" 1 "Power_Reduced_to_LowerTemp" 0 "No_Message" ;
VAL_ 1069 EngAirIn_Te_Actl 1023 "Fault" 1022 "Unknown" ;
VAL_ 118 BrkCtrFnd_B_Stat 1 "Yes" 0 "No" ;
VAL_ 118 EmgcyBrkLamp_D_Rq 3 "NotUsed" 2 "Active_at_standstill" 1 "Active_at_speed" 0 "Inactive" ;
VAL_ 118 StopLamp_B_RqBrk 1 "Active" 0 "Inactive" ;
VAL_ 118 SteWhlCompAnEst_D_Qf 3 "OK" 2 "Not_Within_Specifications" 1 "No_Data_Exists" 0 "Faulty" ;
VAL_ 118 VehDynamicsSOS 1 "Yes" 0 "No" ;
